VERSION ""

NS_ :

BS_:

BU_: AAF AAF_Tester ABS ACU ADRV AEMC AFLS AHLS APRK AVM BCM CAMERA CGW CLU CUBIS DATC DI_BOX Dummy ECS EMS EPB ESC EVP FATC FPCM FRONT_RADAR HUD IAP IBOX LCA LDWS_LKAS LPI LVR MDPS MTS ODS OPI PGS PSB REA SAS SCC SMK SNV SPAS TCU TMU TPMS _4WD

BS_:

BU_: XXX CAMERA FRONT_RADAR ADRV APRK

BS_:

BU_: IAP ODS _4WD BCM HUD DATC MDPS AAF_Tester AEMC SMK _4WD EPB CUBIS MTS TMU EVP CGW TPMS LPI DI_BOX SPAS EMS LCA TCU IBOX FATC AFLS FPCM SCC AHLS AVM ABS SNV OPI PGS SAS AAF Dummy LDWS_LKAS LVR ESC PSB CLU ECS ACU REA

BO_ 1318 HU_GW_E_00: 8 CLU
 SG_ C_ADrLURValueReq : 0|2@1+ (1.0,0.0) [0.0|3.0] ""  BCM
 SG_ C_TwUnRValueReq : 2|2@1+ (1.0,0.0) [0.0|3.0] ""  BCM
 SG_ C_AlarmRValueReq : 4|2@1+ (1.0,0.0) [0.0|3.0] ""  BCM
 SG_ C_IMSRValueReq : 6|2@1+ (1.0,0.0) [0.0|3.0] ""  BCM
 SG_ C_HLEscortRValueReq : 8|2@1+ (1.0,0.0) [0.0|3.0] ""  BCM
 SG_ C_WELRValueReq : 10|2@1+ (1.0,0.0) [0.0|3.0] ""  BCM
 SG_ C_TriTurnLRValueReq : 12|2@1+ (1.0,0.0) [0.0|3.0] ""  BCM
 SG_ C_SNVWarnRValueReq : 14|2@1+ (1.0,0.0) [0.0|3.0] ""  BCM
 SG_ C_LkasWarnRValueReq : 16|2@1+ (1.0,0.0) [0.0|3.0] ""  BCM

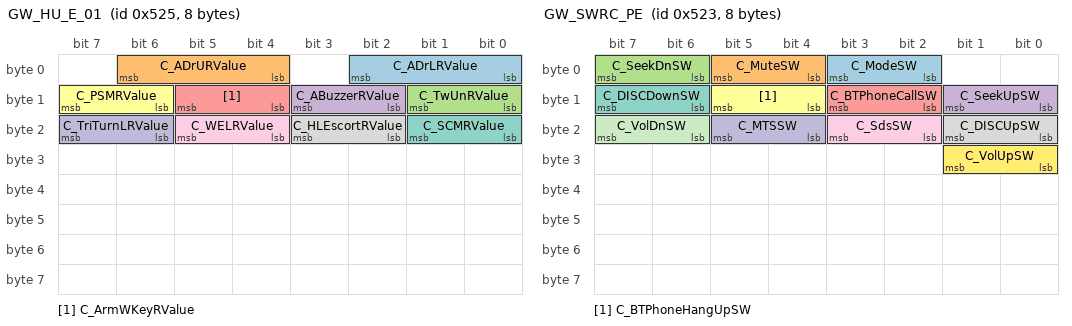
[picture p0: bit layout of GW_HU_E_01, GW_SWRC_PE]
BO_ 1317 GW_HU_E_01: 8 BCM
 SG_ C_ADrLRValue : 0|3@1+ (1.0,0.0) [0.0|7.0] ""  CLU
 SG_ C_ADrURValue : 4|3@1+ (1.0,0.0) [0.0|7.0] ""  CLU
 SG_ C_TwUnRValue : 8|2@1+ (1.0,0.0) [0.0|3.0] ""  CLU
 SG_ C_ABuzzerRValue : 10|2@1+ (1.0,0.0) [0.0|3.0] ""  CLU
 SG_ C_ArmWKeyRValue : 12|2@1+ (1.0,0.0) [0.0|3.0] ""  CLU
 SG_ C_PSMRValue : 14|2@1+ (1.0,0.0) [0.0|3.0] ""  CLU
 SG_ C_SCMRValue : 16|2@1+ (1.0,0.0) [0.0|3.0] ""  CLU
 SG_ C_HLEscortRValue : 18|2@1+ (1.0,0.0) [0.0|3.0] ""  CLU
 SG_ C_WELRValue : 20|2@1+ (1.0,0.0) [0.0|3.0] ""  CLU
 SG_ C_TriTurnLRValue : 22|2@1+ (1.0,0.0) [0.0|3.0] ""  CLU

BO_ 1316 GW_HU_E_00: 8 BCM
 SG_ C_ADrLUNValueConf : 0|2@1+ (1.0,0.0) [0.0|3.0] ""  CLU
 SG_ C_TwUnNValueConf : 2|2@1+ (1.0,0.0) [0.0|3.0] ""  CLU
 SG_ C_AlarmNValueConf : 4|2@1+ (1.0,0.0) [0.0|3.0] ""  CLU
 SG_ C_PSMNValueConf : 6|2@1+ (1.0,0.0) [0.0|3.0] ""  CLU
 SG_ C_SCMNValueConf : 8|2@1+ (1.0,0.0) [0.0|3.0] ""  CLU
 SG_ C_HLEscortNValueConf : 10|2@1+ (1.0,0.0) [0.0|3.0] ""  CLU
 SG_ C_WELNValueConf : 12|2@1+ (1.0,0.0) [0.0|3.0] ""  CLU
 SG_ C_TriTurnLNValueConf : 14|2@1+ (1.0,0.0) [0.0|3.0] ""  CLU

BO_ 1315 GW_SWRC_PE: 8 BCM
 SG_ C_ModeSW : 2|2@1+ (1.0,0.0) [0.0|3.0] ""  CLU
 SG_ C_MuteSW : 4|2@1+ (1.0,0.0) [0.0|3.0] ""  CLU
 SG_ C_SeekDnSW : 6|2@1+ (1.0,0.0) [0.0|3.0] ""  CLU
 SG_ C_SeekUpSW : 8|2@1+ (1.0,0.0) [0.0|3.0] ""  CLU
 SG_ C_BTPhoneCallSW : 10|2@1+ (1.0,0.0) [0.0|3.0] ""  CLU
 SG_ C_BTPhoneHangUpSW : 12|2@1+ (1.0,0.0) [0.0|3.0] ""  CLU
 SG_ C_DISCDownSW : 14|2@1+ (1.0,0.0) [0.0|3.0] ""  CLU
 SG_ C_DISCUpSW : 16|2@1+ (1.0,0.0) [0.0|3.0] ""  CLU
 SG_ C_SdsSW : 18|2@1+ (1.0,0.0) [0.0|3.0] ""  CLU
 SG_ C_MTSSW : 20|2@1+ (1.0,0.0) [0.0|3.0] ""  CLU
 SG_ C_VolDnSW : 22|2@1+ (1.0,0.0) [0.0|3.0] ""  CLU
 SG_ C_VolUpSW : 24|2@1+ (1.0,0.0) [0.0|3.0] ""  CLU

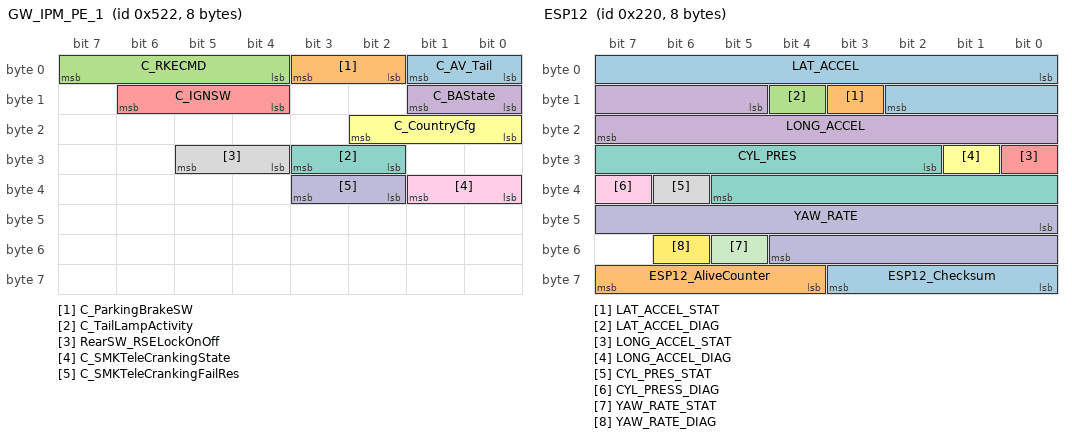
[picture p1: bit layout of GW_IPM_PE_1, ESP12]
BO_ 1314 GW_IPM_PE_1: 8 BCM
 SG_ C_AV_Tail : 0|2@1+ (1.0,0.0) [0.0|3.0] ""  CLU
 SG_ C_ParkingBrakeSW : 2|2@1+ (1.0,0.0) [0.0|3.0] ""  CLU
 SG_ C_RKECMD : 4|4@1+ (1.0,0.0) [0.0|15.0] ""  CLU
 SG_ C_BAState : 8|2@1+ (1.0,0.0) [0.0|3.0] ""  CLU
 SG_ C_IGNSW : 12|3@1+ (1.0,0.0) [0.0|7.0] ""  CLU
 SG_ C_CountryCfg : 16|3@1+ (1.0,0.0) [0.0|7.0] ""  CLU
 SG_ C_TailLampActivity : 26|2@1+ (1.0,0.0) [0.0|3.0] ""  CLU
 SG_ RearSW_RSELockOnOff : 28|2@1+ (1.0,0.0) [0.0|3.0] ""  CLU
 SG_ C_SMKTeleCrankingState : 32|2@1+ (1.0,0.0) [0.0|3.0] ""  CLU
 SG_ C_SMKTeleCrankingFailRes : 34|2@1+ (1.0,0.0) [0.0|3.0] ""  CLU

BO_ 1057 SCC12: 8 SCC
 SG_ CF_VSM_Prefill : 0|1@1+ (1,0) [0|1] "" ESC
 SG_ CF_VSM_DecCmdAct : 1|1@1+ (1,0) [0|1] "" ESC
 SG_ CF_VSM_HBACmd : 2|2@1+ (1,0) [0|3] "" ESC
 SG_ CF_VSM_Warn : 4|2@1+ (1,0) [0|3] "" CLU,ESC,IAP
 SG_ CF_VSM_Stat : 6|2@1+ (1,0) [0|3] "" CLU,ESC,PSB
 SG_ CF_VSM_BeltCmd : 8|3@1+ (1,0) [0|7] "" ESC,PSB
 SG_ ACCFailInfo : 11|2@1+ (1,0) [0|3] "" CLU,CUBIS,ESC,IBOX
 SG_ ACCMode : 13|2@1+ (1,0) [0|3] "" CLU,ESC,IBOX,TCU
 SG_ StopReq : 15|1@1+ (1,0) [0|1] "" EPB,ESC
 SG_ CR_VSM_DecCmd : 16|8@1+ (0.01,0) [0|2.55] "g" ESC
 SG_ TakeOverReq : 35|1@1+ (1,0) [0|1] "" CLU,ESC,TCU
 SG_ PreFill : 36|1@1+ (1,0) [0|1] "" ESC,TCU
 SG_ CF_VSM_ConfMode : 48|2@1+ (1,0) [0|3] "" CLU,ESC
 SG_ AEB_Failinfo : 50|2@1+ (1,0) [0|3] "" CLU,ESC
 SG_ AEB_Status : 52|2@1+ (1,0) [0|3] "" CLU,ESC
 SG_ AEB_CmdAct : 54|1@1+ (1,0) [0|1] "" ESC
 SG_ AEB_StopReq : 55|1@1+ (1,0) [0|1] "" CLU,ESC
 SG_ CR_VSM_Alive : 56|4@1+ (1,0) [0|15] "" ESC,PSB
 SG_ CR_VSM_ChkSum : 60|4@1+ (1,0) [0|15] "" ESC,PSB
 SG_ aReqValue : 37|11@1+ (0.01,-10.23) [-10.23|10.24] "m/s^2" Vector__XXX
 SG_ aReqRaw : 24|11@1+ (0.01,-10.23) [-10.23|10.24] "m/s^2" Vector__XXX

BO_ 1313 GW_DDM_PE: 8 BCM
 SG_ C_DRVDoorStatus : 0|2@1+ (1.0,0.0) [0.0|3.0] ""  CLU
 SG_ C_ASTDoorStatus : 2|2@1+ (1.0,0.0) [0.0|3.0] ""  CLU
 SG_ C_RLDoorStatus : 4|2@1+ (1.0,0.0) [0.0|3.0] ""  CLU
 SG_ C_RRDoorStatus : 6|2@1+ (1.0,0.0) [0.0|3.0] ""  CLU
 SG_ C_TrunkStatus : 8|2@1+ (1.0,0.0) [0.0|3.0] ""  CLU
 SG_ C_OSMirrorStatus : 10|2@1+ (1.0,0.0) [0.0|3.0] ""  CLU

BO_ 1056 SCC11: 8 SCC
 SG_ MainMode_ACC : 0|1@1+ (1,0) [0|1] "" CLU,EMS,ESC
 SG_ SCCInfoDisplay : 1|3@1+ (1,0) [0|7] "" CLU,ESC
 SG_ AliveCounterACC : 4|4@1+ (1,0) [0|15] "" CLU,EMS,ESC,TCU
 SG_ VSetDis : 8|8@1+ (1,0) [0|255] "km/h or MPH" CLU,ESC,TCU
 SG_ ObjValid : 16|1@1+ (1,0) [0|1] "" CLU,ESC,TCU
 SG_ DriverAlertDisplay : 17|2@1+ (1,0) [0|3] "" CLU,ESC
 SG_ TauGapSet : 19|3@1+ (1,0) [0|7] "" CLU,ESC,TCU
 SG_ Navi_SCC_Curve_Status : 56|2@1+ (1,0) [0|3] "" CLU
 SG_ Navi_SCC_Curve_Act : 58|2@1+ (1,0) [0|3] "" CLU
 SG_ Navi_SCC_Camera_Act : 60|2@1+ (1,0) [0|3] "" CLU
 SG_ Navi_SCC_Camera_Status : 62|2@1+ (1,0) [0|3] "" CLU
 SG_ ACC_ObjStatus : 22|2@1+ (1,0) [0|3] "" ABS,ESC
 SG_ ACC_ObjLatPos : 24|9@1+ (0.1,-20) [-20|31.1] "m" ABS,ESC
 SG_ ACC_ObjRelSpd : 44|12@1+ (0.1,-170) [-170|239.5] "m/s" ABS,ESC
 SG_ ACC_ObjDist : 33|11@1+ (0.1,0) [0|204.7] "m" ABS,ESC

BO_ 1312 CGW3: 8 BCM
 SG_ CR_Photosensor_LH : 0|8@1+ (78.125,0.0) [0.0|20000.0] ""  DATC,DATC
 SG_ CR_Photosensor_RH : 10|8@1+ (78.125,0.0) [0.0|20000.0] ""  DATC,DATC
 SG_ CF_Hoodsw_memory : 22|2@1+ (1.0,0.0) [0.0|3.0] ""  EMS,EMS
 SG_ C_MirOutTempSns : 24|8@1+ (0.5,-40.5) [-40.0|60.0] "deg"  AAF,CLU,DATC,EMS,SPAS,AAF,DATC,EMS,SPAS

BO_ 544 ESP12: 8 ESC
 SG_ LAT_ACCEL : 0|11@1+ (0.01,-10.23) [-10.23|10.24] "m/s^2"  _4WD,ECS,IBOX,LCA,LDWS_LKAS,MDPS,PSB,SCC,TCU
 SG_ LAT_ACCEL_STAT : 11|1@1+ (1.0,0.0) [0.0|1.0] ""  _4WD,IBOX,LDWS_LKAS,MDPS,PSB,SCC,TCU
 SG_ LAT_ACCEL_DIAG : 12|1@1+ (1.0,0.0) [0.0|1.0] ""  _4WD,IBOX,LDWS_LKAS,MDPS,PSB,SCC,TCU
 SG_ LONG_ACCEL : 13|11@1+ (0.01,-10.23) [-10.23|10.24] "m/s^2"  _4WD,ECS,EMS,EPB,IBOX,LCA,LDWS_LKAS,PSB,SCC,SPAS,TCU
 SG_ LONG_ACCEL_STAT : 24|1@1+ (1.0,0.0) [0.0|1.0] ""  _4WD,EMS,EPB,IBOX,LDWS_LKAS,PSB,SCC,SPAS,TCU
 SG_ LONG_ACCEL_DIAG : 25|1@1+ (1.0,0.0) [0.0|1.0] ""  _4WD,EMS,EPB,IBOX,LDWS_LKAS,PSB,SCC,SPAS,TCU
 SG_ CYL_PRES : 26|12@1+ (0.1,0.0) [0.0|409.5] "Bar"  _4WD,ECS,EMS,EPB,IBOX,LDWS_LKAS,PSB,SCC,TCU
 SG_ CYL_PRES_STAT : 38|1@1+ (1.0,0.0) [0.0|1.0] ""  _4WD,ECS,EMS,EPB,IBOX,LDWS_LKAS,PSB,SCC,TCU
 SG_ CYL_PRESS_DIAG : 39|1@1+ (1.0,0.0) [0.0|1.0] ""  _4WD,ECS,EMS,EPB,IBOX,PSB,SCC,TCU
 SG_ YAW_RATE : 40|13@1+ (0.01,-40.95) [-40.95|40.96] ""  _4WD,AFLS,IBOX,LCA,LDWS_LKAS,MDPS,PSB,SCC,SPAS,TCU
 SG_ YAW_RATE_STAT : 53|1@1+ (1.0,0.0) [0.0|1.0] ""  _4WD,AFLS,IBOX,LCA,LDWS_LKAS,MDPS,PSB,SCC,SPAS,TCU
 SG_ YAW_RATE_DIAG : 54|1@1+ (1.0,0.0) [0.0|1.0] ""  _4WD,AFLS,IBOX,LCA,LDWS_LKAS,MDPS,PSB,SCC,SPAS,TCU
 SG_ ESP12_Checksum : 56|4@1+ (1.0,0.0) [0.0|15.0] ""  _4WD,EMS,LPI,TCU,TMU
 SG_ ESP12_AliveCounter : 60|4@1+ (1.0,0.0) [0.0|15.0] ""  _4WD,EMS,LPI,TCU,TMU

BO_ 1307 CLU16: 8 CLU
 SG_ CF_Clu_TirePressUnitNValueSet : 0|3@1+ (1.0,0.0) [0.0|7.0] ""  TPMS
 SG_ CF_Clu_SlifNValueSet : 3|2@1+ (1.0,0.0) [0.0|3.0] ""  LDWS_LKAS
 SG_ CF_Clu_RearWiperNValueSet : 12|2@1+ (1.0,0.0) [0.0|3.0] ""  BCM

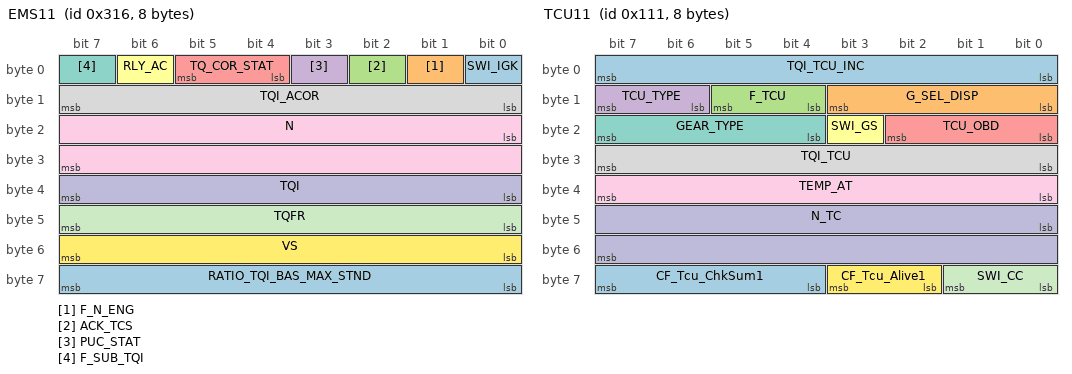
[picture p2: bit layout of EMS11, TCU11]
BO_ 790 EMS11: 8 EMS
 SG_ SWI_IGK : 0|1@1+ (1.0,0.0) [0.0|1.0] ""  _4WD,ABS,ACU,AHLS,CUBIS,DI_BOX,ECS,EPB,ESC,IBOX,LDWS_LKAS,MDPS,REA,SAS,SCC,TCU
 SG_ F_N_ENG : 1|1@1+ (1.0,0.0) [0.0|1.0] ""  _4WD,ACU,AFLS,CLU,CUBIS,DATC,ECS,EPB,ESC,IBOX,MDPS,SCC,TCU
 SG_ ACK_TCS : 2|1@1+ (1.0,0.0) [0.0|1.0] ""  ESC,IBOX
 SG_ PUC_STAT : 3|1@1+ (1.0,0.0) [0.0|1.0] ""  _4WD,CLU,DATC,IBOX,TCU
 SG_ TQ_COR_STAT : 4|2@1+ (1.0,0.0) [0.0|3.0] ""  _4WD,ESC,IBOX,TCU
 SG_ RLY_AC : 6|1@1+ (1.0,0.0) [0.0|1.0] ""  DATC,IBOX,TCU
 SG_ F_SUB_TQI : 7|1@1+ (1.0,0.0) [0.0|1.0] ""  _4WD,ECS,EPB,ESC,IBOX,TCU
 SG_ TQI_ACOR : 8|8@1+ (0.390625,0.0) [0.0|99.6094] "%"  _4WD,EPB,ESC,IBOX,TCU
 SG_ N : 16|16@1+ (0.25,0.0) [0.0|16383.75] "rpm"  _4WD,ACU,AFLS,CLU,CUBIS,DATC,ECS,EPB,ESC,FPCM,IBOX,MDPS,SCC,TCU
 SG_ TQI : 32|8@1+ (0.390625,0.0) [0.0|99.6094] "%"  _4WD,ECS,EPB,ESC,IBOX,TCU
 SG_ TQFR : 40|8@1+ (0.390625,0.0) [0.0|99.6094] "%"  _4WD,EPB,ESC,IBOX,TCU
 SG_ VS : 48|8@1+ (1.0,0.0) [0.0|254.0] "km/h"  _4WD,AAF,ACU,AHLS,BCM,CLU,DATC,ECS,EPB,IBOX,LCA,LDWS_LKAS,LVR,MDPS,ODS,SCC,SMK,SPAS,TCU,TPMS
 SG_ RATIO_TQI_BAS_MAX_STND : 56|8@1+ (0.0078,0.0) [0.0|2.0] ""  _4WD,IBOX,TCU

BO_ 1301 CLU14: 8 CLU
 SG_ CF_Clu_ADrUNValueSet : 0|3@1+ (1.0,0.0) [0.0|7.0] ""  BCM
 SG_ CF_Clu_ADrLNValueSet : 3|3@1+ (1.0,0.0) [0.0|7.0] ""  BCM
 SG_ CF_Clu_EscortHLNValueSet : 6|2@1+ (1.0,0.0) [0.0|3.0] ""  BCM
 SG_ CF_Clu_DoorLSNValueSet : 8|3@1+ (1.0,0.0) [0.0|7.0] ""  BCM
 SG_ CF_Clu_PSMNValueSet : 11|3@1+ (1.0,0.0) [0.0|7.0] ""  BCM
 SG_ CF_Clu_TTUnlockNValueSet : 14|2@1+ (1.0,0.0) [0.0|3.0] ""  BCM
 SG_ CF_Clu_PTGMNValueSet : 16|2@1+ (1.0,0.0) [0.0|3.0] ""  BCM
 SG_ CF_Clu_SCMNValueSet : 18|2@1+ (1.0,0.0) [0.0|3.0] ""  BCM
 SG_ CF_Clu_WlightNValueSet : 20|2@1+ (1.0,0.0) [0.0|3.0] ""  BCM
 SG_ CF_Clu_TempUnitNValueSet : 22|2@1+ (1.0,0.0) [0.0|3.0] ""  BCM,DATC
 SG_ CF_Clu_MoodLpNValueSet : 24|3@1+ (1.0,0.0) [0.0|7.0] ""  BCM
 SG_ CF_Clu_TrfChgSet : 27|2@1+ (1.0,0.0) [0.0|3.0] ""  AFLS
 SG_ CF_Clu_OTTurnNValueSet : 29|3@1+ (1.0,0.0) [0.0|7.0] ""  BCM
 SG_ CF_Clu_LcaNValueSet : 32|2@1+ (1.0,0.0) [0.0|3.0] ""  LCA
 SG_ CF_Clu_RctaNValueSet : 34|2@1+ (1.0,0.0) [0.0|3.0] ""  LCA
 SG_ CF_Clu_RcwNValueSet : 36|2@1+ (1.0,0.0) [0.0|3.0] ""  LCA
 SG_ CF_Clu_EscOffNValueSet : 38|3@1+ (1.0,0.0) [0.0|7.0] ""  ESC
 SG_ CF_Clu_SccNaviCrvNValueSet : 41|2@1+ (1.0,0.0) [0.0|3.0] ""  SCC
 SG_ CF_Clu_SccNaviCamNValueSet : 43|2@1+ (1.0,0.0) [0.0|3.0] ""  SCC
 SG_ CF_Clu_SccAebNValueSet : 45|2@1+ (1.0,0.0) [0.0|3.0] ""  SCC
 SG_ CF_Clu_LkasModeNValueSet : 47|2@1+ (1.0,0.0) [0.0|3.0] ""  LDWS_LKAS
 SG_ CF_Clu_FcwNValueSet : 51|2@1+ (1.0,0.0) [0.0|3.0] ""  LDWS_LKAS
 SG_ CF_Clu_PasSpkrLvNValueSet : 53|3@1+ (1.0,0.0) [0.0|7.0] ""  BCM
 SG_ CF_Clu_SccDrvModeNValueSet : 56|3@1+ (1.0,0.0) [0.0|7.0] ""  SCC
 SG_ CF_Clu_HAnBNValueSet : 59|2@1+ (1.0,0.0) [0.0|3.0] ""  BCM
 SG_ CF_Clu_HfreeTrunkTgNValueSet : 61|3@1+ (1.0,0.0) [0.0|7.0] ""  BCM

BO_ 275 TCU13: 8 TCU
 SG_ N_TGT_LUP : 0|8@1+ (10.0,500.0) [500.0|3040.0] "rpm"  EMS,IBOX
 SG_ SLOPE_TCU : 8|6@1+ (0.5,-16.0) [-16.0|15.5] "%"  CLU,CUBIS,EMS,IBOX
 SG_ CF_Tcu_InhCda : 14|1@1+ (1.0,0.0) [0.0|1.0] ""  EMS,IBOX
 SG_ CF_Tcu_IsgInhib : 15|1@1+ (1.0,0.0) [0.0|1.0] ""  EMS,IBOX
 SG_ CF_Tcu_BkeOnReq : 16|2@1+ (1.0,0.0) [0.0|3.0] ""  EMS,IBOX
 SG_ CF_Tcu_NCStat : 18|2@1+ (1.0,0.0) [0.0|3.0] ""  EMS,IBOX
 SG_ CF_Tcu_TarGr : 20|4@1+ (1.0,0.0) [0.0|15.0] ""  _4WD,CLU,DATC,EMS,EPB,ESC,IBOX,SCC
 SG_ CF_Tcu_ShfPatt : 24|4@1+ (1.0,0.0) [0.0|15.0] ""  CLU,CUBIS,EMS,IBOX
 SG_ CF_Tcu_InhVis : 28|1@1+ (1.0,0.0) [0.0|1.0] ""  EMS,IBOX
 SG_ CF_Tcu_PRelReq : 29|1@1+ (1.0,0.0) [0.0|1.0] ""  IBOX,LVR
 SG_ CF_Tcu_ITPhase : 30|1@1+ (1.0,0.0) [0.0|1.0] ""  EMS,IBOX
 SG_ CF_Tcu_ActEcoRdy : 31|1@1+ (1.0,0.0) [0.0|1.0] ""  EMS,IBOX
 SG_ CF_Tcu_TqGrdLim : 32|8@1+ (10.0,0.0) [0.0|2540.0] "Nm/s"  EMS,IBOX
 SG_ CR_Tcu_IsgTgtRPM : 40|8@1+ (20.0,0.0) [0.0|3500.0] "rpm"  EMS,IBOX
 SG_ CF_Tcu_SptRdy : 48|1@1+ (1.0,0.0) [0.0|1.0] ""  CLU,IBOX
 SG_ CF_Tcu_SbwPInfo : 56|1@1+ (1.0,0.0) [0.0|1.0] ""  EMS,IBOX
 SG_ CF_Tcu_Alive3 : 58|2@1+ (1.0,0.0) [0.0|3.0] ""  EMS,IBOX
 SG_ CF_Tcu_ChkSum3 : 60|4@1+ (1.0,0.0) [0.0|15.0] ""  EMS,IBOX

BO_ 274 TCU12: 8 TCU
 SG_ ETL_TCU : 0|8@1+ (2.0,0.0) [0.0|508.0] "Nm"  EMS,IBOX
 SG_ CUR_GR : 8|4@1+ (1.0,0.0) [0.0|15.0] ""  _4WD,EMS,ESC,IBOX,SCC,TPMS
 SG_ CF_Tcu_Alive : 12|2@1+ (1.0,0.0) [0.0|3.0] ""  EMS,ESC,IBOX,SCC
 SG_ CF_Tcu_ChkSum : 14|2@1+ (1.0,0.0) [0.0|3.0] ""  EMS,ESC,IBOX,SCC
 SG_ VS_TCU : 16|8@1+ (1.0,0.0) [0.0|254.0] "km/h"  BCM,CLU,DATC,EMS,IBOX,LCA,LVR,PGS,SMK,SNV
 SG_ FUEL_CUT_TCU : 28|1@1+ (1.0,0.0) [0.0|1.0] ""  EMS,IBOX
 SG_ INH_FUEL_CUT : 29|1@1+ (1.0,0.0) [0.0|1.0] ""  EMS,IBOX
 SG_ IDLE_UP_TCU : 30|1@1+ (1.0,0.0) [0.0|1.0] ""  EMS,IBOX
 SG_ N_INC_TCU : 31|1@1+ (1.0,0.0) [0.0|1.0] ""  EMS,IBOX
 SG_ SPK_RTD_TCU : 32|8@1+ (0.375,-23.625) [-15.0|15.0] ""  EMS,IBOX
 SG_ N_TC_RAW : 40|16@1+ (0.25,0.0) [0.0|16383.5] "rpm"  EMS,IBOX
 SG_ VS_TCU_DECIMAL : 56|8@1+ (0.0078125,0.0) [0.0|0.9921875] "km/h"  CLU,EMS,IBOX,LCA

BO_ 273 TCU11: 8 TCU
 SG_ TQI_TCU_INC : 0|8@1+ (0.390625,0.0) [0.0|99.609375] "%"  EMS,ESC,IBOX
 SG_ G_SEL_DISP : 8|4@1+ (1.0,0.0) [0.0|15.0] ""  _4WD,AFLS,AVM,BCM,CGW,CLU,CUBIS,ECS,EMS,EPB,ESC,IAP,IBOX,LCA,LDWS_LKAS,LVR,MDPS,PGS,SCC,SMK,SNV,SPAS,TPMS
 SG_ F_TCU : 12|2@1+ (1.0,0.0) [0.0|3.0] ""  EMS,ESC,IBOX
 SG_ TCU_TYPE : 14|2@1+ (1.0,0.0) [0.0|3.0] ""  _4WD,EMS,ESC,IBOX
 SG_ TCU_OBD : 16|3@1+ (1.0,0.0) [0.0|7.0] ""  EMS,ESC,IBOX
 SG_ SWI_GS : 19|1@1+ (1.0,0.0) [0.0|1.0] ""  _4WD,EMS,EPB,ESC,IBOX,SCC
 SG_ GEAR_TYPE : 20|4@1+ (1.0,0.0) [0.0|15.0] ""  _4WD,CLU,EMS,ESC,IBOX,SCC
 SG_ TQI_TCU : 24|8@1+ (0.390625,0.0) [0.0|99.609375] "%"  EMS,ESC,IBOX
 SG_ TEMP_AT : 32|8@1+ (1.0,-40.0) [-40.0|214.0] "deg"  AAF,CLU,CUBIS,EMS,ESC,IBOX
 SG_ N_TC : 40|16@1+ (0.25,0.0) [0.0|16383.5] "rpm"  _4WD,EMS,EPB,ESC,IBOX
 SG_ SWI_CC : 56|2@1+ (1.0,0.0) [0.0|3.0] ""  _4WD,CLU,EMS,ESC,IBOX
 SG_ CF_Tcu_Alive1 : 58|2@1+ (1.0,0.0) [0.0|3.0] ""  EMS,IBOX
 SG_ CF_Tcu_ChkSum1 : 60|4@1+ (1.0,0.0) [0.0|15.0] ""  EMS,IBOX

BO_ 16 ACU13: 8 ACU
 SG_ CF_Acu_CshAct : 0|1@1+ (1.0,0.0) [0.0|1.0] ""  CUBIS,IBOX,ODS

BO_ 1040 CGW_USM1: 8 BCM
 SG_ CF_Gway_ATTurnRValue : 0|2@1+ (1.0,0.0) [0.0|3.0] ""  CLU
 SG_ CF_Gway_PTGMRValue : 2|2@1+ (1.0,0.0) [0.0|3.0] ""  CLU
 SG_ CF_Gway_EscortHLRValue : 4|2@1+ (1.0,0.0) [0.0|3.0] ""  CLU
 SG_ CF_Gway_TTUnlockRValue : 6|2@1+ (1.0,0.0) [0.0|3.0] ""  CLU
 SG_ CF_Gway_ADrLRValue : 8|3@1+ (1.0,0.0) [0.0|7.0] ""  CLU
 SG_ CF_Gway_ADrURValue : 11|3@1+ (1.0,0.0) [0.0|7.0] ""  CLU
 SG_ CF_Gway_SCMRValue : 14|2@1+ (1.0,0.0) [0.0|3.0] ""  CLU
 SG_ CF_Gway_WlightRValue : 16|2@1+ (1.0,0.0) [0.0|3.0] ""  CLU
 SG_ CF_Gway_PSMRValue : 18|3@1+ (1.0,0.0) [0.0|7.0] ""  CLU
 SG_ CF_Gway_OTTurnRValue : 21|3@1+ (1.0,0.0) [0.0|7.0] ""  CLU
 SG_ CF_Gway_DrLockSoundRValue : 24|3@1+ (1.0,0.0) [0.0|7.0] ""  CLU
 SG_ CF_Gway_HAnBRValue : 27|3@1+ (1.0,0.0) [0.0|7.0] ""  CLU
 SG_ CF_Gway_MoodLpRValue : 30|2@1+ (1.0,0.0) [0.0|3.0] ""  CLU
 SG_ CF_Gway_HfreeTrunkRValue : 32|3@1+ (1.0,0.0) [0.0|7.0] ""  CLU
 SG_ CF_Gway_AutoLightRValue : 35|3@1+ (1.0,0.0) [0.0|7.0] ""  CLU
 SG_ CF_Gway_RearWiperRValue : 38|2@1+ (1.0,0.0) [0.0|3.0] ""  CLU
 SG_ CF_Gway_PasSpkrLvRValue : 40|3@1+ (1.0,0.0) [0.0|7.0] ""  CLU

BO_ 1292 CLU13: 8 CLU
 SG_ CF_Clu_LowfuelWarn : 0|2@1+ (1.0,0.0) [0.0|3.0] ""  BCM,FPCM,IBOX
 SG_ CF_Clu_RefDetMod : 2|1@1+ (1.0,0.0) [0.0|1.0] ""  IBOX
 SG_ CF_Clu_AvgFCU : 3|2@1+ (1.0,0.0) [0.0|3.0] ""  IBOX
 SG_ CF_Clu_AvsmCur : 5|1@1+ (1.0,0.0) [0.0|1.0] ""  ESC,SCC
 SG_ CF_Clu_AvgFCI : 6|10@1+ (0.1,0.0) [0.0|102.2] ""  IBOX
 SG_ CF_Clu_DrivingModeSwi : 16|2@1+ (1.0,0.0) [0.0|3.0] ""  DATC,ECS,EMS,ESC,IAP,MDPS,TCU
 SG_ CF_Clu_FuelDispLvl : 18|5@1+ (1.0,0.0) [0.0|31.0] ""  CGW,IBOX
 SG_ CF_Clu_FlexSteerSW : 23|1@1+ (1.0,0.0) [0.0|1.0] ""  MDPS
 SG_ CF_Clu_DTE : 24|10@1+ (1.0,0.0) [0.0|1023.0] ""  DATC
 SG_ CF_Clu_TripUnit : 34|2@1+ (1.0,0.0) [0.0|3.0] ""  DATC
 SG_ CF_Clu_SWL_Stat : 36|3@1+ (1.0,0.0) [0.0|7.0] ""  ACU,EMS
 SG_ CF_Clu_ActiveEcoSW : 39|1@1+ (1.0,0.0) [0.0|1.0] ""  DATC,EMS,TCU
 SG_ CF_Clu_EcoDriveInf : 40|3@1+ (1.0,0.0) [0.0|7.0] ""  CUBIS,EMS,IAP,IBOX
 SG_ CF_Clu_IsaMainSW : 43|1@1+ (1.0,0.0) [0.0|1.0] ""  EMS
 SG_ CF_Clu_LdwsLkasSW : 56|1@1+ (1.0,0.0) [0.0|1.0] ""  LDWS_LKAS
 SG_ CF_Clu_AltLStatus : 59|1@1+ (1.0,0.0) [0.0|1.0] ""  BCM,DATC,EMS
 SG_ CF_Clu_AliveCnt2 : 60|4@1+ (1.0,0.0) [0.0|15.0] ""  EMS,LDWS_LKAS

BO_ 1290 SCC13: 8 SCC
 SG_ SCCDrvModeRValue : 0|3@1+ (1,0) [0|7] "" CLU
 SG_ SCC_Equip : 3|1@1+ (1,0) [0|1] "" ESC
 SG_ AebDrvSetStatus : 4|3@1+ (1,0) [0|7] "" CLU,ESC
 SG_ Lead_Veh_Dep_Alert_USM : 13|2@0+ (1,0) [0|3] "" XXX

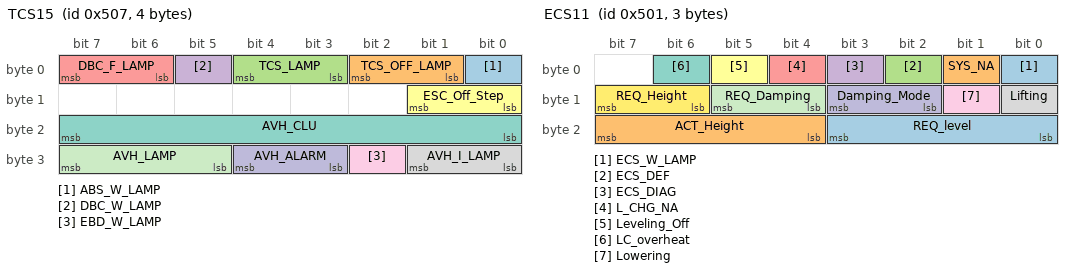
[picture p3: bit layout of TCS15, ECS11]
BO_ 1287 TCS15: 4 ESC
 SG_ ABS_W_LAMP : 0|1@1+ (1.0,0.0) [0.0|1.0] ""  _4WD,CLU,CUBIS,IBOX
 SG_ TCS_OFF_LAMP : 1|2@1+ (1.0,0.0) [0.0|1.0] ""  _4WD,ACU,CLU
 SG_ TCS_LAMP : 3|2@1+ (1.0,0.0) [0.0|3.0] ""  _4WD,ACU,CLU,CUBIS,IBOX,SCC
 SG_ DBC_W_LAMP : 5|1@1+ (1.0,0.0) [0.0|1.0] ""  _4WD,CLU
 SG_ DBC_F_LAMP : 6|2@1+ (1.0,0.0) [0.0|3.0] ""  _4WD,CLU
 SG_ ESC_Off_Step : 8|2@1+ (1.0,0.0) [0.0|3.0] ""  CLU
 SG_ AVH_CLU : 16|8@1+ (1.0,0.0) [0.0|255.0] ""  CLU,EPB
 SG_ AVH_I_LAMP : 24|2@1+ (1.0,0.0) [0.0|3.0] ""  EPB
 SG_ EBD_W_LAMP : 26|1@1+ (1.0,0.0) [0.0|1.0] ""  _4WD,CLU
 SG_ AVH_ALARM : 27|2@1+ (1.0,0.0) [0.0|3.0] ""  CLU
 SG_ AVH_LAMP : 29|3@1+ (1.0,0.0) [0.0|7.0] ""  CLU,EPB,SPAS

BO_ 1282 TCU14: 4 TCU
 SG_ CF_TCU_WarnMsg : 0|3@1+ (1.0,0.0) [0.0|7.0] ""  CLU
 SG_ CF_TCU_WarnImg : 3|1@1+ (1.0,0.0) [0.0|1.0] ""  CLU
 SG_ CF_TCU_WarnSnd : 4|1@1+ (1.0,0.0) [0.0|1.0] ""  CLU
 SG_ CF_Tcu_GSel_BlinkReq : 5|1@1+ (1.0,0.0) [0.0|1.0] ""  CLU,LVR
 SG_ CF_Tcu_StRelStat : 12|1@1+ (1.0,0.0) [0.0|1.0] ""  CLU,EMS,ESC
 SG_ CF_Tcu_DriWarn1 : 13|3@1+ (1.0,0.0) [0.0|7.0] ""  CLU,EMS,ESC
 SG_ CF_Tcu_DriWarn2 : 16|2@1+ (1.0,0.0) [0.0|3.0] ""  CLU,EMS,ESC

BO_ 1281 ECS11: 3 ECS
 SG_ ECS_W_LAMP : 0|1@1+ (1.0,0.0) [0.0|1.0] ""  CLU,CUBIS,IBOX
 SG_ SYS_NA : 1|1@1+ (1.0,0.0) [0.0|1.0] ""  CLU
 SG_ ECS_DEF : 2|1@1+ (1.0,0.0) [0.0|1.0] ""  CLU
 SG_ ECS_DIAG : 3|1@1+ (1.0,0.0) [0.0|1.0] ""  CLU
 SG_ L_CHG_NA : 4|1@1+ (1.0,0.0) [0.0|1.0] ""  CLU
 SG_ Leveling_Off : 5|1@1+ (1.0,0.0) [0.0|1.0] ""  CLU
 SG_ LC_overheat : 6|1@1+ (1.0,0.0) [0.0|1.0] ""  CLU
 SG_ Lifting : 8|1@1+ (1.0,0.0) [0.0|1.0] ""  CLU
 SG_ Lowering : 9|1@1+ (1.0,0.0) [0.0|1.0] ""  CLU
 SG_ Damping_Mode : 10|2@1+ (1.0,0.0) [0.0|3.0] ""  CLU
 SG_ REQ_Damping : 12|2@1+ (1.0,0.0) [0.0|3.0] ""  CLU
 SG_ REQ_Height : 14|2@1+ (1.0,0.0) [0.0|3.0] ""  CLU
 SG_ REQ_level : 16|4@1+ (1.0,0.0) [0.0|15.0] ""  CLU
 SG_ ACT_Height : 20|4@1+ (1.0,0.0) [0.0|15.0] ""  CLU

BO_ 1024 CLU_CFG11: 2 CLU
 SG_ Vehicle_Type : 0|16@1+ (1.0,0.0) [0.0|65536.0] ""  _4WD

BO_ 1280 ACU14: 1 ACU
 SG_ CF_SWL_Ind : 0|2@1+ (1.0,0.0) [0.0|3.0] ""  CLU
 SG_ CF_TTL_Ind : 2|2@1+ (1.0,0.0) [0.0|3.0] ""  CLU
 SG_ CF_SBR_Ind : 4|2@1+ (1.0,0.0) [0.0|3.0] ""  BCM,CLU

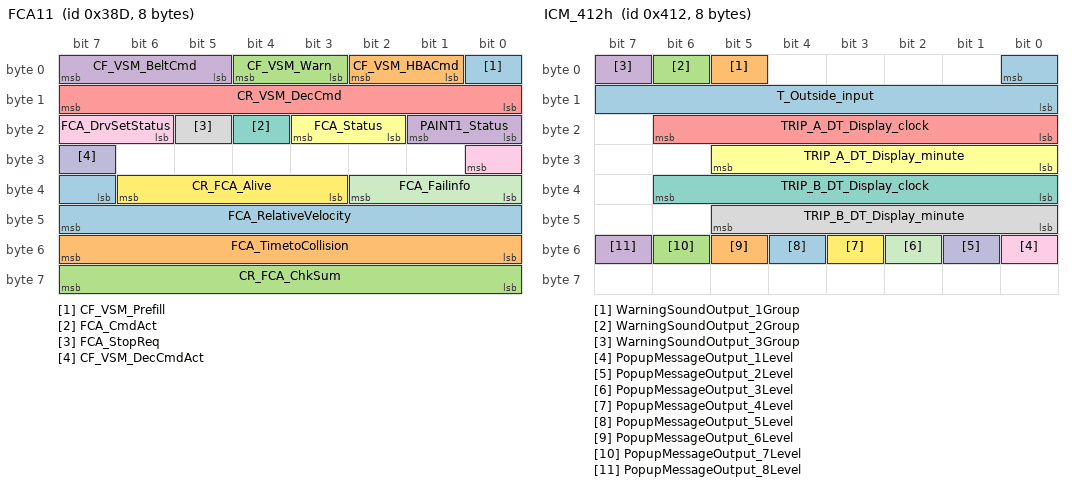
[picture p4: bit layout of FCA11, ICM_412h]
BO_ 909 FCA11: 8 FCA
 SG_ CF_VSM_Prefill : 0|1@1+ (1,0) [0|1] "" ESC
 SG_ CF_VSM_HBACmd : 1|2@1+ (1,0) [0|3] "" ESC
 SG_ CF_VSM_Warn : 3|2@1+ (1,0) [0|3] "" ACU,CLU,ESC
 SG_ CF_VSM_BeltCmd : 5|3@1+ (1,0) [0|7] "" ESC
 SG_ CR_VSM_DecCmd : 8|8@1+ (0.01,0) [0|2.55] "g" ESC
 SG_ FCA_Status : 18|2@1+ (1,0) [0|3] "" ACU,CLU,ESC
 SG_ FCA_CmdAct : 20|1@1+ (1,0) [0|1] "" ESC
 SG_ FCA_StopReq : 21|1@1+ (1,0) [0|1] "" CLU,ESC
 SG_ FCA_DrvSetStatus : 22|3@1+ (1,0) [0|7] "" CLU,ESC
 SG_ CF_VSM_DecCmdAct : 31|1@1+ (1,0) [0|1] "" ESC
 SG_ FCA_Failinfo : 32|3@1+ (1,0) [0|7] "" ACU,CLU,ESC
 SG_ CR_FCA_Alive : 35|4@1+ (1,0) [0|15] "" ESC
 SG_ FCA_RelativeVelocity : 39|9@1+ (0.1,-25.5) [-25.5|25.5] "m/s" iBAU
 SG_ FCA_TimetoCollision : 48|8@1+ (10,0) [0|2540] "ms" iBAU
 SG_ CR_FCA_ChkSum : 56|8@1+ (1,0) [0|255] "" ESC
 SG_ PAINT1_Status : 16|2@1+ (1,0) [0|1] "" XXX

BO_ 1156 HDA11_MFC: 8 XXX
 SG_ Counter : 5|4@0+ (1,0) [0|15] "" XXX
 SG_ NEW_SIGNAL_1 : 1|2@0+ (1,0) [0|255] "" XXX
 SG_ NEW_SIGNAL_2 : 7|2@0+ (1,0) [0|3] "" XXX
 SG_ NEW_SIGNAL_3 : 15|8@0+ (1,0) [0|255] "" XXX
 SG_ NEW_SIGNAL_4 : 16|2@1+ (1,0) [0|3] "" XXX
 SG_ NEW_SIGNAL_5 : 18|14@1+ (1,0) [0|63] "" XXX
 SG_ NEW_SIGNAL_6 : 33|2@0+ (1,0) [0|1] "" XXX
 SG_ NEW_SIGNAL_7 : 34|14@1+ (1,0) [0|16383] "" XXX
 SG_ NEW_SIGNAL_8 : 49|2@0+ (1,0) [0|1] "" XXX
 SG_ NEW_SIGNAL_9 : 50|14@1- (1,-4095) [0|16383] "" XXX

BO_ 1155 FCA12: 8 FCA
 SG_ FCA_USM : 0|3@1+ (1,0) [0|7] "" CGW,CLU,ESC
 SG_ FCA_DrvSetState : 3|3@1+ (1,0) [0|7] "" CGW

BO_ 1186 FRT_RADAR11: 2 FCA
 SG_ CF_FCA_Equip_Front_Radar : 0|3@1+ (1,0) [0|7] "" LDWS_LKAS,LDW_LKA,ESC

BO_ 905 SCC14: 8 SCC
 SG_ ComfortBandUpper : 0|6@1+ (0.02,0) [0|1.26] "m/s^2" ESC
 SG_ ComfortBandLower : 6|6@1+ (0.02,0) [0|1.26] "m/s^2" ESC
 SG_ JerkUpperLimit : 12|7@1+ (0.1,0) [0|12.7] "m/s^3" ESC
 SG_ JerkLowerLimit : 19|7@1+ (0.1,0) [0|12.7] "m/s^3" ESC
 SG_ ACCMode : 32|3@1+ (1,0) [0|7] "" CLU,HUD,LDWS_LKAS,ESC
 SG_ ObjDistStat : 42|2@1+ (1,0) [0|3] "" XXX
 SG_ ObjGap : 56|8@1+ (1,0) [0|255] "" CLU,HUD,ESC

BO_ 1157 LFAHDA_MFC: 4 XXX
 SG_ HDA_USM : 0|2@1+ (1,0) [0|3] "" XXX
 SG_ HDA_Active : 2|1@1+ (1,0) [0|1] "" XXX
 SG_ HDA_Icon_State : 3|2@1+ (1,0) [0|3] "" XXX
 SG_ HDA_Chime : 7|1@1+ (1,0) [0|1] "" XXX
 SG_ HDA_VSetReq : 8|8@1+ (1,0) [0|255] "km/h" XXX
 SG_ LFA_SysWarning : 16|3@1+ (1,0) [0|7] "" XXX
 SG_ NEW_SIGNAL_1 : 20|3@1+ (1,0) [0|7] "" XXX
 SG_ LFA_Icon_State : 24|2@1+ (1,0) [0|3] "" XXX
 SG_ LFA_USM : 27|2@1+ (1,0) [0|3] "" XXX
 SG_ HDA_SysWarning : 29|2@1+ (1,0) [0|3] "" XXX

BO_ 913 BCM_PO_11: 8 Vector__XXX
 SG_ BCM_Door_Dri_Status : 5|1@0+ (1,0) [0|1] "" PT_ESC_ABS
 SG_ BCM_Shift_R_MT_SW_Status : 39|2@0+ (1,0) [0|3] "" PT_ESC_ABS
 SG_ LFA_Pressed : 4|1@0+ (1,0) [0|1] "" XXX

BO_ 1426 LABEL11: 8 XXX
 SG_ CC_React : 34|1@1+ (1,0) [0|1] "" XXX

BO_ 910 WHL_SPD12_FS: 5 iBAU
 SG_ CRC : 0|8@1+ (1,0) [0|0] "" Vector__XXX
 SG_ WHL_SPD12_AliveCounter : 8|4@1+ (1,0) [0|15] "" Vector__XXX
 SG_ WHL_SPD_FL : 12|14@1+ (0.03125,0) [0|511.96875] "km/h" Vector__XXX
 SG_ WHL_SPD_FR : 26|14@1+ (0.03125,0) [0|511.96875] "km/h" Vector__XXX

BO_ 911 WHL_SPD13_FS: 5 iBAU
 SG_ CRC : 0|8@1+ (1,0) [0|0] "" Vector__XXX
 SG_ WHL_SPD13_AliveCounter : 8|4@1+ (1,0) [0|15] "" Vector__XXX
 SG_ WHL_SPD_RL : 12|14@1+ (0.03125,0) [0|511.96875] "km/h" Vector__XXX
 SG_ WHL_SPD_RR : 26|14@1+ (0.03125,0) [0|511.96875] "km/h" Vector__XXX

BO_ 865 ADAS_PRK_11: 8 ADAS_PRK
 SG_ CF_PCA_BrkReq : 24|1@1+ (1,0) [0|0] "" Vector__XXX
 SG_ CF_PCA_DclTrgtVal : 28|4@1+ (0.04,0) [0|0] "g" Vector__XXX
 SG_ PCA_ALIVE_CNT : 40|4@1+ (1,0) [0|0] "" Vector__XXX
 SG_ PCA_CHECK_SUM : 48|8@1+ (1,0) [0|0] "" Vector__XXX

BO_ 882 ELECT_GEAR: 8 XXX
 SG_ Elect_Gear_Shifter : 16|4@1+ (1,0) [0|7] ""  CLU

BO_ 881 E_EMS11: 8 XXX
 SG_ Brake_Pedal_Pos : 0|8@1+ (1,0) [0|127] "" XXX
 SG_ IG_Reactive_Stat : 8|3@1+ (1,0) [0|3] "" XXX
 SG_ Gear_Change : 12|1@0+ (1,0) [0|31] "" XXX
 SG_ Cruise_Limit_Status : 13|1@1+ (1,0) [0|1] "" XXX
 SG_ Cruise_Limit_Target : 23|8@1+ (1,0) [0|15] "" XXX
 SG_ Accel_Pedal_Pos : 31|8@1+ (1,0) [0|254] "" XXX
 SG_ CR_Vcu_AccPedDep_Pos : 56|8@1+ (1,0) [0|254] "" XXX

BO_ 1355 EV_PC6: 8 CGW
 SG_ CF_Vcu_SbwWarnMsg : 16|3@1+ (1,0) [0|7] "" Vector__XXX

BO_ 1430 EV_PC2: 8 CGW
 SG_ CR_Ldc_ActVol_LS_V : 32|8@1+ (0.1,0) [0|0] "V" Vector__XXX

BO_ 1535 EV_PC10: 8 CGW
 SG_ CF_Vcu_EpbRequest : 37|1@1+ (1,0) [0|0] "" Vector__XXX

BO_ 908 RSPA11: 8 RSPA
 SG_ CF_RSPA_State : 0|4@1+ (1,0) [0|15] "" XXX
 SG_ CF_RSPA_Act : 4|2@1+ (1,0) [0|3] "" XXX
 SG_ CF_RSPA_DecCmd : 6|2@1+ (1,0) [0|3] "" XXX
 SG_ CF_RSPA_Trgt_Spd : 8|10@1+ (0.01,0) [0|10.23] "km/h" XXX
 SG_ CF_RSPA_StopReq : 18|1@1+ (1,0) [0|2] "" XXX
 SG_ CR_RSPA_EPB_Req : 22|2@1+ (1,0) [0|3] "" XXX
 SG_ CF_RSPA_ACC_ACT : 50|1@1+ (1,0) [0|2] "" XXX
 SG_ CF_RSPA_AliveCounter : 52|4@1+ (1,0) [0|15] "" XXX
 SG_ CF_RSPA_CRC : 56|8@1+ (1,0) [0|255] "" XXX

BO_ 914 S_MDPS11: 8 XXX
 SG_ CF_Mdps_Stat : 0|4@1+ (1,0) [0|15] "" XXX
 SG_ CR_Mdps_DrvTq : 8|12@1+ (1,0) [0|15] "" XXX
 SG_ CR_Mdps_StrAng : 24|16@1- (1,0) [0|65535] "" XXX
 SG_ CF_Mdps_AliveCnt : 47|8@0+ (1,0) [0|255] "" XXX
 SG_ CF_Mdps_Chksum : 63|8@0+ (1,0) [0|255] "" XXX

BO_ 1191 MFC_4a7: 8 XXX
 SG_ PAINT1 : 0|1@0+ (1,0) [0|1] "" XXX

BO_ 1162 BCA11: 8 BCW
 SG_ CF_BCA_State : 16|3@1+ (1,0) [0|7] "" CLU,iBAU
 SG_ CF_BCA_Warning : 19|2@1+ (1,0) [0|3] "" CLU,iBAU
 SG_ AliveCounter : 21|4@1+ (1,0) [0|15] "" CLU,iBAU
 SG_ RCCA_Brake_Command : 29|1@1+ (1,0) [0|1] "" iBAU
 SG_ Check_Sum : 56|8@1+ (1,0) [0|16] "" iBAU

BO_ 1136 P_STS: 8 CGW
 SG_ HCU1_STS : 6|2@1+ (1,0) [0|3] "" BCW,EPB,FCA,MDPS,SCC,iBAU
 SG_ HCU5_STS : 8|2@1+ (1,0) [0|3] "" EPB,FCA,MDPS,iBAU
 SG_ Counter : 58|4@1+ (1,0) [0|15] "" MDPS
 SG_ Checksum : 62|2@1+ (1,0) [0|3] "" MDPS

BO_ 320 YRS12: 8 ACU
 SG_ CF_Yrs_LongAcStat : 16|4@1+ (1,0) [0|15] "" iBAU
 SG_ CF_IMU_ResetStat : 20|4@1+ (1,0) [0|15] "" iBAU
 SG_ YRS_Temp : 24|8@1+ (1,-68) [-68|187] "" iBAU
 SG_ YRS_TempStat : 32|4@1+ (1,0) [0|15] "" iBAU
 SG_ CF_Yrs_Type : 36|4@1+ (1,0) [0|15] "" iBAU
 SG_ CR_Yrs_MsgCnt2 : 48|4@1+ (1,0) [0|15] "" iBAU
 SG_ CR_Yrs_Crc2 : 56|8@1+ (1,0) [0|255] "" iBAU
 SG_ CR_Yrs_LongAc : 0|16@1+ (0.000127465,-4.17677312) [-4.17677312|4.17651819] "g" CGW,iBAU

BO_ 1173 YRS13: 8 ACU
 SG_ YRS_SeralNo : 16|48@1+ (1,0) [0|281474976710655] "" iBAU

BO_ 870 EMS_366: 8 EMS
 SG_ TQI_1 : 0|8@1+ (0.390625,0) [0|99.6094] "%" MDPS
 SG_ N : 8|16@1+ (0.25,0.0) [0.0|16383.75] "rpm" MDPS
 SG_ TQI_2 : 24|8@1+ (0.390625,0) [0|99.6094] "%" MDPS
 SG_ VS : 40|8@1+ (1,0) [0|255] "km/h" MDPS
 SG_ SWI_IGK : 48|1@0+ (1,0) [0|1] "" XXX

BO_ 854 M_356: 8 XXX
 SG_ PAINT1 : 32|1@0+ (1,0) [0|1] "" XXX
 SG_ PAINT2 : 34|2@0+ (1,0) [0|1] "" XXX
 SG_ PAINT3 : 36|2@0+ (1,0) [0|3] "" XXX
 SG_ PAINT4 : 38|1@0+ (1,0) [0|1] "" XXX

BO_ 1042 ICM_412h: 8 ICM
 SG_ T_Outside_input : 0|9@0+ (0.01,0) [0|5] "V" Vector__XXX
 SG_ WarningSoundOutput_1Group : 5|1@0+ (1,0) [0|1] "" Vector__XXX
 SG_ WarningSoundOutput_2Group : 6|1@0+ (1,0) [0|1] "" Vector__XXX
 SG_ WarningSoundOutput_3Group : 7|1@0+ (1,0) [0|1] "" Vector__XXX
 SG_ TRIP_A_DT_Display_clock : 22|7@0+ (1,0) [0|99] "clock" Vector__XXX
 SG_ TRIP_A_DT_Display_minute : 29|6@0+ (1,0) [0|59] "minute" Vector__XXX
 SG_ TRIP_B_DT_Display_clock : 38|7@0+ (1,0) [0|99] "clock" Vector__XXX
 SG_ TRIP_B_DT_Display_minute : 45|6@0+ (1,0) [0|59] "minute" Vector__XXX
 SG_ PopupMessageOutput_1Level : 48|1@0+ (1,0) [0|1] "" Vector__XXX
 SG_ PopupMessageOutput_2Level : 49|1@0+ (1,0) [0|1] "" Vector__XXX
 SG_ PopupMessageOutput_3Level : 50|1@0+ (1,0) [0|1] "" Vector__XXX
 SG_ PopupMessageOutput_4Level : 51|1@0+ (1,0) [0|1] "" Vector__XXX
 SG_ PopupMessageOutput_5Level : 52|1@0+ (1,0) [0|1] "" Vector__XXX
 SG_ PopupMessageOutput_6Level : 53|1@0+ (1,0) [0|1] "" Vector__XXX
 SG_ PopupMessageOutput_7Level : 54|1@0+ (1,0) [0|1] "" Vector__XXX
 SG_ PopupMessageOutput_8Level : 55|1@0+ (1,0) [0|1] "" Vector__XXX

BO_ 1348 Navi_HU: 8 XXX
 SG_ SpeedLim_Nav_Clu : 7|8@0+ (1,0) [0|255] "" XXX
 SG_ SpeedLim_Nav_General : 29|1@0+ (1,0) [0|1] "" XXX
 SG_ SpeedLim_Nav_Cam : 30|1@0+ (1,0) [0|1] "" XXX

BO_ 16 ACU13: 8 ACU
 SG_ CF_Acu_CshAct : 0|1@1+ (1.0,0.0) [0.0|1.0] ""  CUBIS,IBOX,ODS

BO_ 257 RADAR_POINTS_0x101: 64 RADAR
 SG_ MESSAGE_ID : 0|5@1+ (1,0) [0|31] "" XXX
 SG_ LAYOUT_ID : 5|2@1+ (1,0) [0|3] "" XXX
 SG_ POINT_1_DISTANCE : 7|14@1+ (0.015625,0) [0|255.984375] "" XXX
 SG_ POINT_1_SIGNAL_2 : 21|2@1+ (1,0) [0|3] "" XXX
 SG_ POINT_1_SIGNAL_3 : 23|8@1+ (0.001953125,-0.248046875) [-0.248046875|0.25] "" XXX
 SG_ POINT_1_REL_VELOCITY : 31|13@1+ (0.03125,-66) [-66|189.96875] "" XXX
 SG_ POINT_1_SIGNAL_5 : 44|2@1+ (1,0) [0|3] "" XXX
 SG_ POINT_1_SIGNAL_6 : 46|2@1+ (1,0) [0|3] "" XXX
 SG_ POINT_1_AZIMUTH : 48|12@1+ (0.001953125,-3.998046875) [-3.998046875|4.0] "" XXX
 SG_ POINT_1_SIGNAL_8 : 60|2@1+ (1,0) [0|3] "" XXX
 SG_ POINT_1_SIGNAL_9 : 62|1@1+ (1,0) [0|1] "" XXX
 SG_ POINT_1_SIGNAL_10 : 63|7@1+ (1,0) [0|127] "" XXX
 SG_ POINT_1_SIGNAL_11 : 70|1@1+ (1,0) [0|1] "" XXX
 SG_ POINT_1_SIGNAL_12 : 71|6@1+ (1,0) [0|63] "" XXX
 SG_ POINT_1_SIGNAL_13 : 77|2@1+ (1,0) [0|3] "" XXX
 SG_ POINT_1_SIGNAL_14 : 79|8@1+ (0.001953125,-0.248046875) [-0.248046875|0.25] "" XXX
 SG_ POINT_1_SIGNAL_15 : 87|1@1+ (1,0) [0|1] "" XXX
 SG_ POINT_1_SIGNAL_16 : 88|2@1+ (1,0) [0|3] "" XXX
 SG_ POINT_1_SIGNAL_17 : 90|3@1+ (1,0) [0|7] "" XXX
 SG_ POINT_1_SIGNAL_18 : 93|6@1+ (1,0) [0|63] "" XXX
 SG_ POINT_1_SIGNAL_19 : 99|8@1+ (1,0) [0|255] "" XXX
 SG_ POINT_1_SIGNAL_20 : 107|1@1+ (1,0) [0|1] "" XXX
 SG_ POINT_2_DISTANCE : 108|14@1+ (0.015625,0) [0|255.984375] "" XXX
 SG_ POINT_2_SIGNAL_2 : 122|2@1+ (1,0) [0|3] "" XXX
 SG_ POINT_2_SIGNAL_3 : 124|8@1+ (0.001953125,-0.248046875) [-0.248046875|0.25] "" XXX
 SG_ POINT_2_REL_VELOCITY : 132|13@1+ (0.03125,-66) [-66|189.96875] "" XXX
 SG_ POINT_2_SIGNAL_5 : 145|2@1+ (1,0) [0|3] "" XXX
 SG_ POINT_2_SIGNAL_6 : 147|2@1+ (1,0) [0|3] "" XXX
 SG_ POINT_2_AZIMUTH : 149|12@1+ (0.001953125,-3.998046875) [-3.998046875|4.0] "" XXX
 SG_ POINT_2_SIGNAL_8 : 161|2@1+ (1,0) [0|3] "" XXX
 SG_ POINT_2_SIGNAL_9 : 163|1@1+ (1,0) [0|1] "" XXX
 SG_ POINT_2_SIGNAL_10 : 164|7@1+ (1,0) [0|127] "" XXX
 SG_ POINT_2_SIGNAL_11 : 171|1@1+ (1,0) [0|1] "" XXX
 SG_ POINT_2_SIGNAL_12 : 172|6@1+ (1,0) [0|63] "" XXX
 SG_ POINT_2_SIGNAL_13 : 178|2@1+ (1,0) [0|3] "" XXX
 SG_ POINT_2_SIGNAL_14 : 180|8@1+ (0.001953125,-0.248046875) [-0.248046875|0.25] "" XXX
 SG_ POINT_2_SIGNAL_15 : 188|1@1+ (1,0) [0|1] "" XXX
 SG_ POINT_2_SIGNAL_16 : 189|2@1+ (1,0) [0|3] "" XXX
 SG_ POINT_2_SIGNAL_17 : 191|3@1+ (1,0) [0|7] "" XXX
 SG_ POINT_2_SIGNAL_18 : 194|6@1+ (1,0) [0|63] "" XXX
 SG_ POINT_2_SIGNAL_19 : 200|8@1+ (1,0) [0|255] "" XXX
 SG_ POINT_2_SIGNAL_20 : 208|1@1+ (1,0) [0|1] "" XXX
 SG_ POINT_3_DISTANCE : 209|14@1+ (0.015625,0) [0|255.984375] "" XXX
 SG_ POINT_3_SIGNAL_2 : 223|2@1+ (1,0) [0|3] "" XXX
 SG_ POINT_3_SIGNAL_3 : 225|8@1+ (0.001953125,-0.248046875) [-0.248046875|0.25] "" XXX
 SG_ POINT_3_REL_VELOCITY : 233|13@1+ (0.03125,-66) [-66|189.96875] "" XXX
 SG_ POINT_3_SIGNAL_5 : 246|2@1+ (1,0) [0|3] "" XXX
 SG_ POINT_3_SIGNAL_6 : 248|2@1+ (1,0) [0|3] "" XXX
 SG_ POINT_3_AZIMUTH : 250|12@1+ (0.001953125,-3.998046875) [-3.998046875|4.0] "" XXX
 SG_ POINT_3_SIGNAL_8 : 262|2@1+ (1,0) [0|3] "" XXX
 SG_ POINT_3_SIGNAL_9 : 264|1@1+ (1,0) [0|1] "" XXX
 SG_ POINT_3_SIGNAL_10 : 265|7@1+ (1,0) [0|127] "" XXX
 SG_ POINT_3_SIGNAL_11 : 272|1@1+ (1,0) [0|1] "" XXX
 SG_ POINT_3_SIGNAL_12 : 273|6@1+ (1,0) [0|63] "" XXX
 SG_ POINT_3_SIGNAL_13 : 279|2@1+ (1,0) [0|3] "" XXX
 SG_ POINT_3_SIGNAL_14 : 281|8@1+ (0.001953125,-0.248046875) [-0.248046875|0.25] "" XXX
 SG_ POINT_3_SIGNAL_15 : 289|1@1+ (1,0) [0|1] "" XXX
 SG_ POINT_3_SIGNAL_16 : 290|2@1+ (1,0) [0|3] "" XXX
 SG_ POINT_3_SIGNAL_17 : 292|3@1+ (1,0) [0|7] "" XXX
 SG_ POINT_3_SIGNAL_18 : 295|6@1+ (1,0) [0|63] "" XXX
 SG_ POINT_3_SIGNAL_19 : 301|8@1+ (1,0) [0|255] "" XXX
 SG_ POINT_3_SIGNAL_20 : 309|1@1+ (1,0) [0|1] "" XXX
 SG_ POINT_4_DISTANCE : 310|14@1+ (0.015625,0) [0|255.984375] "" XXX
 SG_ POINT_4_SIGNAL_2 : 324|2@1+ (1,0) [0|3] "" XXX
 SG_ POINT_4_SIGNAL_3 : 326|8@1+ (0.001953125,-0.248046875) [-0.248046875|0.25] "" XXX
 SG_ POINT_4_REL_VELOCITY : 334|13@1+ (0.03125,-66) [-66|189.96875] "" XXX
 SG_ POINT_4_SIGNAL_5 : 347|2@1+ (1,0) [0|3] "" XXX
 SG_ POINT_4_SIGNAL_6 : 349|2@1+ (1,0) [0|3] "" XXX
 SG_ POINT_4_AZIMUTH : 351|12@1+ (0.001953125,-3.998046875) [-3.998046875|4.0] "" XXX
 SG_ POINT_4_SIGNAL_8 : 363|2@1+ (1,0) [0|3] "" XXX
 SG_ POINT_4_SIGNAL_9 : 365|1@1+ (1,0) [0|1] "" XXX
 SG_ POINT_4_SIGNAL_10 : 366|7@1+ (1,0) [0|127] "" XXX
 SG_ POINT_4_SIGNAL_11 : 373|1@1+ (1,0) [0|1] "" XXX
 SG_ POINT_4_SIGNAL_12 : 374|6@1+ (1,0) [0|63] "" XXX
 SG_ POINT_4_SIGNAL_13 : 380|2@1+ (1,0) [0|3] "" XXX
 SG_ POINT_4_SIGNAL_14 : 382|8@1+ (0.001953125,-0.248046875) [-0.248046875|0.25] "" XXX
 SG_ POINT_4_SIGNAL_15 : 390|1@1+ (1,0) [0|1] "" XXX
 SG_ POINT_4_SIGNAL_16 : 391|2@1+ (1,0) [0|3] "" XXX
 SG_ POINT_4_SIGNAL_17 : 393|3@1+ (1,0) [0|7] "" XXX
 SG_ POINT_4_SIGNAL_18 : 396|6@1+ (1,0) [0|63] "" XXX
 SG_ POINT_4_SIGNAL_19 : 402|8@1+ (1,0) [0|255] "" XXX
 SG_ POINT_4_SIGNAL_20 : 410|1@1+ (1,0) [0|1] "" XXX
 SG_ POINT_5_DISTANCE : 411|14@1+ (0.015625,0) [0|255.984375] "" XXX
 SG_ POINT_5_SIGNAL_2 : 425|2@1+ (1,0) [0|3] "" XXX
 SG_ POINT_5_SIGNAL_3 : 427|8@1+ (0.001953125,-0.248046875) [-0.248046875|0.25] "" XXX
 SG_ POINT_5_REL_VELOCITY : 435|13@1+ (0.03125,-66) [-66|189.96875] "" XXX
 SG_ POINT_5_SIGNAL_5 : 448|2@1+ (1,0) [0|3] "" XXX
 SG_ POINT_5_SIGNAL_6 : 450|2@1+ (1,0) [0|3] "" XXX
 SG_ POINT_5_AZIMUTH : 452|12@1+ (0.001953125,-3.998046875) [-3.998046875|4.0] "" XXX
 SG_ POINT_5_SIGNAL_8 : 464|2@1+ (1,0) [0|3] "" XXX
 SG_ POINT_5_SIGNAL_9 : 466|1@1+ (1,0) [0|1] "" XXX
 SG_ POINT_5_SIGNAL_10 : 467|7@1+ (1,0) [0|127] "" XXX
 SG_ POINT_5_SIGNAL_11 : 474|1@1+ (1,0) [0|1] "" XXX
 SG_ POINT_5_SIGNAL_12 : 475|6@1+ (1,0) [0|63] "" XXX
 SG_ POINT_5_SIGNAL_13 : 481|2@1+ (1,0) [0|3] "" XXX
 SG_ POINT_5_SIGNAL_14 : 483|8@1+ (0.001953125,-0.248046875) [-0.248046875|0.25] "" XXX
 SG_ POINT_5_SIGNAL_15 : 491|1@1+ (1,0) [0|1] "" XXX
 SG_ POINT_5_SIGNAL_16 : 492|2@1+ (1,0) [0|3] "" XXX
 SG_ POINT_5_SIGNAL_17 : 494|3@1+ (1,0) [0|7] "" XXX
 SG_ POINT_5_SIGNAL_18 : 497|6@1+ (1,0) [0|63] "" XXX
 SG_ POINT_5_SIGNAL_19 : 503|8@1+ (1,0) [0|255] "" XXX
 SG_ POINT_5_SIGNAL_20 : 511|1@1+ (1,0) [0|1] "" XXX

BO_ 260 RADAR_POINTS_CHECKSUM_0x104: 3 RADAR
 SG_ CRC16 : 0|16@1+ (1,0) [0|65535] "" XXX

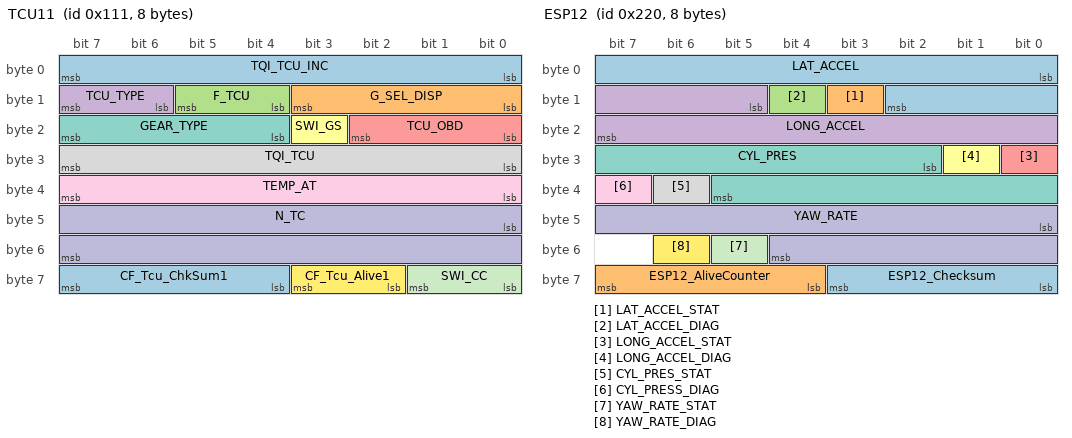
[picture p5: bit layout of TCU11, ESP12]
BO_ 273 TCU11: 8 TCU
 SG_ TQI_TCU_INC : 0|8@1+ (0.390625,0.0) [0.0|99.609375] "%"  EMS,ESC,IBOX
 SG_ G_SEL_DISP : 8|4@1+ (1.0,0.0) [0.0|15.0] ""  _4WD,AFLS,AVM,BCM,CGW,CLU,CUBIS,ECS,EMS,EPB,ESC,IAP,IBOX,LCA,LDWS_LKAS,LVR,MDPS,PGS,SCC,SMK,SNV,SPAS,TPMS
 SG_ F_TCU : 12|2@1+ (1.0,0.0) [0.0|3.0] ""  EMS,ESC,IBOX
 SG_ TCU_TYPE : 14|2@1+ (1.0,0.0) [0.0|3.0] ""  _4WD,EMS,ESC,IBOX
 SG_ TCU_OBD : 16|3@1+ (1.0,0.0) [0.0|7.0] ""  EMS,ESC,IBOX
 SG_ SWI_GS : 19|1@1+ (1.0,0.0) [0.0|1.0] ""  _4WD,EMS,EPB,ESC,IBOX,SCC
 SG_ GEAR_TYPE : 20|4@1+ (1.0,0.0) [0.0|15.0] ""  _4WD,CLU,EMS,ESC,IBOX,SCC
 SG_ TQI_TCU : 24|8@1+ (0.390625,0.0) [0.0|99.609375] "%"  EMS,ESC,IBOX
 SG_ TEMP_AT : 32|8@1+ (1.0,-40.0) [-40.0|214.0] "deg"  AAF,CLU,CUBIS,EMS,ESC,IBOX
 SG_ N_TC : 40|16@1+ (0.25,0.0) [0.0|16383.5] "rpm"  _4WD,EMS,EPB,ESC,IBOX
 SG_ SWI_CC : 56|2@1+ (1.0,0.0) [0.0|3.0] ""  _4WD,CLU,EMS,ESC,IBOX
 SG_ CF_Tcu_Alive1 : 58|2@1+ (1.0,0.0) [0.0|3.0] ""  EMS,IBOX
 SG_ CF_Tcu_ChkSum1 : 60|4@1+ (1.0,0.0) [0.0|15.0] ""  EMS,IBOX

BO_ 274 TCU12: 8 TCU
 SG_ ETL_TCU : 0|8@1+ (2.0,0.0) [0.0|508.0] "Nm"  EMS,IBOX
 SG_ CUR_GR : 8|4@1+ (1.0,0.0) [0.0|15.0] ""  _4WD,EMS,ESC,IBOX,SCC,TPMS
 SG_ CF_Tcu_Alive : 12|2@1+ (1.0,0.0) [0.0|3.0] ""  EMS,ESC,IBOX,SCC
 SG_ CF_Tcu_ChkSum : 14|2@1+ (1.0,0.0) [0.0|3.0] ""  EMS,ESC,IBOX,SCC
 SG_ VS_TCU : 16|8@1+ (1.0,0.0) [0.0|254.0] "km/h"  BCM,CLU,DATC,EMS,IBOX,LCA,LVR,PGS,SMK,SNV
 SG_ FUEL_CUT_TCU : 28|1@1+ (1.0,0.0) [0.0|1.0] ""  EMS,IBOX
 SG_ INH_FUEL_CUT : 29|1@1+ (1.0,0.0) [0.0|1.0] ""  EMS,IBOX
 SG_ IDLE_UP_TCU : 30|1@1+ (1.0,0.0) [0.0|1.0] ""  EMS,IBOX
 SG_ N_INC_TCU : 31|1@1+ (1.0,0.0) [0.0|1.0] ""  EMS,IBOX
 SG_ SPK_RTD_TCU : 32|8@1+ (0.375,-23.625) [-15.0|15.0] ""  EMS,IBOX
 SG_ N_TC_RAW : 40|16@1+ (0.25,0.0) [0.0|16383.5] "rpm"  EMS,IBOX
 SG_ VS_TCU_DECIMAL : 56|8@1+ (0.0078125,0.0) [0.0|0.9921875] "km/h"  CLU,EMS,IBOX,LCA

BO_ 275 TCU13: 8 TCU
 SG_ N_TGT_LUP : 0|8@1+ (10.0,500.0) [500.0|3040.0] "rpm"  EMS,IBOX
 SG_ SLOPE_TCU : 8|6@1+ (0.5,-16.0) [-16.0|15.5] "%"  CLU,CUBIS,EMS,IBOX
 SG_ CF_Tcu_InhCda : 14|1@1+ (1.0,0.0) [0.0|1.0] ""  EMS,IBOX
 SG_ CF_Tcu_IsgInhib : 15|1@1+ (1.0,0.0) [0.0|1.0] ""  EMS,IBOX
 SG_ CF_Tcu_BkeOnReq : 16|2@1+ (1.0,0.0) [0.0|3.0] ""  EMS,IBOX
 SG_ CF_Tcu_NCStat : 18|2@1+ (1.0,0.0) [0.0|3.0] ""  EMS,IBOX
 SG_ CF_Tcu_TarGr : 20|4@1+ (1.0,0.0) [0.0|15.0] ""  _4WD,CLU,DATC,EMS,EPB,ESC,IBOX,SCC
 SG_ CF_Tcu_ShfPatt : 24|4@1+ (1.0,0.0) [0.0|15.0] ""  CLU,CUBIS,EMS,IBOX
 SG_ CF_Tcu_InhVis : 28|1@1+ (1.0,0.0) [0.0|1.0] ""  EMS,IBOX
 SG_ CF_Tcu_PRelReq : 29|1@1+ (1.0,0.0) [0.0|1.0] ""  IBOX,LVR
 SG_ CF_Tcu_ITPhase : 30|1@1+ (1.0,0.0) [0.0|1.0] ""  EMS,IBOX
 SG_ CF_Tcu_ActEcoRdy : 31|1@1+ (1.0,0.0) [0.0|1.0] ""  EMS,IBOX
 SG_ CF_Tcu_TqGrdLim : 32|8@1+ (10.0,0.0) [0.0|2540.0] "Nm/s"  EMS,IBOX
 SG_ CR_Tcu_IsgTgtRPM : 40|8@1+ (20.0,0.0) [0.0|3500.0] "rpm"  EMS,IBOX
 SG_ CF_Tcu_SptRdy : 48|1@1+ (1.0,0.0) [0.0|1.0] ""  CLU,IBOX
 SG_ CF_Tcu_SbwPInfo : 56|1@1+ (1.0,0.0) [0.0|1.0] ""  EMS,IBOX
 SG_ CF_Tcu_Alive3 : 58|2@1+ (1.0,0.0) [0.0|3.0] ""  EMS,IBOX
 SG_ CF_Tcu_ChkSum3 : 60|4@1+ (1.0,0.0) [0.0|15.0] ""  EMS,IBOX

BO_ 320 YRS12: 8 ACU
 SG_ CF_Yrs_LongAcStat : 16|4@1+ (1,0) [0|15] "" iBAU
 SG_ CF_IMU_ResetStat : 20|4@1+ (1,0) [0|15] "" iBAU
 SG_ YRS_Temp : 24|8@1+ (1,-68) [-68|187] "" iBAU
 SG_ YRS_TempStat : 32|4@1+ (1,0) [0|15] "" iBAU
 SG_ CF_Yrs_Type : 36|4@1+ (1,0) [0|15] "" iBAU
 SG_ CR_Yrs_MsgCnt2 : 48|4@1+ (1,0) [0|15] "" iBAU
 SG_ CR_Yrs_Crc2 : 56|8@1+ (1,0) [0|255] "" iBAU
 SG_ CR_Yrs_LongAc : 0|16@1+ (0.000127465,-4.17677312) [-4.17677312|4.17651819] "g" CGW,iBAU

BO_ 516 RADAR_POINTS_CHECKSUM_0x204: 3 RADAR
 SG_ CRC16 : 0|16@1+ (1,0) [0|65535] "" XXX

BO_ 544 ESP12: 8 ESC
 SG_ LAT_ACCEL : 0|11@1+ (0.01,-10.23) [-10.23|10.24] "m/s^2"  _4WD,ECS,IBOX,LCA,LDWS_LKAS,MDPS,PSB,SCC,TCU
 SG_ LAT_ACCEL_STAT : 11|1@1+ (1.0,0.0) [0.0|1.0] ""  _4WD,IBOX,LDWS_LKAS,MDPS,PSB,SCC,TCU
 SG_ LAT_ACCEL_DIAG : 12|1@1+ (1.0,0.0) [0.0|1.0] ""  _4WD,IBOX,LDWS_LKAS,MDPS,PSB,SCC,TCU
 SG_ LONG_ACCEL : 13|11@1+ (0.01,-10.23) [-10.23|10.24] "m/s^2"  _4WD,ECS,EMS,EPB,IBOX,LCA,LDWS_LKAS,PSB,SCC,SPAS,TCU
 SG_ LONG_ACCEL_STAT : 24|1@1+ (1.0,0.0) [0.0|1.0] ""  _4WD,EMS,EPB,IBOX,LDWS_LKAS,PSB,SCC,SPAS,TCU
 SG_ LONG_ACCEL_DIAG : 25|1@1+ (1.0,0.0) [0.0|1.0] ""  _4WD,EMS,EPB,IBOX,LDWS_LKAS,PSB,SCC,SPAS,TCU
 SG_ CYL_PRES : 26|12@1+ (0.1,0.0) [0.0|409.5] "Bar"  _4WD,ECS,EMS,EPB,IBOX,LDWS_LKAS,PSB,SCC,TCU
 SG_ CYL_PRES_STAT : 38|1@1+ (1.0,0.0) [0.0|1.0] ""  _4WD,ECS,EMS,EPB,IBOX,LDWS_LKAS,PSB,SCC,TCU
 SG_ CYL_PRESS_DIAG : 39|1@1+ (1.0,0.0) [0.0|1.0] ""  _4WD,ECS,EMS,EPB,IBOX,PSB,SCC,TCU
 SG_ YAW_RATE : 40|13@1+ (0.01,-40.95) [-40.95|40.96] ""  _4WD,AFLS,IBOX,LCA,LDWS_LKAS,MDPS,PSB,SCC,SPAS,TCU
 SG_ YAW_RATE_STAT : 53|1@1+ (1.0,0.0) [0.0|1.0] ""  _4WD,AFLS,IBOX,LCA,LDWS_LKAS,MDPS,PSB,SCC,SPAS,TCU
 SG_ YAW_RATE_DIAG : 54|1@1+ (1.0,0.0) [0.0|1.0] ""  _4WD,AFLS,IBOX,LCA,LDWS_LKAS,MDPS,PSB,SCC,SPAS,TCU
 SG_ ESP12_Checksum : 56|4@1+ (1.0,0.0) [0.0|15.0] ""  _4WD,EMS,LPI,TCU,TMU
 SG_ ESP12_AliveCounter : 60|4@1+ (1.0,0.0) [0.0|15.0] ""  _4WD,EMS,LPI,TCU,TMU

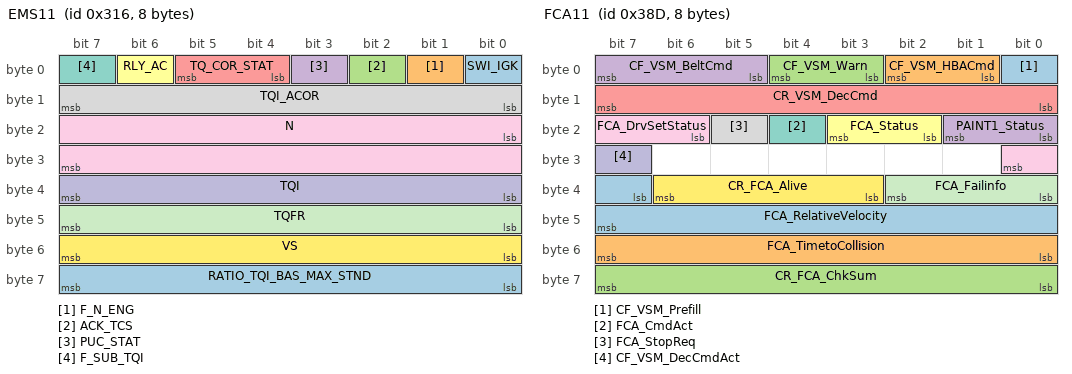
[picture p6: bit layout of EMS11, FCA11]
BO_ 790 EMS11: 8 EMS
 SG_ SWI_IGK : 0|1@1+ (1.0,0.0) [0.0|1.0] ""  _4WD,ABS,ACU,AHLS,CUBIS,DI_BOX,ECS,EPB,ESC,IBOX,LDWS_LKAS,MDPS,REA,SAS,SCC,TCU
 SG_ F_N_ENG : 1|1@1+ (1.0,0.0) [0.0|1.0] ""  _4WD,ACU,AFLS,CLU,CUBIS,DATC,ECS,EPB,ESC,IBOX,MDPS,SCC,TCU
 SG_ ACK_TCS : 2|1@1+ (1.0,0.0) [0.0|1.0] ""  ESC,IBOX
 SG_ PUC_STAT : 3|1@1+ (1.0,0.0) [0.0|1.0] ""  _4WD,CLU,DATC,IBOX,TCU
 SG_ TQ_COR_STAT : 4|2@1+ (1.0,0.0) [0.0|3.0] ""  _4WD,ESC,IBOX,TCU
 SG_ RLY_AC : 6|1@1+ (1.0,0.0) [0.0|1.0] ""  DATC,IBOX,TCU
 SG_ F_SUB_TQI : 7|1@1+ (1.0,0.0) [0.0|1.0] ""  _4WD,ECS,EPB,ESC,IBOX,TCU
 SG_ TQI_ACOR : 8|8@1+ (0.390625,0.0) [0.0|99.6094] "%"  _4WD,EPB,ESC,IBOX,TCU
 SG_ N : 16|16@1+ (0.25,0.0) [0.0|16383.75] "rpm"  _4WD,ACU,AFLS,CLU,CUBIS,DATC,ECS,EPB,ESC,FPCM,IBOX,MDPS,SCC,TCU
 SG_ TQI : 32|8@1+ (0.390625,0.0) [0.0|99.6094] "%"  _4WD,ECS,EPB,ESC,IBOX,TCU
 SG_ TQFR : 40|8@1+ (0.390625,0.0) [0.0|99.6094] "%"  _4WD,EPB,ESC,IBOX,TCU
 SG_ VS : 48|8@1+ (1.0,0.0) [0.0|254.0] "km/h"  _4WD,AAF,ACU,AHLS,BCM,CLU,DATC,ECS,EPB,IBOX,LCA,LDWS_LKAS,LVR,MDPS,ODS,SCC,SMK,SPAS,TCU,TPMS
 SG_ RATIO_TQI_BAS_MAX_STND : 56|8@1+ (0.0078,0.0) [0.0|2.0] ""  _4WD,IBOX,TCU

BO_ 854 M_356: 8 XXX
 SG_ PAINT1 : 32|1@0+ (1,0) [0|1] "" XXX
 SG_ PAINT2 : 34|2@0+ (1,0) [0|1] "" XXX
 SG_ PAINT3 : 36|2@0+ (1,0) [0|3] "" XXX
 SG_ PAINT4 : 38|1@0+ (1,0) [0|1] "" XXX

BO_ 865 ADAS_PRK_11: 8 ADAS_PRK
 SG_ CF_PCA_BrkReq : 24|1@1+ (1,0) [0|0] "" Vector__XXX
 SG_ CF_PCA_DclTrgtVal : 28|4@1+ (0.04,0) [0|0] "g" Vector__XXX
 SG_ PCA_ALIVE_CNT : 40|4@1+ (1,0) [0|0] "" Vector__XXX
 SG_ PCA_CHECK_SUM : 48|8@1+ (1,0) [0|0] "" Vector__XXX

BO_ 870 EMS_366: 8 EMS
 SG_ TQI_1 : 0|8@1+ (0.390625,0) [0|99.6094] "%" MDPS
 SG_ N : 8|16@1+ (0.25,0.0) [0.0|16383.75] "rpm" MDPS
 SG_ TQI_2 : 24|8@1+ (0.390625,0) [0|99.6094] "%" MDPS
 SG_ VS : 40|8@1+ (1,0) [0|255] "km/h" MDPS
 SG_ SWI_IGK : 48|1@0+ (1,0) [0|1] "" XXX

BO_ 881 E_EMS11: 8 XXX
 SG_ Brake_Pedal_Pos : 0|8@1+ (1,0) [0|127] "" XXX
 SG_ IG_Reactive_Stat : 8|3@1+ (1,0) [0|3] "" XXX
 SG_ Gear_Change : 12|1@0+ (1,0) [0|31] "" XXX
 SG_ Cruise_Limit_Status : 13|1@1+ (1,0) [0|1] "" XXX
 SG_ Cruise_Limit_Target : 23|8@1+ (1,0) [0|15] "" XXX
 SG_ Accel_Pedal_Pos : 31|8@1+ (1,0) [0|254] "" XXX
 SG_ CR_Vcu_AccPedDep_Pos : 56|8@1+ (1,0) [0|254] "" XXX

BO_ 882 ELECT_GEAR: 8 XXX
 SG_ Elect_Gear_Shifter : 16|4@1+ (1,0) [0|7] ""  CLU

BO_ 905 SCC14: 8 SCC
 SG_ ComfortBandUpper : 0|6@1+ (0.02,0) [0|1.26] "m/s^2" ESC
 SG_ ComfortBandLower : 6|6@1+ (0.02,0) [0|1.26] "m/s^2" ESC
 SG_ JerkUpperLimit : 12|7@1+ (0.1,0) [0|12.7] "m/s^3" ESC
 SG_ JerkLowerLimit : 19|7@1+ (0.1,0) [0|12.7] "m/s^3" ESC
 SG_ ACCMode : 32|3@1+ (1,0) [0|7] "" CLU,HUD,LDWS_LKAS,ESC
 SG_ ObjDistStat : 42|2@1+ (1,0) [0|3] "" XXX
 SG_ ObjGap : 56|8@1+ (1,0) [0|255] "" CLU,HUD,ESC

BO_ 908 RSPA11: 8 RSPA
 SG_ CF_RSPA_State : 0|4@1+ (1,0) [0|15] "" XXX
 SG_ CF_RSPA_Act : 4|2@1+ (1,0) [0|3] "" XXX
 SG_ CF_RSPA_DecCmd : 6|2@1+ (1,0) [0|3] "" XXX
 SG_ CF_RSPA_Trgt_Spd : 8|10@1+ (0.01,0) [0|10.23] "km/h" XXX
 SG_ CF_RSPA_StopReq : 18|1@1+ (1,0) [0|2] "" XXX
 SG_ CR_RSPA_EPB_Req : 22|2@1+ (1,0) [0|3] "" XXX
 SG_ CF_RSPA_ACC_ACT : 50|1@1+ (1,0) [0|2] "" XXX
 SG_ CF_RSPA_AliveCounter : 52|4@1+ (1,0) [0|15] "" XXX
 SG_ CF_RSPA_CRC : 56|8@1+ (1,0) [0|255] "" XXX

BO_ 909 FCA11: 8 FCA
 SG_ CF_VSM_Prefill : 0|1@1+ (1,0) [0|1] "" ESC
 SG_ CF_VSM_HBACmd : 1|2@1+ (1,0) [0|3] "" ESC
 SG_ CF_VSM_Warn : 3|2@1+ (1,0) [0|3] "" ACU,CLU,ESC
 SG_ CF_VSM_BeltCmd : 5|3@1+ (1,0) [0|7] "" ESC
 SG_ CR_VSM_DecCmd : 8|8@1+ (0.01,0) [0|2.55] "g" ESC
 SG_ FCA_Status : 18|2@1+ (1,0) [0|3] "" ACU,CLU,ESC
 SG_ FCA_CmdAct : 20|1@1+ (1,0) [0|1] "" ESC
 SG_ FCA_StopReq : 21|1@1+ (1,0) [0|1] "" CLU,ESC
 SG_ FCA_DrvSetStatus : 22|3@1+ (1,0) [0|7] "" CLU,ESC
 SG_ CF_VSM_DecCmdAct : 31|1@1+ (1,0) [0|1] "" ESC
 SG_ FCA_Failinfo : 32|3@1+ (1,0) [0|7] "" ACU,CLU,ESC
 SG_ CR_FCA_Alive : 35|4@1+ (1,0) [0|15] "" ESC
 SG_ FCA_RelativeVelocity : 39|9@1+ (0.1,-25.5) [-25.5|25.5] "m/s" iBAU
 SG_ FCA_TimetoCollision : 48|8@1+ (10,0) [0|2540] "ms" iBAU
 SG_ CR_FCA_ChkSum : 56|8@1+ (1,0) [0|255] "" ESC
 SG_ PAINT1_Status : 16|2@1+ (1,0) [0|1] "" XXX

BO_ 910 WHL_SPD12_FS: 5 iBAU
 SG_ CRC : 0|8@1+ (1,0) [0|0] "" Vector__XXX
 SG_ WHL_SPD12_AliveCounter : 8|4@1+ (1,0) [0|15] "" Vector__XXX
 SG_ WHL_SPD_FL : 12|14@1+ (0.03125,0) [0|511.96875] "km/h" Vector__XXX
 SG_ WHL_SPD_FR : 26|14@1+ (0.03125,0) [0|511.96875] "km/h" Vector__XXX

BO_ 911 WHL_SPD13_FS: 5 iBAU
 SG_ CRC : 0|8@1+ (1,0) [0|0] "" Vector__XXX
 SG_ WHL_SPD13_AliveCounter : 8|4@1+ (1,0) [0|15] "" Vector__XXX
 SG_ WHL_SPD_RL : 12|14@1+ (0.03125,0) [0|511.96875] "km/h" Vector__XXX
 SG_ WHL_SPD_RR : 26|14@1+ (0.03125,0) [0|511.96875] "km/h" Vector__XXX

BO_ 913 BCM_PO_11: 8 Vector__XXX
 SG_ BCM_Door_Dri_Status : 5|1@0+ (1,0) [0|1] "" PT_ESC_ABS
 SG_ BCM_Shift_R_MT_SW_Status : 39|2@0+ (1,0) [0|3] "" PT_ESC_ABS
 SG_ LFA_Pressed : 4|1@0+ (1,0) [0|1] "" XXX

BO_ 914 S_MDPS11: 8 XXX
 SG_ CF_Mdps_Stat : 0|4@1+ (1,0) [0|15] "" XXX
 SG_ CR_Mdps_DrvTq : 8|12@1+ (1,0) [0|15] "" XXX
 SG_ CR_Mdps_StrAng : 24|16@1- (1,0) [0|65535] "" XXX
 SG_ CF_Mdps_AliveCnt : 47|8@0+ (1,0) [0|255] "" XXX
 SG_ CF_Mdps_Chksum : 63|8@0+ (1,0) [0|255] "" XXX

BO_ 1024 CLU_CFG11: 2 CLU
 SG_ Vehicle_Type : 0|16@1+ (1.0,0.0) [0.0|65536.0] ""  _4WD

BO_ 1040 CGW_USM1: 8 BCM
 SG_ CF_Gway_ATTurnRValue : 0|2@1+ (1.0,0.0) [0.0|3.0] ""  CLU
 SG_ CF_Gway_PTGMRValue : 2|2@1+ (1.0,0.0) [0.0|3.0] ""  CLU
 SG_ CF_Gway_EscortHLRValue : 4|2@1+ (1.0,0.0) [0.0|3.0] ""  CLU
 SG_ CF_Gway_TTUnlockRValue : 6|2@1+ (1.0,0.0) [0.0|3.0] ""  CLU
 SG_ CF_Gway_ADrLRValue : 8|3@1+ (1.0,0.0) [0.0|7.0] ""  CLU
 SG_ CF_Gway_ADrURValue : 11|3@1+ (1.0,0.0) [0.0|7.0] ""  CLU
 SG_ CF_Gway_SCMRValue : 14|2@1+ (1.0,0.0) [0.0|3.0] ""  CLU
 SG_ CF_Gway_WlightRValue : 16|2@1+ (1.0,0.0) [0.0|3.0] ""  CLU
 SG_ CF_Gway_PSMRValue : 18|3@1+ (1.0,0.0) [0.0|7.0] ""  CLU
 SG_ CF_Gway_OTTurnRValue : 21|3@1+ (1.0,0.0) [0.0|7.0] ""  CLU
 SG_ CF_Gway_DrLockSoundRValue : 24|3@1+ (1.0,0.0) [0.0|7.0] ""  CLU
 SG_ CF_Gway_HAnBRValue : 27|3@1+ (1.0,0.0) [0.0|7.0] ""  CLU
 SG_ CF_Gway_MoodLpRValue : 30|2@1+ (1.0,0.0) [0.0|3.0] ""  CLU
 SG_ CF_Gway_HfreeTrunkRValue : 32|3@1+ (1.0,0.0) [0.0|7.0] ""  CLU
 SG_ CF_Gway_AutoLightRValue : 35|3@1+ (1.0,0.0) [0.0|7.0] ""  CLU
 SG_ CF_Gway_RearWiperRValue : 38|2@1+ (1.0,0.0) [0.0|3.0] ""  CLU
 SG_ CF_Gway_PasSpkrLvRValue : 40|3@1+ (1.0,0.0) [0.0|7.0] ""  CLU

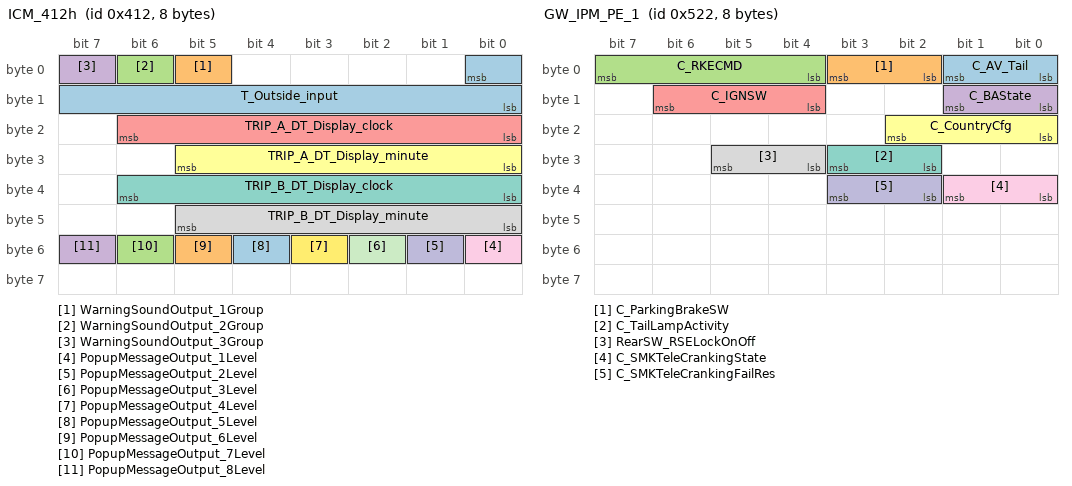
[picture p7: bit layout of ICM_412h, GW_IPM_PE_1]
BO_ 1042 ICM_412h: 8 ICM
 SG_ T_Outside_input : 0|9@0+ (0.01,0) [0|5] "V" Vector__XXX
 SG_ WarningSoundOutput_1Group : 5|1@0+ (1,0) [0|1] "" Vector__XXX
 SG_ WarningSoundOutput_2Group : 6|1@0+ (1,0) [0|1] "" Vector__XXX
 SG_ WarningSoundOutput_3Group : 7|1@0+ (1,0) [0|1] "" Vector__XXX
 SG_ TRIP_A_DT_Display_clock : 22|7@0+ (1,0) [0|99] "clock" Vector__XXX
 SG_ TRIP_A_DT_Display_minute : 29|6@0+ (1,0) [0|59] "minute" Vector__XXX
 SG_ TRIP_B_DT_Display_clock : 38|7@0+ (1,0) [0|99] "clock" Vector__XXX
 SG_ TRIP_B_DT_Display_minute : 45|6@0+ (1,0) [0|59] "minute" Vector__XXX
 SG_ PopupMessageOutput_1Level : 48|1@0+ (1,0) [0|1] "" Vector__XXX
 SG_ PopupMessageOutput_2Level : 49|1@0+ (1,0) [0|1] "" Vector__XXX
 SG_ PopupMessageOutput_3Level : 50|1@0+ (1,0) [0|1] "" Vector__XXX
 SG_ PopupMessageOutput_4Level : 51|1@0+ (1,0) [0|1] "" Vector__XXX
 SG_ PopupMessageOutput_5Level : 52|1@0+ (1,0) [0|1] "" Vector__XXX
 SG_ PopupMessageOutput_6Level : 53|1@0+ (1,0) [0|1] "" Vector__XXX
 SG_ PopupMessageOutput_7Level : 54|1@0+ (1,0) [0|1] "" Vector__XXX
 SG_ PopupMessageOutput_8Level : 55|1@0+ (1,0) [0|1] "" Vector__XXX

BO_ 1056 SCC11: 8 SCC
 SG_ MainMode_ACC : 0|1@1+ (1,0) [0|1] "" CLU,EMS,ESC
 SG_ SCCInfoDisplay : 1|3@1+ (1,0) [0|7] "" CLU,ESC
 SG_ AliveCounterACC : 4|4@1+ (1,0) [0|15] "" CLU,EMS,ESC,TCU
 SG_ VSetDis : 8|8@1+ (1,0) [0|255] "km/h or MPH" CLU,ESC,TCU
 SG_ ObjValid : 16|1@1+ (1,0) [0|1] "" CLU,ESC,TCU
 SG_ DriverAlertDisplay : 17|2@1+ (1,0) [0|3] "" CLU,ESC
 SG_ TauGapSet : 19|3@1+ (1,0) [0|7] "" CLU,ESC,TCU
 SG_ Navi_SCC_Curve_Status : 56|2@1+ (1,0) [0|3] "" CLU
 SG_ Navi_SCC_Curve_Act : 58|2@1+ (1,0) [0|3] "" CLU
 SG_ Navi_SCC_Camera_Act : 60|2@1+ (1,0) [0|3] "" CLU
 SG_ Navi_SCC_Camera_Status : 62|2@1+ (1,0) [0|3] "" CLU
 SG_ ACC_ObjStatus : 22|2@1+ (1,0) [0|3] "" ABS,ESC
 SG_ ACC_ObjLatPos : 24|9@1+ (0.1,-20) [-20|31.1] "m" ABS,ESC
 SG_ ACC_ObjRelSpd : 44|12@1+ (0.1,-170) [-170|239.5] "m/s" ABS,ESC
 SG_ ACC_ObjDist : 33|11@1+ (0.1,0) [0|204.7] "m" ABS,ESC

BO_ 1057 SCC12: 8 SCC
 SG_ CF_VSM_Prefill : 0|1@1+ (1,0) [0|1] "" ESC
 SG_ CF_VSM_DecCmdAct : 1|1@1+ (1,0) [0|1] "" ESC
 SG_ CF_VSM_HBACmd : 2|2@1+ (1,0) [0|3] "" ESC
 SG_ CF_VSM_Warn : 4|2@1+ (1,0) [0|3] "" CLU,ESC,IAP
 SG_ CF_VSM_Stat : 6|2@1+ (1,0) [0|3] "" CLU,ESC,PSB
 SG_ CF_VSM_BeltCmd : 8|3@1+ (1,0) [0|7] "" ESC,PSB
 SG_ ACCFailInfo : 11|2@1+ (1,0) [0|3] "" CLU,CUBIS,ESC,IBOX
 SG_ ACCMode : 13|2@1+ (1,0) [0|3] "" CLU,ESC,IBOX,TCU
 SG_ StopReq : 15|1@1+ (1,0) [0|1] "" EPB,ESC
 SG_ CR_VSM_DecCmd : 16|8@1+ (0.01,0) [0|2.55] "g" ESC
 SG_ TakeOverReq : 35|1@1+ (1,0) [0|1] "" CLU,ESC,TCU
 SG_ PreFill : 36|1@1+ (1,0) [0|1] "" ESC,TCU
 SG_ CF_VSM_ConfMode : 48|2@1+ (1,0) [0|3] "" CLU,ESC
 SG_ AEB_Failinfo : 50|2@1+ (1,0) [0|3] "" CLU,ESC
 SG_ AEB_Status : 52|2@1+ (1,0) [0|3] "" CLU,ESC
 SG_ AEB_CmdAct : 54|1@1+ (1,0) [0|1] "" ESC
 SG_ AEB_StopReq : 55|1@1+ (1,0) [0|1] "" CLU,ESC
 SG_ CR_VSM_Alive : 56|4@1+ (1,0) [0|15] "" ESC,PSB
 SG_ CR_VSM_ChkSum : 60|4@1+ (1,0) [0|15] "" ESC,PSB
 SG_ aReqValue : 37|11@1+ (0.01,-10.23) [-10.23|10.24] "m/s^2" Vector__XXX
 SG_ aReqRaw : 24|11@1+ (0.01,-10.23) [-10.23|10.24] "m/s^2" Vector__XXX

BO_ 1136 P_STS: 8 CGW
 SG_ HCU1_STS : 6|2@1+ (1,0) [0|3] "" BCW,EPB,FCA,MDPS,SCC,iBAU
 SG_ HCU5_STS : 8|2@1+ (1,0) [0|3] "" EPB,FCA,MDPS,iBAU
 SG_ Counter : 58|4@1+ (1,0) [0|15] "" MDPS
 SG_ Checksum : 62|2@1+ (1,0) [0|3] "" MDPS

BO_ 1155 FCA12: 8 FCA
 SG_ FCA_USM : 0|3@1+ (1,0) [0|7] "" CGW,CLU,ESC
 SG_ FCA_DrvSetState : 3|3@1+ (1,0) [0|7] "" CGW

BO_ 1156 HDA11_MFC: 8 XXX
 SG_ Counter : 5|4@0+ (1,0) [0|15] "" XXX
 SG_ NEW_SIGNAL_1 : 1|2@0+ (1,0) [0|255] "" XXX
 SG_ NEW_SIGNAL_2 : 7|2@0+ (1,0) [0|3] "" XXX
 SG_ NEW_SIGNAL_3 : 15|8@0+ (1,0) [0|255] "" XXX
 SG_ NEW_SIGNAL_4 : 16|2@1+ (1,0) [0|3] "" XXX
 SG_ NEW_SIGNAL_5 : 18|14@1+ (1,0) [0|63] "" XXX
 SG_ NEW_SIGNAL_6 : 33|2@0+ (1,0) [0|1] "" XXX
 SG_ NEW_SIGNAL_7 : 34|14@1+ (1,0) [0|16383] "" XXX
 SG_ NEW_SIGNAL_8 : 49|2@0+ (1,0) [0|1] "" XXX
 SG_ NEW_SIGNAL_9 : 50|14@1- (1,-4095) [0|16383] "" XXX

BO_ 1157 LFAHDA_MFC: 4 XXX
 SG_ HDA_USM : 0|2@1+ (1,0) [0|3] "" XXX
 SG_ HDA_Active : 2|1@1+ (1,0) [0|1] "" XXX
 SG_ HDA_Icon_State : 3|2@1+ (1,0) [0|3] "" XXX
 SG_ HDA_Chime : 7|1@1+ (1,0) [0|1] "" XXX
 SG_ HDA_VSetReq : 8|8@1+ (1,0) [0|255] "km/h" XXX
 SG_ LFA_SysWarning : 16|3@1+ (1,0) [0|7] "" XXX
 SG_ NEW_SIGNAL_1 : 20|3@1+ (1,0) [0|7] "" XXX
 SG_ LFA_Icon_State : 24|2@1+ (1,0) [0|3] "" XXX
 SG_ LFA_USM : 27|2@1+ (1,0) [0|3] "" XXX
 SG_ HDA_SysWarning : 29|2@1+ (1,0) [0|3] "" XXX

BO_ 1162 BCA11: 8 BCW
 SG_ CF_BCA_State : 16|3@1+ (1,0) [0|7] "" CLU,iBAU
 SG_ CF_BCA_Warning : 19|2@1+ (1,0) [0|3] "" CLU,iBAU
 SG_ AliveCounter : 21|4@1+ (1,0) [0|15] "" CLU,iBAU
 SG_ RCCA_Brake_Command : 29|1@1+ (1,0) [0|1] "" iBAU
 SG_ Check_Sum : 56|8@1+ (1,0) [0|16] "" iBAU

BO_ 1173 YRS13: 8 ACU
 SG_ YRS_SeralNo : 16|48@1+ (1,0) [0|281474976710655] "" iBAU

BO_ 1186 FRT_RADAR11: 2 FCA
 SG_ CF_FCA_Equip_Front_Radar : 0|3@1+ (1,0) [0|7] "" LDWS_LKAS,LDW_LKA,ESC

BO_ 1191 MFC_4a7: 8 XXX
 SG_ PAINT1 : 0|1@0+ (1,0) [0|1] "" XXX

BO_ 1280 RADAR_TRACK_500: 8 RADAR
 SG_ UNKNOWN_1 : 7|8@0- (1,0) [-128|127] "" XXX
 SG_ AZIMUTH : 12|10@0- (0.2,0) [-102.4|102.2] "" XXX
 SG_ STATE : 15|3@0+ (1,0) [0|7] "" XXX
 SG_ LONG_DIST : 18|11@0+ (0.1,0) [0|204.7] "" XXX
 SG_ REL_ACCEL : 33|10@0- (0.02,0) [-10.24|10.22] "" XXX
 SG_ ZEROS : 37|4@0+ (1,0) [0|255] "" XXX
 SG_ COUNTER : 38|1@0+ (1,0) [0|1] "" XXX
 SG_ STATE_3 : 39|1@0+ (1,0) [0|1] "" XXX
 SG_ REL_SPEED : 53|14@0- (0.01,0) [-81.92|81.92] "" XXX
 SG_ STATE_2 : 55|2@0+ (1,0) [0|3] "" XXX

BO_ 1281 RADAR_TRACK_501: 8 RADAR
 SG_ UNKNOWN_1 : 7|8@0- (1,0) [-128|127] "" XXX
 SG_ AZIMUTH : 12|10@0- (0.2,0) [-102.4|102.2] "" XXX
 SG_ STATE : 15|3@0+ (1,0) [0|7] "" XXX
 SG_ LONG_DIST : 18|11@0+ (0.1,0) [0|204.7] "" XXX
 SG_ REL_ACCEL : 33|10@0- (0.02,0) [-10.24|10.22] "" XXX
 SG_ ZEROS : 37|4@0+ (1,0) [0|255] "" XXX
 SG_ COUNTER : 38|1@0+ (1,0) [0|1] "" XXX
 SG_ STATE_3 : 39|1@0+ (1,0) [0|1] "" XXX
 SG_ REL_SPEED : 53|14@0- (0.01,0) [-81.92|81.92] "" XXX
 SG_ STATE_2 : 55|2@0+ (1,0) [0|3] "" XXX

BO_ 1282 RADAR_TRACK_502: 8 RADAR
 SG_ UNKNOWN_1 : 7|8@0- (1,0) [-128|127] "" XXX
 SG_ AZIMUTH : 12|10@0- (0.2,0) [-102.4|102.2] "" XXX
 SG_ STATE : 15|3@0+ (1,0) [0|7] "" XXX
 SG_ LONG_DIST : 18|11@0+ (0.1,0) [0|204.7] "" XXX
 SG_ REL_ACCEL : 33|10@0- (0.02,0) [-10.24|10.22] "" XXX
 SG_ ZEROS : 37|4@0+ (1,0) [0|255] "" XXX
 SG_ COUNTER : 38|1@0+ (1,0) [0|1] "" XXX
 SG_ STATE_3 : 39|1@0+ (1,0) [0|1] "" XXX
 SG_ REL_SPEED : 53|14@0- (0.01,0) [-81.92|81.92] "" XXX
 SG_ STATE_2 : 55|2@0+ (1,0) [0|3] "" XXX

BO_ 1283 RADAR_TRACK_503: 8 RADAR
 SG_ UNKNOWN_1 : 7|8@0- (1,0) [-128|127] "" XXX
 SG_ AZIMUTH : 12|10@0- (0.2,0) [-102.4|102.2] "" XXX
 SG_ STATE : 15|3@0+ (1,0) [0|7] "" XXX
 SG_ LONG_DIST : 18|11@0+ (0.1,0) [0|204.7] "" XXX
 SG_ REL_ACCEL : 33|10@0- (0.02,0) [-10.24|10.22] "" XXX
 SG_ ZEROS : 37|4@0+ (1,0) [0|255] "" XXX
 SG_ COUNTER : 38|1@0+ (1,0) [0|1] "" XXX
 SG_ STATE_3 : 39|1@0+ (1,0) [0|1] "" XXX
 SG_ REL_SPEED : 53|14@0- (0.01,0) [-81.92|81.92] "" XXX
 SG_ STATE_2 : 55|2@0+ (1,0) [0|3] "" XXX

BO_ 1284 RADAR_TRACK_504: 8 RADAR
 SG_ UNKNOWN_1 : 7|8@0- (1,0) [-128|127] "" XXX
 SG_ AZIMUTH : 12|10@0- (0.2,0) [-102.4|102.2] "" XXX
 SG_ STATE : 15|3@0+ (1,0) [0|7] "" XXX
 SG_ LONG_DIST : 18|11@0+ (0.1,0) [0|204.7] "" XXX
 SG_ REL_ACCEL : 33|10@0- (0.02,0) [-10.24|10.22] "" XXX
 SG_ ZEROS : 37|4@0+ (1,0) [0|255] "" XXX
 SG_ COUNTER : 38|1@0+ (1,0) [0|1] "" XXX
 SG_ STATE_3 : 39|1@0+ (1,0) [0|1] "" XXX
 SG_ REL_SPEED : 53|14@0- (0.01,0) [-81.92|81.92] "" XXX
 SG_ STATE_2 : 55|2@0+ (1,0) [0|3] "" XXX

BO_ 1285 RADAR_TRACK_505: 8 RADAR
 SG_ UNKNOWN_1 : 7|8@0- (1,0) [-128|127] "" XXX
 SG_ AZIMUTH : 12|10@0- (0.2,0) [-102.4|102.2] "" XXX
 SG_ STATE : 15|3@0+ (1,0) [0|7] "" XXX
 SG_ LONG_DIST : 18|11@0+ (0.1,0) [0|204.7] "" XXX
 SG_ REL_ACCEL : 33|10@0- (0.02,0) [-10.24|10.22] "" XXX
 SG_ ZEROS : 37|4@0+ (1,0) [0|255] "" XXX
 SG_ COUNTER : 38|1@0+ (1,0) [0|1] "" XXX
 SG_ STATE_3 : 39|1@0+ (1,0) [0|1] "" XXX
 SG_ REL_SPEED : 53|14@0- (0.01,0) [-81.92|81.92] "" XXX
 SG_ STATE_2 : 55|2@0+ (1,0) [0|3] "" XXX

BO_ 1286 RADAR_TRACK_506: 8 RADAR
 SG_ UNKNOWN_1 : 7|8@0- (1,0) [-128|127] "" XXX
 SG_ AZIMUTH : 12|10@0- (0.2,0) [-102.4|102.2] "" XXX
 SG_ STATE : 15|3@0+ (1,0) [0|7] "" XXX
 SG_ LONG_DIST : 18|11@0+ (0.1,0) [0|204.7] "" XXX
 SG_ REL_ACCEL : 33|10@0- (0.02,0) [-10.24|10.22] "" XXX
 SG_ ZEROS : 37|4@0+ (1,0) [0|255] "" XXX
 SG_ COUNTER : 38|1@0+ (1,0) [0|1] "" XXX
 SG_ STATE_3 : 39|1@0+ (1,0) [0|1] "" XXX
 SG_ REL_SPEED : 53|14@0- (0.01,0) [-81.92|81.92] "" XXX
 SG_ STATE_2 : 55|2@0+ (1,0) [0|3] "" XXX

BO_ 1287 RADAR_TRACK_507: 8 RADAR
 SG_ UNKNOWN_1 : 7|8@0- (1,0) [-128|127] "" XXX
 SG_ AZIMUTH : 12|10@0- (0.2,0) [-102.4|102.2] "" XXX
 SG_ STATE : 15|3@0+ (1,0) [0|7] "" XXX
 SG_ LONG_DIST : 18|11@0+ (0.1,0) [0|204.7] "" XXX
 SG_ REL_ACCEL : 33|10@0- (0.02,0) [-10.24|10.22] "" XXX
 SG_ ZEROS : 37|4@0+ (1,0) [0|255] "" XXX
 SG_ COUNTER : 38|1@0+ (1,0) [0|1] "" XXX
 SG_ STATE_3 : 39|1@0+ (1,0) [0|1] "" XXX
 SG_ REL_SPEED : 53|14@0- (0.01,0) [-81.92|81.92] "" XXX
 SG_ STATE_2 : 55|2@0+ (1,0) [0|3] "" XXX

BO_ 1288 RADAR_TRACK_508: 8 RADAR
 SG_ UNKNOWN_1 : 7|8@0- (1,0) [-128|127] "" XXX
 SG_ AZIMUTH : 12|10@0- (0.2,0) [-102.4|102.2] "" XXX
 SG_ STATE : 15|3@0+ (1,0) [0|7] "" XXX
 SG_ LONG_DIST : 18|11@0+ (0.1,0) [0|204.7] "" XXX
 SG_ REL_ACCEL : 33|10@0- (0.02,0) [-10.24|10.22] "" XXX
 SG_ ZEROS : 37|4@0+ (1,0) [0|255] "" XXX
 SG_ COUNTER : 38|1@0+ (1,0) [0|1] "" XXX
 SG_ STATE_3 : 39|1@0+ (1,0) [0|1] "" XXX
 SG_ REL_SPEED : 53|14@0- (0.01,0) [-81.92|81.92] "" XXX
 SG_ STATE_2 : 55|2@0+ (1,0) [0|3] "" XXX

BO_ 1289 RADAR_TRACK_509: 8 RADAR
 SG_ UNKNOWN_1 : 7|8@0- (1,0) [-128|127] "" XXX
 SG_ AZIMUTH : 12|10@0- (0.2,0) [-102.4|102.2] "" XXX
 SG_ STATE : 15|3@0+ (1,0) [0|7] "" XXX
 SG_ LONG_DIST : 18|11@0+ (0.1,0) [0|204.7] "" XXX
 SG_ REL_ACCEL : 33|10@0- (0.02,0) [-10.24|10.22] "" XXX
 SG_ ZEROS : 37|4@0+ (1,0) [0|255] "" XXX
 SG_ COUNTER : 38|1@0+ (1,0) [0|1] "" XXX
 SG_ STATE_3 : 39|1@0+ (1,0) [0|1] "" XXX
 SG_ REL_SPEED : 53|14@0- (0.01,0) [-81.92|81.92] "" XXX
 SG_ STATE_2 : 55|2@0+ (1,0) [0|3] "" XXX

BO_ 1290 RADAR_TRACK_50a: 8 RADAR
 SG_ UNKNOWN_1 : 7|8@0- (1,0) [-128|127] "" XXX
 SG_ AZIMUTH : 12|10@0- (0.2,0) [-102.4|102.2] "" XXX
 SG_ STATE : 15|3@0+ (1,0) [0|7] "" XXX
 SG_ LONG_DIST : 18|11@0+ (0.1,0) [0|204.7] "" XXX
 SG_ REL_ACCEL : 33|10@0- (0.02,0) [-10.24|10.22] "" XXX
 SG_ ZEROS : 37|4@0+ (1,0) [0|255] "" XXX
 SG_ COUNTER : 38|1@0+ (1,0) [0|1] "" XXX
 SG_ STATE_3 : 39|1@0+ (1,0) [0|1] "" XXX
 SG_ REL_SPEED : 53|14@0- (0.01,0) [-81.92|81.92] "" XXX
 SG_ STATE_2 : 55|2@0+ (1,0) [0|3] "" XXX

BO_ 1291 RADAR_TRACK_50b: 8 RADAR
 SG_ UNKNOWN_1 : 7|8@0- (1,0) [-128|127] "" XXX
 SG_ AZIMUTH : 12|10@0- (0.2,0) [-102.4|102.2] "" XXX
 SG_ STATE : 15|3@0+ (1,0) [0|7] "" XXX
 SG_ LONG_DIST : 18|11@0+ (0.1,0) [0|204.7] "" XXX
 SG_ REL_ACCEL : 33|10@0- (0.02,0) [-10.24|10.22] "" XXX
 SG_ ZEROS : 37|4@0+ (1,0) [0|255] "" XXX
 SG_ COUNTER : 38|1@0+ (1,0) [0|1] "" XXX
 SG_ STATE_3 : 39|1@0+ (1,0) [0|1] "" XXX
 SG_ REL_SPEED : 53|14@0- (0.01,0) [-81.92|81.92] "" XXX
 SG_ STATE_2 : 55|2@0+ (1,0) [0|3] "" XXX

BO_ 1292 RADAR_TRACK_50c: 8 RADAR
 SG_ UNKNOWN_1 : 7|8@0- (1,0) [-128|127] "" XXX
 SG_ AZIMUTH : 12|10@0- (0.2,0) [-102.4|102.2] "" XXX
 SG_ STATE : 15|3@0+ (1,0) [0|7] "" XXX
 SG_ LONG_DIST : 18|11@0+ (0.1,0) [0|204.7] "" XXX
 SG_ REL_ACCEL : 33|10@0- (0.02,0) [-10.24|10.22] "" XXX
 SG_ ZEROS : 37|4@0+ (1,0) [0|255] "" XXX
 SG_ COUNTER : 38|1@0+ (1,0) [0|1] "" XXX
 SG_ STATE_3 : 39|1@0+ (1,0) [0|1] "" XXX
 SG_ REL_SPEED : 53|14@0- (0.01,0) [-81.92|81.92] "" XXX
 SG_ STATE_2 : 55|2@0+ (1,0) [0|3] "" XXX

BO_ 1293 RADAR_TRACK_50d: 8 RADAR
 SG_ UNKNOWN_1 : 7|8@0- (1,0) [-128|127] "" XXX
 SG_ AZIMUTH : 12|10@0- (0.2,0) [-102.4|102.2] "" XXX
 SG_ STATE : 15|3@0+ (1,0) [0|7] "" XXX
 SG_ LONG_DIST : 18|11@0+ (0.1,0) [0|204.7] "" XXX
 SG_ REL_ACCEL : 33|10@0- (0.02,0) [-10.24|10.22] "" XXX
 SG_ ZEROS : 37|4@0+ (1,0) [0|255] "" XXX
 SG_ COUNTER : 38|1@0+ (1,0) [0|1] "" XXX
 SG_ STATE_3 : 39|1@0+ (1,0) [0|1] "" XXX
 SG_ REL_SPEED : 53|14@0- (0.01,0) [-81.92|81.92] "" XXX
 SG_ STATE_2 : 55|2@0+ (1,0) [0|3] "" XXX

BO_ 1294 RADAR_TRACK_50e: 8 RADAR
 SG_ UNKNOWN_1 : 7|8@0- (1,0) [-128|127] "" XXX
 SG_ AZIMUTH : 12|10@0- (0.2,0) [-102.4|102.2] "" XXX
 SG_ STATE : 15|3@0+ (1,0) [0|7] "" XXX
 SG_ LONG_DIST : 18|11@0+ (0.1,0) [0|204.7] "" XXX
 SG_ REL_ACCEL : 33|10@0- (0.02,0) [-10.24|10.22] "" XXX
 SG_ ZEROS : 37|4@0+ (1,0) [0|255] "" XXX
 SG_ COUNTER : 38|1@0+ (1,0) [0|1] "" XXX
 SG_ STATE_3 : 39|1@0+ (1,0) [0|1] "" XXX
 SG_ REL_SPEED : 53|14@0- (0.01,0) [-81.92|81.92] "" XXX
 SG_ STATE_2 : 55|2@0+ (1,0) [0|3] "" XXX

BO_ 1295 RADAR_TRACK_50f: 8 RADAR
 SG_ UNKNOWN_1 : 7|8@0- (1,0) [-128|127] "" XXX
 SG_ AZIMUTH : 12|10@0- (0.2,0) [-102.4|102.2] "" XXX
 SG_ STATE : 15|3@0+ (1,0) [0|7] "" XXX
 SG_ LONG_DIST : 18|11@0+ (0.1,0) [0|204.7] "" XXX
 SG_ REL_ACCEL : 33|10@0- (0.02,0) [-10.24|10.22] "" XXX
 SG_ ZEROS : 37|4@0+ (1,0) [0|255] "" XXX
 SG_ COUNTER : 38|1@0+ (1,0) [0|1] "" XXX
 SG_ STATE_3 : 39|1@0+ (1,0) [0|1] "" XXX
 SG_ REL_SPEED : 53|14@0- (0.01,0) [-81.92|81.92] "" XXX
 SG_ STATE_2 : 55|2@0+ (1,0) [0|3] "" XXX

BO_ 1296 RADAR_TRACK_510: 8 RADAR
 SG_ UNKNOWN_1 : 7|8@0- (1,0) [-128|127] "" XXX
 SG_ AZIMUTH : 12|10@0- (0.2,0) [-102.4|102.2] "" XXX
 SG_ STATE : 15|3@0+ (1,0) [0|7] "" XXX
 SG_ LONG_DIST : 18|11@0+ (0.1,0) [0|204.7] "" XXX
 SG_ REL_ACCEL : 33|10@0- (0.02,0) [-10.24|10.22] "" XXX
 SG_ ZEROS : 37|4@0+ (1,0) [0|255] "" XXX
 SG_ COUNTER : 38|1@0+ (1,0) [0|1] "" XXX
 SG_ STATE_3 : 39|1@0+ (1,0) [0|1] "" XXX
 SG_ REL_SPEED : 53|14@0- (0.01,0) [-81.92|81.92] "" XXX
 SG_ STATE_2 : 55|2@0+ (1,0) [0|3] "" XXX

BO_ 1297 RADAR_TRACK_511: 8 RADAR
 SG_ UNKNOWN_1 : 7|8@0- (1,0) [-128|127] "" XXX
 SG_ AZIMUTH : 12|10@0- (0.2,0) [-102.4|102.2] "" XXX
 SG_ STATE : 15|3@0+ (1,0) [0|7] "" XXX
 SG_ LONG_DIST : 18|11@0+ (0.1,0) [0|204.7] "" XXX
 SG_ REL_ACCEL : 33|10@0- (0.02,0) [-10.24|10.22] "" XXX
 SG_ ZEROS : 37|4@0+ (1,0) [0|255] "" XXX
 SG_ COUNTER : 38|1@0+ (1,0) [0|1] "" XXX
 SG_ STATE_3 : 39|1@0+ (1,0) [0|1] "" XXX
 SG_ REL_SPEED : 53|14@0- (0.01,0) [-81.92|81.92] "" XXX
 SG_ STATE_2 : 55|2@0+ (1,0) [0|3] "" XXX

BO_ 1298 RADAR_TRACK_512: 8 RADAR
 SG_ UNKNOWN_1 : 7|8@0- (1,0) [-128|127] "" XXX
 SG_ AZIMUTH : 12|10@0- (0.2,0) [-102.4|102.2] "" XXX
 SG_ STATE : 15|3@0+ (1,0) [0|7] "" XXX
 SG_ LONG_DIST : 18|11@0+ (0.1,0) [0|204.7] "" XXX
 SG_ REL_ACCEL : 33|10@0- (0.02,0) [-10.24|10.22] "" XXX
 SG_ ZEROS : 37|4@0+ (1,0) [0|255] "" XXX
 SG_ COUNTER : 38|1@0+ (1,0) [0|1] "" XXX
 SG_ STATE_3 : 39|1@0+ (1,0) [0|1] "" XXX
 SG_ REL_SPEED : 53|14@0- (0.01,0) [-81.92|81.92] "" XXX
 SG_ STATE_2 : 55|2@0+ (1,0) [0|3] "" XXX

BO_ 1299 RADAR_TRACK_513: 8 RADAR
 SG_ UNKNOWN_1 : 7|8@0- (1,0) [-128|127] "" XXX
 SG_ AZIMUTH : 12|10@0- (0.2,0) [-102.4|102.2] "" XXX
 SG_ STATE : 15|3@0+ (1,0) [0|7] "" XXX
 SG_ LONG_DIST : 18|11@0+ (0.1,0) [0|204.7] "" XXX
 SG_ REL_ACCEL : 33|10@0- (0.02,0) [-10.24|10.22] "" XXX
 SG_ ZEROS : 37|4@0+ (1,0) [0|255] "" XXX
 SG_ COUNTER : 38|1@0+ (1,0) [0|1] "" XXX
 SG_ STATE_3 : 39|1@0+ (1,0) [0|1] "" XXX
 SG_ REL_SPEED : 53|14@0- (0.01,0) [-81.92|81.92] "" XXX
 SG_ STATE_2 : 55|2@0+ (1,0) [0|3] "" XXX

BO_ 1300 RADAR_TRACK_514: 8 RADAR
 SG_ UNKNOWN_1 : 7|8@0- (1,0) [-128|127] "" XXX
 SG_ AZIMUTH : 12|10@0- (0.2,0) [-102.4|102.2] "" XXX
 SG_ STATE : 15|3@0+ (1,0) [0|7] "" XXX
 SG_ LONG_DIST : 18|11@0+ (0.1,0) [0|204.7] "" XXX
 SG_ REL_ACCEL : 33|10@0- (0.02,0) [-10.24|10.22] "" XXX
 SG_ ZEROS : 37|4@0+ (1,0) [0|255] "" XXX
 SG_ COUNTER : 38|1@0+ (1,0) [0|1] "" XXX
 SG_ STATE_3 : 39|1@0+ (1,0) [0|1] "" XXX
 SG_ REL_SPEED : 53|14@0- (0.01,0) [-81.92|81.92] "" XXX
 SG_ STATE_2 : 55|2@0+ (1,0) [0|3] "" XXX

BO_ 1301 RADAR_TRACK_515: 8 RADAR
 SG_ UNKNOWN_1 : 7|8@0- (1,0) [-128|127] "" XXX
 SG_ AZIMUTH : 12|10@0- (0.2,0) [-102.4|102.2] "" XXX
 SG_ STATE : 15|3@0+ (1,0) [0|7] "" XXX
 SG_ LONG_DIST : 18|11@0+ (0.1,0) [0|204.7] "" XXX
 SG_ REL_ACCEL : 33|10@0- (0.02,0) [-10.24|10.22] "" XXX
 SG_ ZEROS : 37|4@0+ (1,0) [0|255] "" XXX
 SG_ COUNTER : 38|1@0+ (1,0) [0|1] "" XXX
 SG_ STATE_3 : 39|1@0+ (1,0) [0|1] "" XXX
 SG_ REL_SPEED : 53|14@0- (0.01,0) [-81.92|81.92] "" XXX
 SG_ STATE_2 : 55|2@0+ (1,0) [0|3] "" XXX

BO_ 1302 RADAR_TRACK_516: 8 RADAR
 SG_ UNKNOWN_1 : 7|8@0- (1,0) [-128|127] "" XXX
 SG_ AZIMUTH : 12|10@0- (0.2,0) [-102.4|102.2] "" XXX
 SG_ STATE : 15|3@0+ (1,0) [0|7] "" XXX
 SG_ LONG_DIST : 18|11@0+ (0.1,0) [0|204.7] "" XXX
 SG_ REL_ACCEL : 33|10@0- (0.02,0) [-10.24|10.22] "" XXX
 SG_ ZEROS : 37|4@0+ (1,0) [0|255] "" XXX
 SG_ COUNTER : 38|1@0+ (1,0) [0|1] "" XXX
 SG_ STATE_3 : 39|1@0+ (1,0) [0|1] "" XXX
 SG_ REL_SPEED : 53|14@0- (0.01,0) [-81.92|81.92] "" XXX
 SG_ STATE_2 : 55|2@0+ (1,0) [0|3] "" XXX

BO_ 1303 RADAR_TRACK_517: 8 RADAR
 SG_ UNKNOWN_1 : 7|8@0- (1,0) [-128|127] "" XXX
 SG_ AZIMUTH : 12|10@0- (0.2,0) [-102.4|102.2] "" XXX
 SG_ STATE : 15|3@0+ (1,0) [0|7] "" XXX
 SG_ LONG_DIST : 18|11@0+ (0.1,0) [0|204.7] "" XXX
 SG_ REL_ACCEL : 33|10@0- (0.02,0) [-10.24|10.22] "" XXX
 SG_ ZEROS : 37|4@0+ (1,0) [0|255] "" XXX
 SG_ COUNTER : 38|1@0+ (1,0) [0|1] "" XXX
 SG_ STATE_3 : 39|1@0+ (1,0) [0|1] "" XXX
 SG_ REL_SPEED : 53|14@0- (0.01,0) [-81.92|81.92] "" XXX
 SG_ STATE_2 : 55|2@0+ (1,0) [0|3] "" XXX

BO_ 1304 RADAR_TRACK_518: 8 RADAR
 SG_ UNKNOWN_1 : 7|8@0- (1,0) [-128|127] "" XXX
 SG_ AZIMUTH : 12|10@0- (0.2,0) [-102.4|102.2] "" XXX
 SG_ STATE : 15|3@0+ (1,0) [0|7] "" XXX
 SG_ LONG_DIST : 18|11@0+ (0.1,0) [0|204.7] "" XXX
 SG_ REL_ACCEL : 33|10@0- (0.02,0) [-10.24|10.22] "" XXX
 SG_ ZEROS : 37|4@0+ (1,0) [0|255] "" XXX
 SG_ COUNTER : 38|1@0+ (1,0) [0|1] "" XXX
 SG_ STATE_3 : 39|1@0+ (1,0) [0|1] "" XXX
 SG_ REL_SPEED : 53|14@0- (0.01,0) [-81.92|81.92] "" XXX
 SG_ STATE_2 : 55|2@0+ (1,0) [0|3] "" XXX

BO_ 1305 RADAR_TRACK_519: 8 RADAR
 SG_ UNKNOWN_1 : 7|8@0- (1,0) [-128|127] "" XXX
 SG_ AZIMUTH : 12|10@0- (0.2,0) [-102.4|102.2] "" XXX
 SG_ STATE : 15|3@0+ (1,0) [0|7] "" XXX
 SG_ LONG_DIST : 18|11@0+ (0.1,0) [0|204.7] "" XXX
 SG_ REL_ACCEL : 33|10@0- (0.02,0) [-10.24|10.22] "" XXX
 SG_ ZEROS : 37|4@0+ (1,0) [0|255] "" XXX
 SG_ COUNTER : 38|1@0+ (1,0) [0|1] "" XXX
 SG_ STATE_3 : 39|1@0+ (1,0) [0|1] "" XXX
 SG_ REL_SPEED : 53|14@0- (0.01,0) [-81.92|81.92] "" XXX
 SG_ STATE_2 : 55|2@0+ (1,0) [0|3] "" XXX

BO_ 1306 RADAR_TRACK_51a: 8 RADAR
 SG_ UNKNOWN_1 : 7|8@0- (1,0) [-128|127] "" XXX
 SG_ AZIMUTH : 12|10@0- (0.2,0) [-102.4|102.2] "" XXX
 SG_ STATE : 15|3@0+ (1,0) [0|7] "" XXX
 SG_ LONG_DIST : 18|11@0+ (0.1,0) [0|204.7] "" XXX
 SG_ REL_ACCEL : 33|10@0- (0.02,0) [-10.24|10.22] "" XXX
 SG_ ZEROS : 37|4@0+ (1,0) [0|255] "" XXX
 SG_ COUNTER : 38|1@0+ (1,0) [0|1] "" XXX
 SG_ STATE_3 : 39|1@0+ (1,0) [0|1] "" XXX
 SG_ REL_SPEED : 53|14@0- (0.01,0) [-81.92|81.92] "" XXX
 SG_ STATE_2 : 55|2@0+ (1,0) [0|3] "" XXX

BO_ 1307 RADAR_TRACK_51b: 8 RADAR
 SG_ UNKNOWN_1 : 7|8@0- (1,0) [-128|127] "" XXX
 SG_ AZIMUTH : 12|10@0- (0.2,0) [-102.4|102.2] "" XXX
 SG_ STATE : 15|3@0+ (1,0) [0|7] "" XXX
 SG_ LONG_DIST : 18|11@0+ (0.1,0) [0|204.7] "" XXX
 SG_ REL_ACCEL : 33|10@0- (0.02,0) [-10.24|10.22] "" XXX
 SG_ ZEROS : 37|4@0+ (1,0) [0|255] "" XXX
 SG_ COUNTER : 38|1@0+ (1,0) [0|1] "" XXX
 SG_ STATE_3 : 39|1@0+ (1,0) [0|1] "" XXX
 SG_ REL_SPEED : 53|14@0- (0.01,0) [-81.92|81.92] "" XXX
 SG_ STATE_2 : 55|2@0+ (1,0) [0|3] "" XXX

BO_ 1308 RADAR_TRACK_51c: 8 RADAR
 SG_ UNKNOWN_1 : 7|8@0- (1,0) [-128|127] "" XXX
 SG_ AZIMUTH : 12|10@0- (0.2,0) [-102.4|102.2] "" XXX
 SG_ STATE : 15|3@0+ (1,0) [0|7] "" XXX
 SG_ LONG_DIST : 18|11@0+ (0.1,0) [0|204.7] "" XXX
 SG_ REL_ACCEL : 33|10@0- (0.02,0) [-10.24|10.22] "" XXX
 SG_ ZEROS : 37|4@0+ (1,0) [0|255] "" XXX
 SG_ COUNTER : 38|1@0+ (1,0) [0|1] "" XXX
 SG_ STATE_3 : 39|1@0+ (1,0) [0|1] "" XXX
 SG_ REL_SPEED : 53|14@0- (0.01,0) [-81.92|81.92] "" XXX
 SG_ STATE_2 : 55|2@0+ (1,0) [0|3] "" XXX

BO_ 1309 RADAR_TRACK_51d: 8 RADAR
 SG_ UNKNOWN_1 : 7|8@0- (1,0) [-128|127] "" XXX
 SG_ AZIMUTH : 12|10@0- (0.2,0) [-102.4|102.2] "" XXX
 SG_ STATE : 15|3@0+ (1,0) [0|7] "" XXX
 SG_ LONG_DIST : 18|11@0+ (0.1,0) [0|204.7] "" XXX
 SG_ REL_ACCEL : 33|10@0- (0.02,0) [-10.24|10.22] "" XXX
 SG_ ZEROS : 37|4@0+ (1,0) [0|255] "" XXX
 SG_ COUNTER : 38|1@0+ (1,0) [0|1] "" XXX
 SG_ STATE_3 : 39|1@0+ (1,0) [0|1] "" XXX
 SG_ REL_SPEED : 53|14@0- (0.01,0) [-81.92|81.92] "" XXX
 SG_ STATE_2 : 55|2@0+ (1,0) [0|3] "" XXX

BO_ 1310 RADAR_TRACK_51e: 8 RADAR
 SG_ UNKNOWN_1 : 7|8@0- (1,0) [-128|127] "" XXX
 SG_ AZIMUTH : 12|10@0- (0.2,0) [-102.4|102.2] "" XXX
 SG_ STATE : 15|3@0+ (1,0) [0|7] "" XXX
 SG_ LONG_DIST : 18|11@0+ (0.1,0) [0|204.7] "" XXX
 SG_ REL_ACCEL : 33|10@0- (0.02,0) [-10.24|10.22] "" XXX
 SG_ ZEROS : 37|4@0+ (1,0) [0|255] "" XXX
 SG_ COUNTER : 38|1@0+ (1,0) [0|1] "" XXX
 SG_ STATE_3 : 39|1@0+ (1,0) [0|1] "" XXX
 SG_ REL_SPEED : 53|14@0- (0.01,0) [-81.92|81.92] "" XXX
 SG_ STATE_2 : 55|2@0+ (1,0) [0|3] "" XXX

BO_ 1311 RADAR_TRACK_51f: 8 RADAR
 SG_ UNKNOWN_1 : 7|8@0- (1,0) [-128|127] "" XXX
 SG_ AZIMUTH : 12|10@0- (0.2,0) [-102.4|102.2] "" XXX
 SG_ STATE : 15|3@0+ (1,0) [0|7] "" XXX
 SG_ LONG_DIST : 18|11@0+ (0.1,0) [0|204.7] "" XXX
 SG_ REL_ACCEL : 33|10@0- (0.02,0) [-10.24|10.22] "" XXX
 SG_ ZEROS : 37|4@0+ (1,0) [0|255] "" XXX
 SG_ COUNTER : 38|1@0+ (1,0) [0|1] "" XXX
 SG_ STATE_3 : 39|1@0+ (1,0) [0|1] "" XXX
 SG_ REL_SPEED : 53|14@0- (0.01,0) [-81.92|81.92] "" XXX
 SG_ STATE_2 : 55|2@0+ (1,0) [0|3] "" XXX

BO_ 1312 CGW3: 8 BCM
 SG_ CR_Photosensor_LH : 0|8@1+ (78.125,0.0) [0.0|20000.0] ""  DATC,DATC
 SG_ CR_Photosensor_RH : 10|8@1+ (78.125,0.0) [0.0|20000.0] ""  DATC,DATC
 SG_ CF_Hoodsw_memory : 22|2@1+ (1.0,0.0) [0.0|3.0] ""  EMS,EMS
 SG_ C_MirOutTempSns : 24|8@1+ (0.5,-40.5) [-40.0|60.0] "deg"  AAF,CLU,DATC,EMS,SPAS,AAF,DATC,EMS,SPAS

BO_ 1313 GW_DDM_PE: 8 BCM
 SG_ C_DRVDoorStatus : 0|2@1+ (1.0,0.0) [0.0|3.0] ""  CLU
 SG_ C_ASTDoorStatus : 2|2@1+ (1.0,0.0) [0.0|3.0] ""  CLU
 SG_ C_RLDoorStatus : 4|2@1+ (1.0,0.0) [0.0|3.0] ""  CLU
 SG_ C_RRDoorStatus : 6|2@1+ (1.0,0.0) [0.0|3.0] ""  CLU
 SG_ C_TrunkStatus : 8|2@1+ (1.0,0.0) [0.0|3.0] ""  CLU
 SG_ C_OSMirrorStatus : 10|2@1+ (1.0,0.0) [0.0|3.0] ""  CLU

BO_ 1314 GW_IPM_PE_1: 8 BCM
 SG_ C_AV_Tail : 0|2@1+ (1.0,0.0) [0.0|3.0] ""  CLU
 SG_ C_ParkingBrakeSW : 2|2@1+ (1.0,0.0) [0.0|3.0] ""  CLU
 SG_ C_RKECMD : 4|4@1+ (1.0,0.0) [0.0|15.0] ""  CLU
 SG_ C_BAState : 8|2@1+ (1.0,0.0) [0.0|3.0] ""  CLU
 SG_ C_IGNSW : 12|3@1+ (1.0,0.0) [0.0|7.0] ""  CLU
 SG_ C_CountryCfg : 16|3@1+ (1.0,0.0) [0.0|7.0] ""  CLU
 SG_ C_TailLampActivity : 26|2@1+ (1.0,0.0) [0.0|3.0] ""  CLU
 SG_ RearSW_RSELockOnOff : 28|2@1+ (1.0,0.0) [0.0|3.0] ""  CLU
 SG_ C_SMKTeleCrankingState : 32|2@1+ (1.0,0.0) [0.0|3.0] ""  CLU
 SG_ C_SMKTeleCrankingFailRes : 34|2@1+ (1.0,0.0) [0.0|3.0] ""  CLU

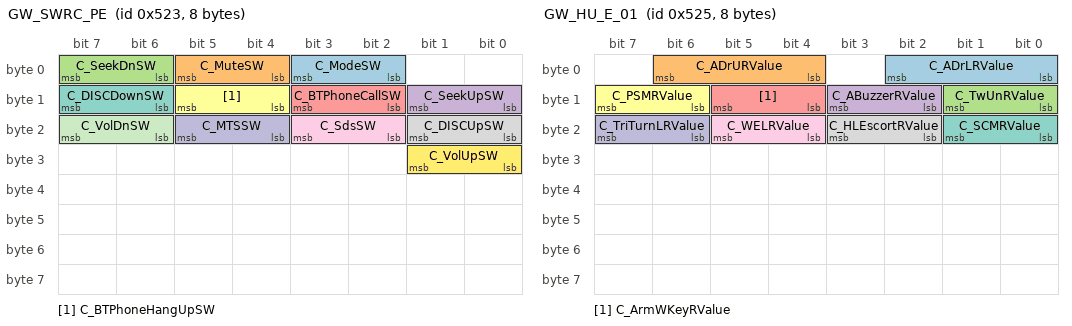
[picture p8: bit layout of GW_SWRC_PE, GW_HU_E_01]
BO_ 1315 GW_SWRC_PE: 8 BCM
 SG_ C_ModeSW : 2|2@1+ (1.0,0.0) [0.0|3.0] ""  CLU
 SG_ C_MuteSW : 4|2@1+ (1.0,0.0) [0.0|3.0] ""  CLU
 SG_ C_SeekDnSW : 6|2@1+ (1.0,0.0) [0.0|3.0] ""  CLU
 SG_ C_SeekUpSW : 8|2@1+ (1.0,0.0) [0.0|3.0] ""  CLU
 SG_ C_BTPhoneCallSW : 10|2@1+ (1.0,0.0) [0.0|3.0] ""  CLU
 SG_ C_BTPhoneHangUpSW : 12|2@1+ (1.0,0.0) [0.0|3.0] ""  CLU
 SG_ C_DISCDownSW : 14|2@1+ (1.0,0.0) [0.0|3.0] ""  CLU
 SG_ C_DISCUpSW : 16|2@1+ (1.0,0.0) [0.0|3.0] ""  CLU
 SG_ C_SdsSW : 18|2@1+ (1.0,0.0) [0.0|3.0] ""  CLU
 SG_ C_MTSSW : 20|2@1+ (1.0,0.0) [0.0|3.0] ""  CLU
 SG_ C_VolDnSW : 22|2@1+ (1.0,0.0) [0.0|3.0] ""  CLU
 SG_ C_VolUpSW : 24|2@1+ (1.0,0.0) [0.0|3.0] ""  CLU

BO_ 1316 GW_HU_E_00: 8 BCM
 SG_ C_ADrLUNValueConf : 0|2@1+ (1.0,0.0) [0.0|3.0] ""  CLU
 SG_ C_TwUnNValueConf : 2|2@1+ (1.0,0.0) [0.0|3.0] ""  CLU
 SG_ C_AlarmNValueConf : 4|2@1+ (1.0,0.0) [0.0|3.0] ""  CLU
 SG_ C_PSMNValueConf : 6|2@1+ (1.0,0.0) [0.0|3.0] ""  CLU
 SG_ C_SCMNValueConf : 8|2@1+ (1.0,0.0) [0.0|3.0] ""  CLU
 SG_ C_HLEscortNValueConf : 10|2@1+ (1.0,0.0) [0.0|3.0] ""  CLU
 SG_ C_WELNValueConf : 12|2@1+ (1.0,0.0) [0.0|3.0] ""  CLU
 SG_ C_TriTurnLNValueConf : 14|2@1+ (1.0,0.0) [0.0|3.0] ""  CLU

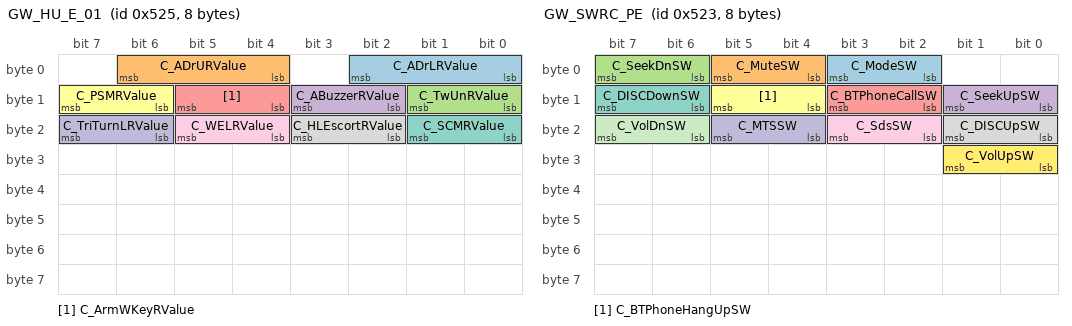
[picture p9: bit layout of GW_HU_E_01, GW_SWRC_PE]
BO_ 1317 GW_HU_E_01: 8 BCM
 SG_ C_ADrLRValue : 0|3@1+ (1.0,0.0) [0.0|7.0] ""  CLU
 SG_ C_ADrURValue : 4|3@1+ (1.0,0.0) [0.0|7.0] ""  CLU
 SG_ C_TwUnRValue : 8|2@1+ (1.0,0.0) [0.0|3.0] ""  CLU
 SG_ C_ABuzzerRValue : 10|2@1+ (1.0,0.0) [0.0|3.0] ""  CLU
 SG_ C_ArmWKeyRValue : 12|2@1+ (1.0,0.0) [0.0|3.0] ""  CLU
 SG_ C_PSMRValue : 14|2@1+ (1.0,0.0) [0.0|3.0] ""  CLU
 SG_ C_SCMRValue : 16|2@1+ (1.0,0.0) [0.0|3.0] ""  CLU
 SG_ C_HLEscortRValue : 18|2@1+ (1.0,0.0) [0.0|3.0] ""  CLU
 SG_ C_WELRValue : 20|2@1+ (1.0,0.0) [0.0|3.0] ""  CLU
 SG_ C_TriTurnLRValue : 22|2@1+ (1.0,0.0) [0.0|3.0] ""  CLU

BO_ 1318 HU_GW_E_00: 8 CLU
 SG_ C_ADrLURValueReq : 0|2@1+ (1.0,0.0) [0.0|3.0] ""  BCM
 SG_ C_TwUnRValueReq : 2|2@1+ (1.0,0.0) [0.0|3.0] ""  BCM
 SG_ C_AlarmRValueReq : 4|2@1+ (1.0,0.0) [0.0|3.0] ""  BCM
 SG_ C_IMSRValueReq : 6|2@1+ (1.0,0.0) [0.0|3.0] ""  BCM
 SG_ C_HLEscortRValueReq : 8|2@1+ (1.0,0.0) [0.0|3.0] ""  BCM
 SG_ C_WELRValueReq : 10|2@1+ (1.0,0.0) [0.0|3.0] ""  BCM
 SG_ C_TriTurnLRValueReq : 12|2@1+ (1.0,0.0) [0.0|3.0] ""  BCM
 SG_ C_SNVWarnRValueReq : 14|2@1+ (1.0,0.0) [0.0|3.0] ""  BCM
 SG_ C_LkasWarnRValueReq : 16|2@1+ (1.0,0.0) [0.0|3.0] ""  BCM

BO_ 1348 Navi_HU: 8 XXX
 SG_ SpeedLim_Nav_Clu : 7|8@0+ (1,0) [0|255] "" XXX
 SG_ SpeedLim_Nav_General : 29|1@0+ (1,0) [0|1] "" XXX
 SG_ SpeedLim_Nav_Cam : 30|1@0+ (1,0) [0|1] "" XXX

BO_ 1355 EV_PC6: 8 CGW
 SG_ CF_Vcu_SbwWarnMsg : 16|3@1+ (1,0) [0|7] "" Vector__XXX

BO_ 1426 LABEL11: 8 XXX
 SG_ CC_React : 34|1@1+ (1,0) [0|1] "" XXX

BO_ 1430 EV_PC2: 8 CGW
 SG_ CR_Ldc_ActVol_LS_V : 32|8@1+ (0.1,0) [0|0] "V" Vector__XXX

BO_ 1535 EV_PC10: 8 CGW
 SG_ CF_Vcu_EpbRequest : 37|1@1+ (1,0) [0|0] "" Vector__XXX

VAL_ 1056 SCCInfoDisplay 0 "No Message" 2 "Cruise Control" 3 "Lost Lead" 4 "Standstill";
VAL_ 1057 ACCMode 0 "off" 1 "enabled" 2 "driver_override" 3 "off_maybe_fault";
VAL_ 1157 HDA_Icon_State 0 "no_hda" 1 "white_hda" 2 "green_hda";
VAL_ 1157 HDA_SysWarning 0 "no_message" 1 "driving_convenience_systems_cancelled" 2 "highway_drive_assist_system_cancelled";
VAL_ 1157 LFA_Icon_State 0 "no_wheel" 1 "white_wheel" 2 "green_wheel" 3 "green_wheel_blink";
VAL_ 1157 LFA_SysWarning 0 "no_message" 1 "switching_to_hda" 2 "switching_to_scc" 3 "lfa_error" 4 "check_hda" 5 "keep_hands_on_wheel_orange" 6 "keep_hands_on_wheel_red";
VAL_ 274 CUR_GR 1 "D" 2 "D" 3 "D" 4 "D" 5 "D" 6 "D" 7 "D" 8 "D" 14 "R" 0 "P";
VAL_ 882 Elect_Gear_Shifter 5 "D" 8 "S" 6 "N" 7 "R" 4 "S" 0 "P";
VAL_ 905 ACCMode 0 "off" 1 "enabled" 2 "driver_override" 3 "off_maybe_fault" 4 "cancelled";
VAL_ 905 ObjDistStat 0 "no_object" 1 "receding" 2 "approaching";
VAL_ 909 CF_VSM_Warn 2 "FCW" 3 "AEB";

BS_:

BU_: XXX CAMERA FRONT_RADAR ADRV APRK

BS_:

BU_: IAP ODS _4WD BCM HUD DATC MDPS AAF_Tester AEMC SMK _4WD EPB CUBIS MTS TMU EVP CGW TPMS LPI DI_BOX SPAS EMS LCA TCU IBOX FATC AFLS FPCM SCC AHLS AVM ABS SNV OPI PGS SAS AAF Dummy LDWS_LKAS LVR ESC PSB CLU ECS ACU REA

BO_ 1318 HU_GW_E_00: 8 CLU
 SG_ C_ADrLURValueReq : 0|2@1+ (1.0,0.0) [0.0|3.0] ""  BCM
 SG_ C_TwUnRValueReq : 2|2@1+ (1.0,0.0) [0.0|3.0] ""  BCM
 SG_ C_AlarmRValueReq : 4|2@1+ (1.0,0.0) [0.0|3.0] ""  BCM
 SG_ C_IMSRValueReq : 6|2@1+ (1.0,0.0) [0.0|3.0] ""  BCM
 SG_ C_HLEscortRValueReq : 8|2@1+ (1.0,0.0) [0.0|3.0] ""  BCM
 SG_ C_WELRValueReq : 10|2@1+ (1.0,0.0) [0.0|3.0] ""  BCM
 SG_ C_TriTurnLRValueReq : 12|2@1+ (1.0,0.0) [0.0|3.0] ""  BCM
 SG_ C_SNVWarnRValueReq : 14|2@1+ (1.0,0.0) [0.0|3.0] ""  BCM
 SG_ C_LkasWarnRValueReq : 16|2@1+ (1.0,0.0) [0.0|3.0] ""  BCM

BO_ 1317 GW_HU_E_01: 8 BCM
 SG_ C_ADrLRValue : 0|3@1+ (1.0,0.0) [0.0|7.0] ""  CLU
 SG_ C_ADrURValue : 4|3@1+ (1.0,0.0) [0.0|7.0] ""  CLU
 SG_ C_TwUnRValue : 8|2@1+ (1.0,0.0) [0.0|3.0] ""  CLU
 SG_ C_ABuzzerRValue : 10|2@1+ (1.0,0.0) [0.0|3.0] ""  CLU
 SG_ C_ArmWKeyRValue : 12|2@1+ (1.0,0.0) [0.0|3.0] ""  CLU
 SG_ C_PSMRValue : 14|2@1+ (1.0,0.0) [0.0|3.0] ""  CLU
 SG_ C_SCMRValue : 16|2@1+ (1.0,0.0) [0.0|3.0] ""  CLU
 SG_ C_HLEscortRValue : 18|2@1+ (1.0,0.0) [0.0|3.0] ""  CLU
 SG_ C_WELRValue : 20|2@1+ (1.0,0.0) [0.0|3.0] ""  CLU
 SG_ C_TriTurnLRValue : 22|2@1+ (1.0,0.0) [0.0|3.0] ""  CLU

BO_ 1316 GW_HU_E_00: 8 BCM
 SG_ C_ADrLUNValueConf : 0|2@1+ (1.0,0.0) [0.0|3.0] ""  CLU
 SG_ C_TwUnNValueConf : 2|2@1+ (1.0,0.0) [0.0|3.0] ""  CLU
 SG_ C_AlarmNValueConf : 4|2@1+ (1.0,0.0) [0.0|3.0] ""  CLU
 SG_ C_PSMNValueConf : 6|2@1+ (1.0,0.0) [0.0|3.0] ""  CLU
 SG_ C_SCMNValueConf : 8|2@1+ (1.0,0.0) [0.0|3.0] ""  CLU
 SG_ C_HLEscortNValueConf : 10|2@1+ (1.0,0.0) [0.0|3.0] ""  CLU
 SG_ C_WELNValueConf : 12|2@1+ (1.0,0.0) [0.0|3.0] ""  CLU
 SG_ C_TriTurnLNValueConf : 14|2@1+ (1.0,0.0) [0.0|3.0] ""  CLU

BO_ 1315 GW_SWRC_PE: 8 BCM
 SG_ C_ModeSW : 2|2@1+ (1.0,0.0) [0.0|3.0] ""  CLU
 SG_ C_MuteSW : 4|2@1+ (1.0,0.0) [0.0|3.0] ""  CLU
 SG_ C_SeekDnSW : 6|2@1+ (1.0,0.0) [0.0|3.0] ""  CLU
 SG_ C_SeekUpSW : 8|2@1+ (1.0,0.0) [0.0|3.0] ""  CLU
 SG_ C_BTPhoneCallSW : 10|2@1+ (1.0,0.0) [0.0|3.0] ""  CLU
 SG_ C_BTPhoneHangUpSW : 12|2@1+ (1.0,0.0) [0.0|3.0] ""  CLU
 SG_ C_DISCDownSW : 14|2@1+ (1.0,0.0) [0.0|3.0] ""  CLU
 SG_ C_DISCUpSW : 16|2@1+ (1.0,0.0) [0.0|3.0] ""  CLU
 SG_ C_SdsSW : 18|2@1+ (1.0,0.0) [0.0|3.0] ""  CLU
 SG_ C_MTSSW : 20|2@1+ (1.0,0.0) [0.0|3.0] ""  CLU
 SG_ C_VolDnSW : 22|2@1+ (1.0,0.0) [0.0|3.0] ""  CLU
 SG_ C_VolUpSW : 24|2@1+ (1.0,0.0) [0.0|3.0] ""  CLU

BO_ 1314 GW_IPM_PE_1: 8 BCM
 SG_ C_AV_Tail : 0|2@1+ (1.0,0.0) [0.0|3.0] ""  CLU
 SG_ C_ParkingBrakeSW : 2|2@1+ (1.0,0.0) [0.0|3.0] ""  CLU
 SG_ C_RKECMD : 4|4@1+ (1.0,0.0) [0.0|15.0] ""  CLU
 SG_ C_BAState : 8|2@1+ (1.0,0.0) [0.0|3.0] ""  CLU
 SG_ C_IGNSW : 12|3@1+ (1.0,0.0) [0.0|7.0] ""  CLU
 SG_ C_CountryCfg : 16|3@1+ (1.0,0.0) [0.0|7.0] ""  CLU
 SG_ C_TailLampActivity : 26|2@1+ (1.0,0.0) [0.0|3.0] ""  CLU
 SG_ RearSW_RSELockOnOff : 28|2@1+ (1.0,0.0) [0.0|3.0] ""  CLU
 SG_ C_SMKTeleCrankingState : 32|2@1+ (1.0,0.0) [0.0|3.0] ""  CLU
 SG_ C_SMKTeleCrankingFailRes : 34|2@1+ (1.0,0.0) [0.0|3.0] ""  CLU

BO_ 1057 SCC12: 8 SCC
 SG_ CF_VSM_Prefill : 0|1@1+ (1,0) [0|1] "" ESC
 SG_ CF_VSM_DecCmdAct : 1|1@1+ (1,0) [0|1] "" ESC
 SG_ CF_VSM_HBACmd : 2|2@1+ (1,0) [0|3] "" ESC
 SG_ CF_VSM_Warn : 4|2@1+ (1,0) [0|3] "" CLU,ESC,IAP
 SG_ CF_VSM_Stat : 6|2@1+ (1,0) [0|3] "" CLU,ESC,PSB
 SG_ CF_VSM_BeltCmd : 8|3@1+ (1,0) [0|7] "" ESC,PSB
 SG_ ACCFailInfo : 11|2@1+ (1,0) [0|3] "" CLU,CUBIS,ESC,IBOX
 SG_ ACCMode : 13|2@1+ (1,0) [0|3] "" CLU,ESC,IBOX,TCU
 SG_ StopReq : 15|1@1+ (1,0) [0|1] "" EPB,ESC
 SG_ CR_VSM_DecCmd : 16|8@1+ (0.01,0) [0|2.55] "g" ESC
 SG_ TakeOverReq : 35|1@1+ (1,0) [0|1] "" CLU,ESC,TCU
 SG_ PreFill : 36|1@1+ (1,0) [0|1] "" ESC,TCU
 SG_ CF_VSM_ConfMode : 48|2@1+ (1,0) [0|3] "" CLU,ESC
 SG_ AEB_Failinfo : 50|2@1+ (1,0) [0|3] "" CLU,ESC
 SG_ AEB_Status : 52|2@1+ (1,0) [0|3] "" CLU,ESC
 SG_ AEB_CmdAct : 54|1@1+ (1,0) [0|1] "" ESC
 SG_ AEB_StopReq : 55|1@1+ (1,0) [0|1] "" CLU,ESC
 SG_ CR_VSM_Alive : 56|4@1+ (1,0) [0|15] "" ESC,PSB
 SG_ CR_VSM_ChkSum : 60|4@1+ (1,0) [0|15] "" ESC,PSB
 SG_ aReqValue : 37|11@1+ (0.01,-10.23) [-10.23|10.24] "m/s^2" Vector__XXX
 SG_ aReqRaw : 24|11@1+ (0.01,-10.23) [-10.23|10.24] "m/s^2" Vector__XXX

BO_ 1313 GW_DDM_PE: 8 BCM
 SG_ C_DRVDoorStatus : 0|2@1+ (1.0,0.0) [0.0|3.0] ""  CLU
 SG_ C_ASTDoorStatus : 2|2@1+ (1.0,0.0) [0.0|3.0] ""  CLU
 SG_ C_RLDoorStatus : 4|2@1+ (1.0,0.0) [0.0|3.0] ""  CLU
 SG_ C_RRDoorStatus : 6|2@1+ (1.0,0.0) [0.0|3.0] ""  CLU
 SG_ C_TrunkStatus : 8|2@1+ (1.0,0.0) [0.0|3.0] ""  CLU
 SG_ C_OSMirrorStatus : 10|2@1+ (1.0,0.0) [0.0|3.0] ""  CLU

BO_ 1056 SCC11: 8 SCC
 SG_ MainMode_ACC : 0|1@1+ (1,0) [0|1] "" CLU,EMS,ESC
 SG_ SCCInfoDisplay : 1|3@1+ (1,0) [0|7] "" CLU,ESC
 SG_ AliveCounterACC : 4|4@1+ (1,0) [0|15] "" CLU,EMS,ESC,TCU
 SG_ VSetDis : 8|8@1+ (1,0) [0|255] "km/h or MPH" CLU,ESC,TCU
 SG_ ObjValid : 16|1@1+ (1,0) [0|1] "" CLU,ESC,TCU
 SG_ DriverAlertDisplay : 17|2@1+ (1,0) [0|3] "" CLU,ESC
 SG_ TauGapSet : 19|3@1+ (1,0) [0|7] "" CLU,ESC,TCU
 SG_ Navi_SCC_Curve_Status : 56|2@1+ (1,0) [0|3] "" CLU
 SG_ Navi_SCC_Curve_Act : 58|2@1+ (1,0) [0|3] "" CLU
 SG_ Navi_SCC_Camera_Act : 60|2@1+ (1,0) [0|3] "" CLU
 SG_ Navi_SCC_Camera_Status : 62|2@1+ (1,0) [0|3] "" CLU
 SG_ ACC_ObjStatus : 22|2@1+ (1,0) [0|3] "" ABS,ESC
 SG_ ACC_ObjLatPos : 24|9@1+ (0.1,-20) [-20|31.1] "m" ABS,ESC
 SG_ ACC_ObjRelSpd : 44|12@1+ (0.1,-170) [-170|239.5] "m/s" ABS,ESC
 SG_ ACC_ObjDist : 33|11@1+ (0.1,0) [0|204.7] "m" ABS,ESC

BO_ 1312 CGW3: 8 BCM
 SG_ CR_Photosensor_LH : 0|8@1+ (78.125,0.0) [0.0|20000.0] ""  DATC,DATC
 SG_ CR_Photosensor_RH : 10|8@1+ (78.125,0.0) [0.0|20000.0] ""  DATC,DATC
 SG_ CF_Hoodsw_memory : 22|2@1+ (1.0,0.0) [0.0|3.0] ""  EMS,EMS
 SG_ C_MirOutTempSns : 24|8@1+ (0.5,-40.5) [-40.0|60.0] "deg"  AAF,CLU,DATC,EMS,SPAS,AAF,DATC,EMS,SPAS

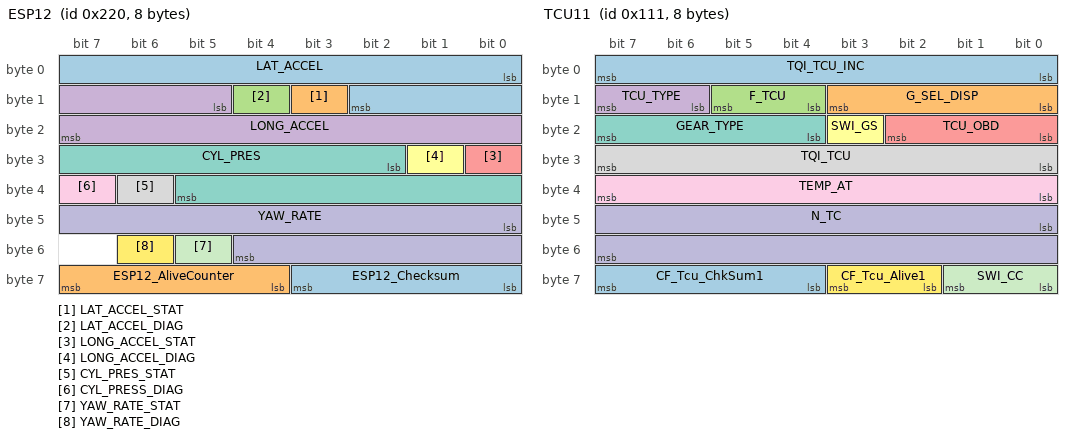
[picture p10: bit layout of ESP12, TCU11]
BO_ 544 ESP12: 8 ESC
 SG_ LAT_ACCEL : 0|11@1+ (0.01,-10.23) [-10.23|10.24] "m/s^2"  _4WD,ECS,IBOX,LCA,LDWS_LKAS,MDPS,PSB,SCC,TCU
 SG_ LAT_ACCEL_STAT : 11|1@1+ (1.0,0.0) [0.0|1.0] ""  _4WD,IBOX,LDWS_LKAS,MDPS,PSB,SCC,TCU
 SG_ LAT_ACCEL_DIAG : 12|1@1+ (1.0,0.0) [0.0|1.0] ""  _4WD,IBOX,LDWS_LKAS,MDPS,PSB,SCC,TCU
 SG_ LONG_ACCEL : 13|11@1+ (0.01,-10.23) [-10.23|10.24] "m/s^2"  _4WD,ECS,EMS,EPB,IBOX,LCA,LDWS_LKAS,PSB,SCC,SPAS,TCU
 SG_ LONG_ACCEL_STAT : 24|1@1+ (1.0,0.0) [0.0|1.0] ""  _4WD,EMS,EPB,IBOX,LDWS_LKAS,PSB,SCC,SPAS,TCU
 SG_ LONG_ACCEL_DIAG : 25|1@1+ (1.0,0.0) [0.0|1.0] ""  _4WD,EMS,EPB,IBOX,LDWS_LKAS,PSB,SCC,SPAS,TCU
 SG_ CYL_PRES : 26|12@1+ (0.1,0.0) [0.0|409.5] "Bar"  _4WD,ECS,EMS,EPB,IBOX,LDWS_LKAS,PSB,SCC,TCU
 SG_ CYL_PRES_STAT : 38|1@1+ (1.0,0.0) [0.0|1.0] ""  _4WD,ECS,EMS,EPB,IBOX,LDWS_LKAS,PSB,SCC,TCU
 SG_ CYL_PRESS_DIAG : 39|1@1+ (1.0,0.0) [0.0|1.0] ""  _4WD,ECS,EMS,EPB,IBOX,PSB,SCC,TCU
 SG_ YAW_RATE : 40|13@1+ (0.01,-40.95) [-40.95|40.96] ""  _4WD,AFLS,IBOX,LCA,LDWS_LKAS,MDPS,PSB,SCC,SPAS,TCU
 SG_ YAW_RATE_STAT : 53|1@1+ (1.0,0.0) [0.0|1.0] ""  _4WD,AFLS,IBOX,LCA,LDWS_LKAS,MDPS,PSB,SCC,SPAS,TCU
 SG_ YAW_RATE_DIAG : 54|1@1+ (1.0,0.0) [0.0|1.0] ""  _4WD,AFLS,IBOX,LCA,LDWS_LKAS,MDPS,PSB,SCC,SPAS,TCU
 SG_ ESP12_Checksum : 56|4@1+ (1.0,0.0) [0.0|15.0] ""  _4WD,EMS,LPI,TCU,TMU
 SG_ ESP12_AliveCounter : 60|4@1+ (1.0,0.0) [0.0|15.0] ""  _4WD,EMS,LPI,TCU,TMU

BO_ 1307 CLU16: 8 CLU
 SG_ CF_Clu_TirePressUnitNValueSet : 0|3@1+ (1.0,0.0) [0.0|7.0] ""  TPMS
 SG_ CF_Clu_SlifNValueSet : 3|2@1+ (1.0,0.0) [0.0|3.0] ""  LDWS_LKAS
 SG_ CF_Clu_RearWiperNValueSet : 12|2@1+ (1.0,0.0) [0.0|3.0] ""  BCM

BO_ 790 EMS11: 8 EMS
 SG_ SWI_IGK : 0|1@1+ (1.0,0.0) [0.0|1.0] ""  _4WD,ABS,ACU,AHLS,CUBIS,DI_BOX,ECS,EPB,ESC,IBOX,LDWS_LKAS,MDPS,REA,SAS,SCC,TCU
 SG_ F_N_ENG : 1|1@1+ (1.0,0.0) [0.0|1.0] ""  _4WD,ACU,AFLS,CLU,CUBIS,DATC,ECS,EPB,ESC,IBOX,MDPS,SCC,TCU
 SG_ ACK_TCS : 2|1@1+ (1.0,0.0) [0.0|1.0] ""  ESC,IBOX
 SG_ PUC_STAT : 3|1@1+ (1.0,0.0) [0.0|1.0] ""  _4WD,CLU,DATC,IBOX,TCU
 SG_ TQ_COR_STAT : 4|2@1+ (1.0,0.0) [0.0|3.0] ""  _4WD,ESC,IBOX,TCU
 SG_ RLY_AC : 6|1@1+ (1.0,0.0) [0.0|1.0] ""  DATC,IBOX,TCU
 SG_ F_SUB_TQI : 7|1@1+ (1.0,0.0) [0.0|1.0] ""  _4WD,ECS,EPB,ESC,IBOX,TCU
 SG_ TQI_ACOR : 8|8@1+ (0.390625,0.0) [0.0|99.6094] "%"  _4WD,EPB,ESC,IBOX,TCU
 SG_ N : 16|16@1+ (0.25,0.0) [0.0|16383.75] "rpm"  _4WD,ACU,AFLS,CLU,CUBIS,DATC,ECS,EPB,ESC,FPCM,IBOX,MDPS,SCC,TCU
 SG_ TQI : 32|8@1+ (0.390625,0.0) [0.0|99.6094] "%"  _4WD,ECS,EPB,ESC,IBOX,TCU
 SG_ TQFR : 40|8@1+ (0.390625,0.0) [0.0|99.6094] "%"  _4WD,EPB,ESC,IBOX,TCU
 SG_ VS : 48|8@1+ (1.0,0.0) [0.0|254.0] "km/h"  _4WD,AAF,ACU,AHLS,BCM,CLU,DATC,ECS,EPB,IBOX,LCA,LDWS_LKAS,LVR,MDPS,ODS,SCC,SMK,SPAS,TCU,TPMS
 SG_ RATIO_TQI_BAS_MAX_STND : 56|8@1+ (0.0078,0.0) [0.0|2.0] ""  _4WD,IBOX,TCU

BO_ 1301 CLU14: 8 CLU
 SG_ CF_Clu_ADrUNValueSet : 0|3@1+ (1.0,0.0) [0.0|7.0] ""  BCM
 SG_ CF_Clu_ADrLNValueSet : 3|3@1+ (1.0,0.0) [0.0|7.0] ""  BCM
 SG_ CF_Clu_EscortHLNValueSet : 6|2@1+ (1.0,0.0) [0.0|3.0] ""  BCM
 SG_ CF_Clu_DoorLSNValueSet : 8|3@1+ (1.0,0.0) [0.0|7.0] ""  BCM
 SG_ CF_Clu_PSMNValueSet : 11|3@1+ (1.0,0.0) [0.0|7.0] ""  BCM
 SG_ CF_Clu_TTUnlockNValueSet : 14|2@1+ (1.0,0.0) [0.0|3.0] ""  BCM
 SG_ CF_Clu_PTGMNValueSet : 16|2@1+ (1.0,0.0) [0.0|3.0] ""  BCM
 SG_ CF_Clu_SCMNValueSet : 18|2@1+ (1.0,0.0) [0.0|3.0] ""  BCM
 SG_ CF_Clu_WlightNValueSet : 20|2@1+ (1.0,0.0) [0.0|3.0] ""  BCM
 SG_ CF_Clu_TempUnitNValueSet : 22|2@1+ (1.0,0.0) [0.0|3.0] ""  BCM,DATC
 SG_ CF_Clu_MoodLpNValueSet : 24|3@1+ (1.0,0.0) [0.0|7.0] ""  BCM
 SG_ CF_Clu_TrfChgSet : 27|2@1+ (1.0,0.0) [0.0|3.0] ""  AFLS
 SG_ CF_Clu_OTTurnNValueSet : 29|3@1+ (1.0,0.0) [0.0|7.0] ""  BCM
 SG_ CF_Clu_LcaNValueSet : 32|2@1+ (1.0,0.0) [0.0|3.0] ""  LCA
 SG_ CF_Clu_RctaNValueSet : 34|2@1+ (1.0,0.0) [0.0|3.0] ""  LCA
 SG_ CF_Clu_RcwNValueSet : 36|2@1+ (1.0,0.0) [0.0|3.0] ""  LCA
 SG_ CF_Clu_EscOffNValueSet : 38|3@1+ (1.0,0.0) [0.0|7.0] ""  ESC
 SG_ CF_Clu_SccNaviCrvNValueSet : 41|2@1+ (1.0,0.0) [0.0|3.0] ""  SCC
 SG_ CF_Clu_SccNaviCamNValueSet : 43|2@1+ (1.0,0.0) [0.0|3.0] ""  SCC
 SG_ CF_Clu_SccAebNValueSet : 45|2@1+ (1.0,0.0) [0.0|3.0] ""  SCC
 SG_ CF_Clu_LkasModeNValueSet : 47|2@1+ (1.0,0.0) [0.0|3.0] ""  LDWS_LKAS
 SG_ CF_Clu_FcwNValueSet : 51|2@1+ (1.0,0.0) [0.0|3.0] ""  LDWS_LKAS
 SG_ CF_Clu_PasSpkrLvNValueSet : 53|3@1+ (1.0,0.0) [0.0|7.0] ""  BCM
 SG_ CF_Clu_SccDrvModeNValueSet : 56|3@1+ (1.0,0.0) [0.0|7.0] ""  SCC
 SG_ CF_Clu_HAnBNValueSet : 59|2@1+ (1.0,0.0) [0.0|3.0] ""  BCM
 SG_ CF_Clu_HfreeTrunkTgNValueSet : 61|3@1+ (1.0,0.0) [0.0|7.0] ""  BCM

BO_ 275 TCU13: 8 TCU
 SG_ N_TGT_LUP : 0|8@1+ (10.0,500.0) [500.0|3040.0] "rpm"  EMS,IBOX
 SG_ SLOPE_TCU : 8|6@1+ (0.5,-16.0) [-16.0|15.5] "%"  CLU,CUBIS,EMS,IBOX
 SG_ CF_Tcu_InhCda : 14|1@1+ (1.0,0.0) [0.0|1.0] ""  EMS,IBOX
 SG_ CF_Tcu_IsgInhib : 15|1@1+ (1.0,0.0) [0.0|1.0] ""  EMS,IBOX
 SG_ CF_Tcu_BkeOnReq : 16|2@1+ (1.0,0.0) [0.0|3.0] ""  EMS,IBOX
 SG_ CF_Tcu_NCStat : 18|2@1+ (1.0,0.0) [0.0|3.0] ""  EMS,IBOX
 SG_ CF_Tcu_TarGr : 20|4@1+ (1.0,0.0) [0.0|15.0] ""  _4WD,CLU,DATC,EMS,EPB,ESC,IBOX,SCC
 SG_ CF_Tcu_ShfPatt : 24|4@1+ (1.0,0.0) [0.0|15.0] ""  CLU,CUBIS,EMS,IBOX
 SG_ CF_Tcu_InhVis : 28|1@1+ (1.0,0.0) [0.0|1.0] ""  EMS,IBOX
 SG_ CF_Tcu_PRelReq : 29|1@1+ (1.0,0.0) [0.0|1.0] ""  IBOX,LVR
 SG_ CF_Tcu_ITPhase : 30|1@1+ (1.0,0.0) [0.0|1.0] ""  EMS,IBOX
 SG_ CF_Tcu_ActEcoRdy : 31|1@1+ (1.0,0.0) [0.0|1.0] ""  EMS,IBOX
 SG_ CF_Tcu_TqGrdLim : 32|8@1+ (10.0,0.0) [0.0|2540.0] "Nm/s"  EMS,IBOX
 SG_ CR_Tcu_IsgTgtRPM : 40|8@1+ (20.0,0.0) [0.0|3500.0] "rpm"  EMS,IBOX
 SG_ CF_Tcu_SptRdy : 48|1@1+ (1.0,0.0) [0.0|1.0] ""  CLU,IBOX
 SG_ CF_Tcu_SbwPInfo : 56|1@1+ (1.0,0.0) [0.0|1.0] ""  EMS,IBOX
 SG_ CF_Tcu_Alive3 : 58|2@1+ (1.0,0.0) [0.0|3.0] ""  EMS,IBOX
 SG_ CF_Tcu_ChkSum3 : 60|4@1+ (1.0,0.0) [0.0|15.0] ""  EMS,IBOX

BO_ 274 TCU12: 8 TCU
 SG_ ETL_TCU : 0|8@1+ (2.0,0.0) [0.0|508.0] "Nm"  EMS,IBOX
 SG_ CUR_GR : 8|4@1+ (1.0,0.0) [0.0|15.0] ""  _4WD,EMS,ESC,IBOX,SCC,TPMS
 SG_ CF_Tcu_Alive : 12|2@1+ (1.0,0.0) [0.0|3.0] ""  EMS,ESC,IBOX,SCC
 SG_ CF_Tcu_ChkSum : 14|2@1+ (1.0,0.0) [0.0|3.0] ""  EMS,ESC,IBOX,SCC
 SG_ VS_TCU : 16|8@1+ (1.0,0.0) [0.0|254.0] "km/h"  BCM,CLU,DATC,EMS,IBOX,LCA,LVR,PGS,SMK,SNV
 SG_ FUEL_CUT_TCU : 28|1@1+ (1.0,0.0) [0.0|1.0] ""  EMS,IBOX
 SG_ INH_FUEL_CUT : 29|1@1+ (1.0,0.0) [0.0|1.0] ""  EMS,IBOX
 SG_ IDLE_UP_TCU : 30|1@1+ (1.0,0.0) [0.0|1.0] ""  EMS,IBOX
 SG_ N_INC_TCU : 31|1@1+ (1.0,0.0) [0.0|1.0] ""  EMS,IBOX
 SG_ SPK_RTD_TCU : 32|8@1+ (0.375,-23.625) [-15.0|15.0] ""  EMS,IBOX
 SG_ N_TC_RAW : 40|16@1+ (0.25,0.0) [0.0|16383.5] "rpm"  EMS,IBOX
 SG_ VS_TCU_DECIMAL : 56|8@1+ (0.0078125,0.0) [0.0|0.9921875] "km/h"  CLU,EMS,IBOX,LCA

BO_ 273 TCU11: 8 TCU
 SG_ TQI_TCU_INC : 0|8@1+ (0.390625,0.0) [0.0|99.609375] "%"  EMS,ESC,IBOX
 SG_ G_SEL_DISP : 8|4@1+ (1.0,0.0) [0.0|15.0] ""  _4WD,AFLS,AVM,BCM,CGW,CLU,CUBIS,ECS,EMS,EPB,ESC,IAP,IBOX,LCA,LDWS_LKAS,LVR,MDPS,PGS,SCC,SMK,SNV,SPAS,TPMS
 SG_ F_TCU : 12|2@1+ (1.0,0.0) [0.0|3.0] ""  EMS,ESC,IBOX
 SG_ TCU_TYPE : 14|2@1+ (1.0,0.0) [0.0|3.0] ""  _4WD,EMS,ESC,IBOX
 SG_ TCU_OBD : 16|3@1+ (1.0,0.0) [0.0|7.0] ""  EMS,ESC,IBOX
 SG_ SWI_GS : 19|1@1+ (1.0,0.0) [0.0|1.0] ""  _4WD,EMS,EPB,ESC,IBOX,SCC
 SG_ GEAR_TYPE : 20|4@1+ (1.0,0.0) [0.0|15.0] ""  _4WD,CLU,EMS,ESC,IBOX,SCC
 SG_ TQI_TCU : 24|8@1+ (0.390625,0.0) [0.0|99.609375] "%"  EMS,ESC,IBOX
 SG_ TEMP_AT : 32|8@1+ (1.0,-40.0) [-40.0|214.0] "deg"  AAF,CLU,CUBIS,EMS,ESC,IBOX
 SG_ N_TC : 40|16@1+ (0.25,0.0) [0.0|16383.5] "rpm"  _4WD,EMS,EPB,ESC,IBOX
 SG_ SWI_CC : 56|2@1+ (1.0,0.0) [0.0|3.0] ""  _4WD,CLU,EMS,ESC,IBOX
 SG_ CF_Tcu_Alive1 : 58|2@1+ (1.0,0.0) [0.0|3.0] ""  EMS,IBOX
 SG_ CF_Tcu_ChkSum1 : 60|4@1+ (1.0,0.0) [0.0|15.0] ""  EMS,IBOX

BO_ 16 ACU13: 8 ACU
 SG_ CF_Acu_CshAct : 0|1@1+ (1.0,0.0) [0.0|1.0] ""  CUBIS,IBOX,ODS

BO_ 1040 CGW_USM1: 8 BCM
 SG_ CF_Gway_ATTurnRValue : 0|2@1+ (1.0,0.0) [0.0|3.0] ""  CLU
 SG_ CF_Gway_PTGMRValue : 2|2@1+ (1.0,0.0) [0.0|3.0] ""  CLU
 SG_ CF_Gway_EscortHLRValue : 4|2@1+ (1.0,0.0) [0.0|3.0] ""  CLU
 SG_ CF_Gway_TTUnlockRValue : 6|2@1+ (1.0,0.0) [0.0|3.0] ""  CLU
 SG_ CF_Gway_ADrLRValue : 8|3@1+ (1.0,0.0) [0.0|7.0] ""  CLU
 SG_ CF_Gway_ADrURValue : 11|3@1+ (1.0,0.0) [0.0|7.0] ""  CLU
 SG_ CF_Gway_SCMRValue : 14|2@1+ (1.0,0.0) [0.0|3.0] ""  CLU
 SG_ CF_Gway_WlightRValue : 16|2@1+ (1.0,0.0) [0.0|3.0] ""  CLU
 SG_ CF_Gway_PSMRValue : 18|3@1+ (1.0,0.0) [0.0|7.0] ""  CLU
 SG_ CF_Gway_OTTurnRValue : 21|3@1+ (1.0,0.0) [0.0|7.0] ""  CLU
 SG_ CF_Gway_DrLockSoundRValue : 24|3@1+ (1.0,0.0) [0.0|7.0] ""  CLU
 SG_ CF_Gway_HAnBRValue : 27|3@1+ (1.0,0.0) [0.0|7.0] ""  CLU
 SG_ CF_Gway_MoodLpRValue : 30|2@1+ (1.0,0.0) [0.0|3.0] ""  CLU
 SG_ CF_Gway_HfreeTrunkRValue : 32|3@1+ (1.0,0.0) [0.0|7.0] ""  CLU
 SG_ CF_Gway_AutoLightRValue : 35|3@1+ (1.0,0.0) [0.0|7.0] ""  CLU
 SG_ CF_Gway_RearWiperRValue : 38|2@1+ (1.0,0.0) [0.0|3.0] ""  CLU
 SG_ CF_Gway_PasSpkrLvRValue : 40|3@1+ (1.0,0.0) [0.0|7.0] ""  CLU

BO_ 1292 CLU13: 8 CLU
 SG_ CF_Clu_LowfuelWarn : 0|2@1+ (1.0,0.0) [0.0|3.0] ""  BCM,FPCM,IBOX
 SG_ CF_Clu_RefDetMod : 2|1@1+ (1.0,0.0) [0.0|1.0] ""  IBOX
 SG_ CF_Clu_AvgFCU : 3|2@1+ (1.0,0.0) [0.0|3.0] ""  IBOX
 SG_ CF_Clu_AvsmCur : 5|1@1+ (1.0,0.0) [0.0|1.0] ""  ESC,SCC
 SG_ CF_Clu_AvgFCI : 6|10@1+ (0.1,0.0) [0.0|102.2] ""  IBOX
 SG_ CF_Clu_DrivingModeSwi : 16|2@1+ (1.0,0.0) [0.0|3.0] ""  DATC,ECS,EMS,ESC,IAP,MDPS,TCU
 SG_ CF_Clu_FuelDispLvl : 18|5@1+ (1.0,0.0) [0.0|31.0] ""  CGW,IBOX
 SG_ CF_Clu_FlexSteerSW : 23|1@1+ (1.0,0.0) [0.0|1.0] ""  MDPS
 SG_ CF_Clu_DTE : 24|10@1+ (1.0,0.0) [0.0|1023.0] ""  DATC
 SG_ CF_Clu_TripUnit : 34|2@1+ (1.0,0.0) [0.0|3.0] ""  DATC
 SG_ CF_Clu_SWL_Stat : 36|3@1+ (1.0,0.0) [0.0|7.0] ""  ACU,EMS
 SG_ CF_Clu_ActiveEcoSW : 39|1@1+ (1.0,0.0) [0.0|1.0] ""  DATC,EMS,TCU
 SG_ CF_Clu_EcoDriveInf : 40|3@1+ (1.0,0.0) [0.0|7.0] ""  CUBIS,EMS,IAP,IBOX
 SG_ CF_Clu_IsaMainSW : 43|1@1+ (1.0,0.0) [0.0|1.0] ""  EMS
 SG_ CF_Clu_LdwsLkasSW : 56|1@1+ (1.0,0.0) [0.0|1.0] ""  LDWS_LKAS
 SG_ CF_Clu_AltLStatus : 59|1@1+ (1.0,0.0) [0.0|1.0] ""  BCM,DATC,EMS
 SG_ CF_Clu_AliveCnt2 : 60|4@1+ (1.0,0.0) [0.0|15.0] ""  EMS,LDWS_LKAS

BO_ 1290 SCC13: 8 SCC
 SG_ SCCDrvModeRValue : 0|3@1+ (1,0) [0|7] "" CLU
 SG_ SCC_Equip : 3|1@1+ (1,0) [0|1] "" ESC
 SG_ AebDrvSetStatus : 4|3@1+ (1,0) [0|7] "" CLU,ESC
 SG_ Lead_Veh_Dep_Alert_USM : 13|2@0+ (1,0) [0|3] "" XXX

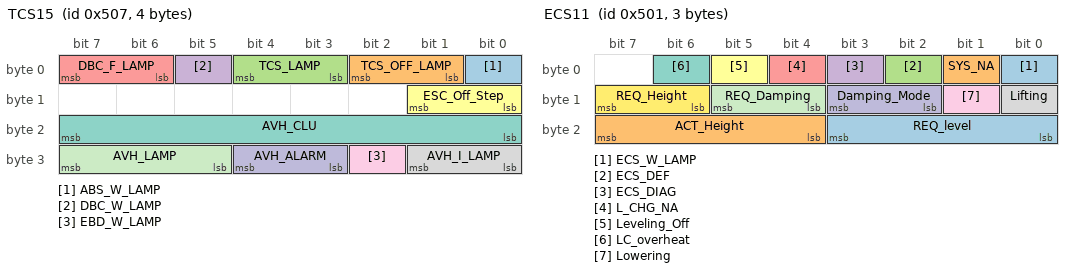
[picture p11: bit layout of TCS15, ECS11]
BO_ 1287 TCS15: 4 ESC
 SG_ ABS_W_LAMP : 0|1@1+ (1.0,0.0) [0.0|1.0] ""  _4WD,CLU,CUBIS,IBOX
 SG_ TCS_OFF_LAMP : 1|2@1+ (1.0,0.0) [0.0|1.0] ""  _4WD,ACU,CLU
 SG_ TCS_LAMP : 3|2@1+ (1.0,0.0) [0.0|3.0] ""  _4WD,ACU,CLU,CUBIS,IBOX,SCC
 SG_ DBC_W_LAMP : 5|1@1+ (1.0,0.0) [0.0|1.0] ""  _4WD,CLU
 SG_ DBC_F_LAMP : 6|2@1+ (1.0,0.0) [0.0|3.0] ""  _4WD,CLU
 SG_ ESC_Off_Step : 8|2@1+ (1.0,0.0) [0.0|3.0] ""  CLU
 SG_ AVH_CLU : 16|8@1+ (1.0,0.0) [0.0|255.0] ""  CLU,EPB
 SG_ AVH_I_LAMP : 24|2@1+ (1.0,0.0) [0.0|3.0] ""  EPB
 SG_ EBD_W_LAMP : 26|1@1+ (1.0,0.0) [0.0|1.0] ""  _4WD,CLU
 SG_ AVH_ALARM : 27|2@1+ (1.0,0.0) [0.0|3.0] ""  CLU
 SG_ AVH_LAMP : 29|3@1+ (1.0,0.0) [0.0|7.0] ""  CLU,EPB,SPAS

BO_ 1282 TCU14: 4 TCU
 SG_ CF_TCU_WarnMsg : 0|3@1+ (1.0,0.0) [0.0|7.0] ""  CLU
 SG_ CF_TCU_WarnImg : 3|1@1+ (1.0,0.0) [0.0|1.0] ""  CLU
 SG_ CF_TCU_WarnSnd : 4|1@1+ (1.0,0.0) [0.0|1.0] ""  CLU
 SG_ CF_Tcu_GSel_BlinkReq : 5|1@1+ (1.0,0.0) [0.0|1.0] ""  CLU,LVR
 SG_ CF_Tcu_StRelStat : 12|1@1+ (1.0,0.0) [0.0|1.0] ""  CLU,EMS,ESC
 SG_ CF_Tcu_DriWarn1 : 13|3@1+ (1.0,0.0) [0.0|7.0] ""  CLU,EMS,ESC
 SG_ CF_Tcu_DriWarn2 : 16|2@1+ (1.0,0.0) [0.0|3.0] ""  CLU,EMS,ESC

BO_ 1281 ECS11: 3 ECS
 SG_ ECS_W_LAMP : 0|1@1+ (1.0,0.0) [0.0|1.0] ""  CLU,CUBIS,IBOX
 SG_ SYS_NA : 1|1@1+ (1.0,0.0) [0.0|1.0] ""  CLU
 SG_ ECS_DEF : 2|1@1+ (1.0,0.0) [0.0|1.0] ""  CLU
 SG_ ECS_DIAG : 3|1@1+ (1.0,0.0) [0.0|1.0] ""  CLU
 SG_ L_CHG_NA : 4|1@1+ (1.0,0.0) [0.0|1.0] ""  CLU
 SG_ Leveling_Off : 5|1@1+ (1.0,0.0) [0.0|1.0] ""  CLU
 SG_ LC_overheat : 6|1@1+ (1.0,0.0) [0.0|1.0] ""  CLU
 SG_ Lifting : 8|1@1+ (1.0,0.0) [0.0|1.0] ""  CLU
 SG_ Lowering : 9|1@1+ (1.0,0.0) [0.0|1.0] ""  CLU
 SG_ Damping_Mode : 10|2@1+ (1.0,0.0) [0.0|3.0] ""  CLU
 SG_ REQ_Damping : 12|2@1+ (1.0,0.0) [0.0|3.0] ""  CLU
 SG_ REQ_Height : 14|2@1+ (1.0,0.0) [0.0|3.0] ""  CLU
 SG_ REQ_level : 16|4@1+ (1.0,0.0) [0.0|15.0] ""  CLU
 SG_ ACT_Height : 20|4@1+ (1.0,0.0) [0.0|15.0] ""  CLU

BO_ 1024 CLU_CFG11: 2 CLU
 SG_ Vehicle_Type : 0|16@1+ (1.0,0.0) [0.0|65536.0] ""  _4WD

BO_ 1280 ACU14: 1 ACU
 SG_ CF_SWL_Ind : 0|2@1+ (1.0,0.0) [0.0|3.0] ""  CLU
 SG_ CF_TTL_Ind : 2|2@1+ (1.0,0.0) [0.0|3.0] ""  CLU
 SG_ CF_SBR_Ind : 4|2@1+ (1.0,0.0) [0.0|3.0] ""  BCM,CLU

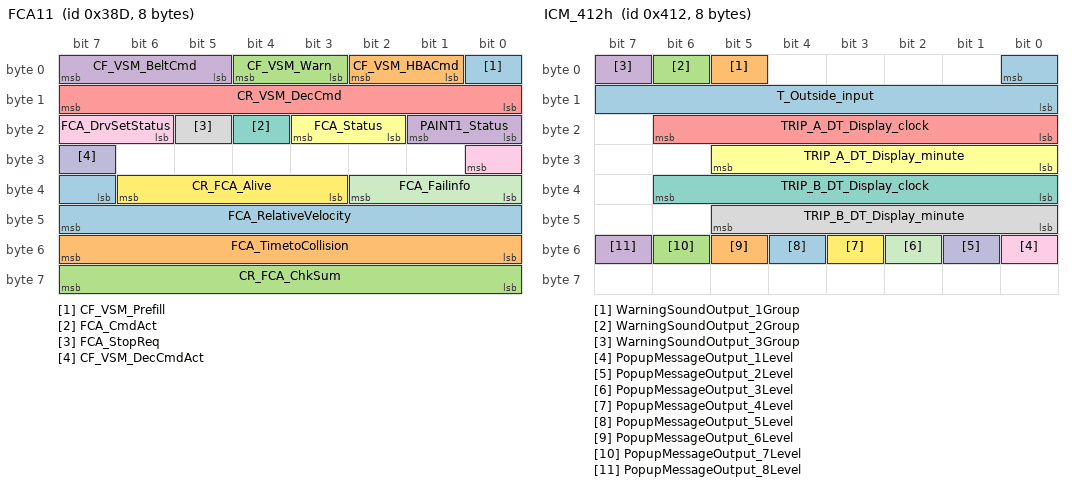
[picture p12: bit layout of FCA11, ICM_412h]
BO_ 909 FCA11: 8 FCA
 SG_ CF_VSM_Prefill : 0|1@1+ (1,0) [0|1] "" ESC
 SG_ CF_VSM_HBACmd : 1|2@1+ (1,0) [0|3] "" ESC
 SG_ CF_VSM_Warn : 3|2@1+ (1,0) [0|3] "" ACU,CLU,ESC
 SG_ CF_VSM_BeltCmd : 5|3@1+ (1,0) [0|7] "" ESC
 SG_ CR_VSM_DecCmd : 8|8@1+ (0.01,0) [0|2.55] "g" ESC
 SG_ FCA_Status : 18|2@1+ (1,0) [0|3] "" ACU,CLU,ESC
 SG_ FCA_CmdAct : 20|1@1+ (1,0) [0|1] "" ESC
 SG_ FCA_StopReq : 21|1@1+ (1,0) [0|1] "" CLU,ESC
 SG_ FCA_DrvSetStatus : 22|3@1+ (1,0) [0|7] "" CLU,ESC
 SG_ CF_VSM_DecCmdAct : 31|1@1+ (1,0) [0|1] "" ESC
 SG_ FCA_Failinfo : 32|3@1+ (1,0) [0|7] "" ACU,CLU,ESC
 SG_ CR_FCA_Alive : 35|4@1+ (1,0) [0|15] "" ESC
 SG_ FCA_RelativeVelocity : 39|9@1+ (0.1,-25.5) [-25.5|25.5] "m/s" iBAU
 SG_ FCA_TimetoCollision : 48|8@1+ (10,0) [0|2540] "ms" iBAU
 SG_ CR_FCA_ChkSum : 56|8@1+ (1,0) [0|255] "" ESC
 SG_ PAINT1_Status : 16|2@1+ (1,0) [0|1] "" XXX

BO_ 1156 HDA11_MFC: 8 XXX
 SG_ Counter : 5|4@0+ (1,0) [0|15] "" XXX
 SG_ NEW_SIGNAL_1 : 1|2@0+ (1,0) [0|255] "" XXX
 SG_ NEW_SIGNAL_2 : 7|2@0+ (1,0) [0|3] "" XXX
 SG_ NEW_SIGNAL_3 : 15|8@0+ (1,0) [0|255] "" XXX
 SG_ NEW_SIGNAL_4 : 16|2@1+ (1,0) [0|3] "" XXX
 SG_ NEW_SIGNAL_5 : 18|14@1+ (1,0) [0|63] "" XXX
 SG_ NEW_SIGNAL_6 : 33|2@0+ (1,0) [0|1] "" XXX
 SG_ NEW_SIGNAL_7 : 34|14@1+ (1,0) [0|16383] "" XXX
 SG_ NEW_SIGNAL_8 : 49|2@0+ (1,0) [0|1] "" XXX
 SG_ NEW_SIGNAL_9 : 50|14@1- (1,-4095) [0|16383] "" XXX

BO_ 1155 FCA12: 8 FCA
 SG_ FCA_USM : 0|3@1+ (1,0) [0|7] "" CGW,CLU,ESC
 SG_ FCA_DrvSetState : 3|3@1+ (1,0) [0|7] "" CGW

BO_ 1186 FRT_RADAR11: 2 FCA
 SG_ CF_FCA_Equip_Front_Radar : 0|3@1+ (1,0) [0|7] "" LDWS_LKAS,LDW_LKA,ESC

BO_ 905 SCC14: 8 SCC
 SG_ ComfortBandUpper : 0|6@1+ (0.02,0) [0|1.26] "m/s^2" ESC
 SG_ ComfortBandLower : 6|6@1+ (0.02,0) [0|1.26] "m/s^2" ESC
 SG_ JerkUpperLimit : 12|7@1+ (0.1,0) [0|12.7] "m/s^3" ESC
 SG_ JerkLowerLimit : 19|7@1+ (0.1,0) [0|12.7] "m/s^3" ESC
 SG_ ACCMode : 32|3@1+ (1,0) [0|7] "" CLU,HUD,LDWS_LKAS,ESC
 SG_ ObjDistStat : 42|2@1+ (1,0) [0|3] "" XXX
 SG_ ObjGap : 56|8@1+ (1,0) [0|255] "" CLU,HUD,ESC

BO_ 1157 LFAHDA_MFC: 4 XXX
 SG_ HDA_USM : 0|2@1+ (1,0) [0|3] "" XXX
 SG_ HDA_Active : 2|1@1+ (1,0) [0|1] "" XXX
 SG_ HDA_Icon_State : 3|2@1+ (1,0) [0|3] "" XXX
 SG_ HDA_Chime : 7|1@1+ (1,0) [0|1] "" XXX
 SG_ HDA_VSetReq : 8|8@1+ (1,0) [0|255] "km/h" XXX
 SG_ LFA_SysWarning : 16|3@1+ (1,0) [0|7] "" XXX
 SG_ NEW_SIGNAL_1 : 20|3@1+ (1,0) [0|7] "" XXX
 SG_ LFA_Icon_State : 24|2@1+ (1,0) [0|3] "" XXX
 SG_ LFA_USM : 27|2@1+ (1,0) [0|3] "" XXX
 SG_ HDA_SysWarning : 29|2@1+ (1,0) [0|3] "" XXX

BO_ 913 BCM_PO_11: 8 Vector__XXX
 SG_ BCM_Door_Dri_Status : 5|1@0+ (1,0) [0|1] "" PT_ESC_ABS
 SG_ BCM_Shift_R_MT_SW_Status : 39|2@0+ (1,0) [0|3] "" PT_ESC_ABS
 SG_ LFA_Pressed : 4|1@0+ (1,0) [0|1] "" XXX

BO_ 1426 LABEL11: 8 XXX
 SG_ CC_React : 34|1@1+ (1,0) [0|1] "" XXX

BO_ 910 WHL_SPD12_FS: 5 iBAU
 SG_ CRC : 0|8@1+ (1,0) [0|0] "" Vector__XXX
 SG_ WHL_SPD12_AliveCounter : 8|4@1+ (1,0) [0|15] "" Vector__XXX
 SG_ WHL_SPD_FL : 12|14@1+ (0.03125,0) [0|511.96875] "km/h" Vector__XXX
 SG_ WHL_SPD_FR : 26|14@1+ (0.03125,0) [0|511.96875] "km/h" Vector__XXX

BO_ 911 WHL_SPD13_FS: 5 iBAU
 SG_ CRC : 0|8@1+ (1,0) [0|0] "" Vector__XXX
 SG_ WHL_SPD13_AliveCounter : 8|4@1+ (1,0) [0|15] "" Vector__XXX
 SG_ WHL_SPD_RL : 12|14@1+ (0.03125,0) [0|511.96875] "km/h" Vector__XXX
 SG_ WHL_SPD_RR : 26|14@1+ (0.03125,0) [0|511.96875] "km/h" Vector__XXX

BO_ 865 ADAS_PRK_11: 8 ADAS_PRK
 SG_ CF_PCA_BrkReq : 24|1@1+ (1,0) [0|0] "" Vector__XXX
 SG_ CF_PCA_DclTrgtVal : 28|4@1+ (0.04,0) [0|0] "g" Vector__XXX
 SG_ PCA_ALIVE_CNT : 40|4@1+ (1,0) [0|0] "" Vector__XXX
 SG_ PCA_CHECK_SUM : 48|8@1+ (1,0) [0|0] "" Vector__XXX

BO_ 882 ELECT_GEAR: 8 XXX
 SG_ Elect_Gear_Shifter : 16|4@1+ (1,0) [0|7] ""  CLU

BO_ 881 E_EMS11: 8 XXX
 SG_ Brake_Pedal_Pos : 0|8@1+ (1,0) [0|127] "" XXX
 SG_ IG_Reactive_Stat : 8|3@1+ (1,0) [0|3] "" XXX
 SG_ Gear_Change : 12|1@0+ (1,0) [0|31] "" XXX
 SG_ Cruise_Limit_Status : 13|1@1+ (1,0) [0|1] "" XXX
 SG_ Cruise_Limit_Target : 23|8@1+ (1,0) [0|15] "" XXX
 SG_ Accel_Pedal_Pos : 31|8@1+ (1,0) [0|254] "" XXX
 SG_ CR_Vcu_AccPedDep_Pos : 56|8@1+ (1,0) [0|254] "" XXX

BO_ 1355 EV_PC6: 8 CGW
 SG_ CF_Vcu_SbwWarnMsg : 16|3@1+ (1,0) [0|7] "" Vector__XXX

BO_ 1430 EV_PC2: 8 CGW
 SG_ CR_Ldc_ActVol_LS_V : 32|8@1+ (0.1,0) [0|0] "V" Vector__XXX

BO_ 1535 EV_PC10: 8 CGW
 SG_ CF_Vcu_EpbRequest : 37|1@1+ (1,0) [0|0] "" Vector__XXX

BO_ 908 RSPA11: 8 RSPA
 SG_ CF_RSPA_State : 0|4@1+ (1,0) [0|15] "" XXX
 SG_ CF_RSPA_Act : 4|2@1+ (1,0) [0|3] "" XXX
 SG_ CF_RSPA_DecCmd : 6|2@1+ (1,0) [0|3] "" XXX
 SG_ CF_RSPA_Trgt_Spd : 8|10@1+ (0.01,0) [0|10.23] "km/h" XXX
 SG_ CF_RSPA_StopReq : 18|1@1+ (1,0) [0|2] "" XXX
 SG_ CR_RSPA_EPB_Req : 22|2@1+ (1,0) [0|3] "" XXX
 SG_ CF_RSPA_ACC_ACT : 50|1@1+ (1,0) [0|2] "" XXX
 SG_ CF_RSPA_AliveCounter : 52|4@1+ (1,0) [0|15] "" XXX
 SG_ CF_RSPA_CRC : 56|8@1+ (1,0) [0|255] "" XXX

BO_ 914 S_MDPS11: 8 XXX
 SG_ CF_Mdps_Stat : 0|4@1+ (1,0) [0|15] "" XXX
 SG_ CR_Mdps_DrvTq : 8|12@1+ (1,0) [0|15] "" XXX
 SG_ CR_Mdps_StrAng : 24|16@1- (1,0) [0|65535] "" XXX
 SG_ CF_Mdps_AliveCnt : 47|8@0+ (1,0) [0|255] "" XXX
 SG_ CF_Mdps_Chksum : 63|8@0+ (1,0) [0|255] "" XXX

BO_ 1191 MFC_4a7: 8 XXX
 SG_ PAINT1 : 0|1@0+ (1,0) [0|1] "" XXX

BO_ 1162 BCA11: 8 BCW
 SG_ CF_BCA_State : 16|3@1+ (1,0) [0|7] "" CLU,iBAU
 SG_ CF_BCA_Warning : 19|2@1+ (1,0) [0|3] "" CLU,iBAU
 SG_ AliveCounter : 21|4@1+ (1,0) [0|15] "" CLU,iBAU
 SG_ RCCA_Brake_Command : 29|1@1+ (1,0) [0|1] "" iBAU
 SG_ Check_Sum : 56|8@1+ (1,0) [0|16] "" iBAU

BO_ 1136 P_STS: 8 CGW
 SG_ HCU1_STS : 6|2@1+ (1,0) [0|3] "" BCW,EPB,FCA,MDPS,SCC,iBAU
 SG_ HCU5_STS : 8|2@1+ (1,0) [0|3] "" EPB,FCA,MDPS,iBAU
 SG_ Counter : 58|4@1+ (1,0) [0|15] "" MDPS
 SG_ Checksum : 62|2@1+ (1,0) [0|3] "" MDPS

BO_ 320 YRS12: 8 ACU
 SG_ CF_Yrs_LongAcStat : 16|4@1+ (1,0) [0|15] "" iBAU
 SG_ CF_IMU_ResetStat : 20|4@1+ (1,0) [0|15] "" iBAU
 SG_ YRS_Temp : 24|8@1+ (1,-68) [-68|187] "" iBAU
 SG_ YRS_TempStat : 32|4@1+ (1,0) [0|15] "" iBAU
 SG_ CF_Yrs_Type : 36|4@1+ (1,0) [0|15] "" iBAU
 SG_ CR_Yrs_MsgCnt2 : 48|4@1+ (1,0) [0|15] "" iBAU
 SG_ CR_Yrs_Crc2 : 56|8@1+ (1,0) [0|255] "" iBAU
 SG_ CR_Yrs_LongAc : 0|16@1+ (0.000127465,-4.17677312) [-4.17677312|4.17651819] "g" CGW,iBAU

BO_ 1173 YRS13: 8 ACU
 SG_ YRS_SeralNo : 16|48@1+ (1,0) [0|281474976710655] "" iBAU

BO_ 870 EMS_366: 8 EMS
 SG_ TQI_1 : 0|8@1+ (0.390625,0) [0|99.6094] "%" MDPS
 SG_ N : 8|16@1+ (0.25,0.0) [0.0|16383.75] "rpm" MDPS
 SG_ TQI_2 : 24|8@1+ (0.390625,0) [0|99.6094] "%" MDPS
 SG_ VS : 40|8@1+ (1,0) [0|255] "km/h" MDPS
 SG_ SWI_IGK : 48|1@0+ (1,0) [0|1] "" XXX

BO_ 854 M_356: 8 XXX
 SG_ PAINT1 : 32|1@0+ (1,0) [0|1] "" XXX
 SG_ PAINT2 : 34|2@0+ (1,0) [0|1] "" XXX
 SG_ PAINT3 : 36|2@0+ (1,0) [0|3] "" XXX
 SG_ PAINT4 : 38|1@0+ (1,0) [0|1] "" XXX

BO_ 1042 ICM_412h: 8 ICM
 SG_ T_Outside_input : 0|9@0+ (0.01,0) [0|5] "V" Vector__XXX
 SG_ WarningSoundOutput_1Group : 5|1@0+ (1,0) [0|1] "" Vector__XXX
 SG_ WarningSoundOutput_2Group : 6|1@0+ (1,0) [0|1] "" Vector__XXX
 SG_ WarningSoundOutput_3Group : 7|1@0+ (1,0) [0|1] "" Vector__XXX
 SG_ TRIP_A_DT_Display_clock : 22|7@0+ (1,0) [0|99] "clock" Vector__XXX
 SG_ TRIP_A_DT_Display_minute : 29|6@0+ (1,0) [0|59] "minute" Vector__XXX
 SG_ TRIP_B_DT_Display_clock : 38|7@0+ (1,0) [0|99] "clock" Vector__XXX
 SG_ TRIP_B_DT_Display_minute : 45|6@0+ (1,0) [0|59] "minute" Vector__XXX
 SG_ PopupMessageOutput_1Level : 48|1@0+ (1,0) [0|1] "" Vector__XXX
 SG_ PopupMessageOutput_2Level : 49|1@0+ (1,0) [0|1] "" Vector__XXX
 SG_ PopupMessageOutput_3Level : 50|1@0+ (1,0) [0|1] "" Vector__XXX
 SG_ PopupMessageOutput_4Level : 51|1@0+ (1,0) [0|1] "" Vector__XXX
 SG_ PopupMessageOutput_5Level : 52|1@0+ (1,0) [0|1] "" Vector__XXX
 SG_ PopupMessageOutput_6Level : 53|1@0+ (1,0) [0|1] "" Vector__XXX
 SG_ PopupMessageOutput_7Level : 54|1@0+ (1,0) [0|1] "" Vector__XXX
 SG_ PopupMessageOutput_8Level : 55|1@0+ (1,0) [0|1] "" Vector__XXX

BO_ 1348 Navi_HU: 8 XXX
 SG_ SpeedLim_Nav_Clu : 7|8@0+ (1,0) [0|255] "" XXX
 SG_ SpeedLim_Nav_General : 29|1@0+ (1,0) [0|1] "" XXX
 SG_ SpeedLim_Nav_Cam : 30|1@0+ (1,0) [0|1] "" XXX

BS_:

BU_: XXX CAMERA FRONT_RADAR ADRV APRK

BS_:

BU_: IAP ODS _4WD BCM HUD DATC MDPS AAF_Tester AEMC SMK _4WD EPB CUBIS MTS TMU EVP CGW TPMS LPI DI_BOX SPAS EMS LCA TCU IBOX FATC AFLS FPCM SCC AHLS AVM ABS SNV OPI PGS SAS AAF Dummy LDWS_LKAS LVR ESC PSB CLU ECS ACU REA

BO_ 1318 HU_GW_E_00: 8 CLU
 SG_ C_ADrLURValueReq : 0|2@1+ (1.0,0.0) [0.0|3.0] ""  BCM
 SG_ C_TwUnRValueReq : 2|2@1+ (1.0,0.0) [0.0|3.0] ""  BCM
 SG_ C_AlarmRValueReq : 4|2@1+ (1.0,0.0) [0.0|3.0] ""  BCM
 SG_ C_IMSRValueReq : 6|2@1+ (1.0,0.0) [0.0|3.0] ""  BCM
 SG_ C_HLEscortRValueReq : 8|2@1+ (1.0,0.0) [0.0|3.0] ""  BCM
 SG_ C_WELRValueReq : 10|2@1+ (1.0,0.0) [0.0|3.0] ""  BCM
 SG_ C_TriTurnLRValueReq : 12|2@1+ (1.0,0.0) [0.0|3.0] ""  BCM
 SG_ C_SNVWarnRValueReq : 14|2@1+ (1.0,0.0) [0.0|3.0] ""  BCM
 SG_ C_LkasWarnRValueReq : 16|2@1+ (1.0,0.0) [0.0|3.0] ""  BCM

BO_ 1317 GW_HU_E_01: 8 BCM
 SG_ C_ADrLRValue : 0|3@1+ (1.0,0.0) [0.0|7.0] ""  CLU
 SG_ C_ADrURValue : 4|3@1+ (1.0,0.0) [0.0|7.0] ""  CLU
 SG_ C_TwUnRValue : 8|2@1+ (1.0,0.0) [0.0|3.0] ""  CLU
 SG_ C_ABuzzerRValue : 10|2@1+ (1.0,0.0) [0.0|3.0] ""  CLU
 SG_ C_ArmWKeyRValue : 12|2@1+ (1.0,0.0) [0.0|3.0] ""  CLU
 SG_ C_PSMRValue : 14|2@1+ (1.0,0.0) [0.0|3.0] ""  CLU
 SG_ C_SCMRValue : 16|2@1+ (1.0,0.0) [0.0|3.0] ""  CLU
 SG_ C_HLEscortRValue : 18|2@1+ (1.0,0.0) [0.0|3.0] ""  CLU
 SG_ C_WELRValue : 20|2@1+ (1.0,0.0) [0.0|3.0] ""  CLU
 SG_ C_TriTurnLRValue : 22|2@1+ (1.0,0.0) [0.0|3.0] ""  CLU

BO_ 1316 GW_HU_E_00: 8 BCM
 SG_ C_ADrLUNValueConf : 0|2@1+ (1.0,0.0) [0.0|3.0] ""  CLU
 SG_ C_TwUnNValueConf : 2|2@1+ (1.0,0.0) [0.0|3.0] ""  CLU
 SG_ C_AlarmNValueConf : 4|2@1+ (1.0,0.0) [0.0|3.0] ""  CLU
 SG_ C_PSMNValueConf : 6|2@1+ (1.0,0.0) [0.0|3.0] ""  CLU
 SG_ C_SCMNValueConf : 8|2@1+ (1.0,0.0) [0.0|3.0] ""  CLU
 SG_ C_HLEscortNValueConf : 10|2@1+ (1.0,0.0) [0.0|3.0] ""  CLU
 SG_ C_WELNValueConf : 12|2@1+ (1.0,0.0) [0.0|3.0] ""  CLU
 SG_ C_TriTurnLNValueConf : 14|2@1+ (1.0,0.0) [0.0|3.0] ""  CLU

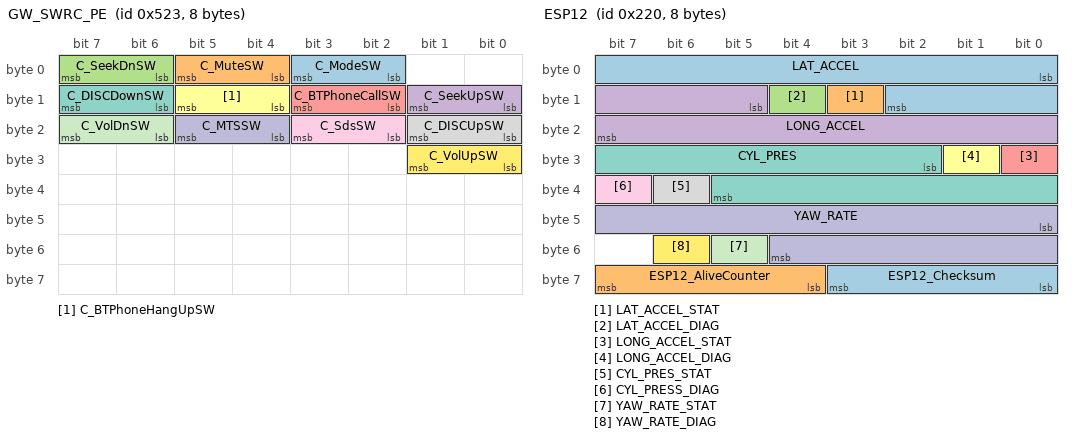
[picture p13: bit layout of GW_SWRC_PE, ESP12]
BO_ 1315 GW_SWRC_PE: 8 BCM
 SG_ C_ModeSW : 2|2@1+ (1.0,0.0) [0.0|3.0] ""  CLU
 SG_ C_MuteSW : 4|2@1+ (1.0,0.0) [0.0|3.0] ""  CLU
 SG_ C_SeekDnSW : 6|2@1+ (1.0,0.0) [0.0|3.0] ""  CLU
 SG_ C_SeekUpSW : 8|2@1+ (1.0,0.0) [0.0|3.0] ""  CLU
 SG_ C_BTPhoneCallSW : 10|2@1+ (1.0,0.0) [0.0|3.0] ""  CLU
 SG_ C_BTPhoneHangUpSW : 12|2@1+ (1.0,0.0) [0.0|3.0] ""  CLU
 SG_ C_DISCDownSW : 14|2@1+ (1.0,0.0) [0.0|3.0] ""  CLU
 SG_ C_DISCUpSW : 16|2@1+ (1.0,0.0) [0.0|3.0] ""  CLU
 SG_ C_SdsSW : 18|2@1+ (1.0,0.0) [0.0|3.0] ""  CLU
 SG_ C_MTSSW : 20|2@1+ (1.0,0.0) [0.0|3.0] ""  CLU
 SG_ C_VolDnSW : 22|2@1+ (1.0,0.0) [0.0|3.0] ""  CLU
 SG_ C_VolUpSW : 24|2@1+ (1.0,0.0) [0.0|3.0] ""  CLU

BO_ 1314 GW_IPM_PE_1: 8 BCM
 SG_ C_AV_Tail : 0|2@1+ (1.0,0.0) [0.0|3.0] ""  CLU
 SG_ C_ParkingBrakeSW : 2|2@1+ (1.0,0.0) [0.0|3.0] ""  CLU
 SG_ C_RKECMD : 4|4@1+ (1.0,0.0) [0.0|15.0] ""  CLU
 SG_ C_BAState : 8|2@1+ (1.0,0.0) [0.0|3.0] ""  CLU
 SG_ C_IGNSW : 12|3@1+ (1.0,0.0) [0.0|7.0] ""  CLU
 SG_ C_CountryCfg : 16|3@1+ (1.0,0.0) [0.0|7.0] ""  CLU
 SG_ C_TailLampActivity : 26|2@1+ (1.0,0.0) [0.0|3.0] ""  CLU
 SG_ RearSW_RSELockOnOff : 28|2@1+ (1.0,0.0) [0.0|3.0] ""  CLU
 SG_ C_SMKTeleCrankingState : 32|2@1+ (1.0,0.0) [0.0|3.0] ""  CLU
 SG_ C_SMKTeleCrankingFailRes : 34|2@1+ (1.0,0.0) [0.0|3.0] ""  CLU

BO_ 1057 SCC12: 8 SCC
 SG_ CF_VSM_Prefill : 0|1@1+ (1,0) [0|1] "" ESC
 SG_ CF_VSM_DecCmdAct : 1|1@1+ (1,0) [0|1] "" ESC
 SG_ CF_VSM_HBACmd : 2|2@1+ (1,0) [0|3] "" ESC
 SG_ CF_VSM_Warn : 4|2@1+ (1,0) [0|3] "" CLU,ESC,IAP
 SG_ CF_VSM_Stat : 6|2@1+ (1,0) [0|3] "" CLU,ESC,PSB
 SG_ CF_VSM_BeltCmd : 8|3@1+ (1,0) [0|7] "" ESC,PSB
 SG_ ACCFailInfo : 11|2@1+ (1,0) [0|3] "" CLU,CUBIS,ESC,IBOX
 SG_ ACCMode : 13|2@1+ (1,0) [0|3] "" CLU,ESC,IBOX,TCU
 SG_ StopReq : 15|1@1+ (1,0) [0|1] "" EPB,ESC
 SG_ CR_VSM_DecCmd : 16|8@1+ (0.01,0) [0|2.55] "g" ESC
 SG_ TakeOverReq : 35|1@1+ (1,0) [0|1] "" CLU,ESC,TCU
 SG_ PreFill : 36|1@1+ (1,0) [0|1] "" ESC,TCU
 SG_ CF_VSM_ConfMode : 48|2@1+ (1,0) [0|3] "" CLU,ESC
 SG_ AEB_Failinfo : 50|2@1+ (1,0) [0|3] "" CLU,ESC
 SG_ AEB_Status : 52|2@1+ (1,0) [0|3] "" CLU,ESC
 SG_ AEB_CmdAct : 54|1@1+ (1,0) [0|1] "" ESC
 SG_ AEB_StopReq : 55|1@1+ (1,0) [0|1] "" CLU,ESC
 SG_ CR_VSM_Alive : 56|4@1+ (1,0) [0|15] "" ESC,PSB
 SG_ CR_VSM_ChkSum : 60|4@1+ (1,0) [0|15] "" ESC,PSB
 SG_ aReqValue : 37|11@1+ (0.01,-10.23) [-10.23|10.24] "m/s^2" Vector__XXX
 SG_ aReqRaw : 24|11@1+ (0.01,-10.23) [-10.23|10.24] "m/s^2" Vector__XXX

BO_ 1313 GW_DDM_PE: 8 BCM
 SG_ C_DRVDoorStatus : 0|2@1+ (1.0,0.0) [0.0|3.0] ""  CLU
 SG_ C_ASTDoorStatus : 2|2@1+ (1.0,0.0) [0.0|3.0] ""  CLU
 SG_ C_RLDoorStatus : 4|2@1+ (1.0,0.0) [0.0|3.0] ""  CLU
 SG_ C_RRDoorStatus : 6|2@1+ (1.0,0.0) [0.0|3.0] ""  CLU
 SG_ C_TrunkStatus : 8|2@1+ (1.0,0.0) [0.0|3.0] ""  CLU
 SG_ C_OSMirrorStatus : 10|2@1+ (1.0,0.0) [0.0|3.0] ""  CLU

BO_ 1056 SCC11: 8 SCC
 SG_ MainMode_ACC : 0|1@1+ (1,0) [0|1] "" CLU,EMS,ESC
 SG_ SCCInfoDisplay : 1|3@1+ (1,0) [0|7] "" CLU,ESC
 SG_ AliveCounterACC : 4|4@1+ (1,0) [0|15] "" CLU,EMS,ESC,TCU
 SG_ VSetDis : 8|8@1+ (1,0) [0|255] "km/h or MPH" CLU,ESC,TCU
 SG_ ObjValid : 16|1@1+ (1,0) [0|1] "" CLU,ESC,TCU
 SG_ DriverAlertDisplay : 17|2@1+ (1,0) [0|3] "" CLU,ESC
 SG_ TauGapSet : 19|3@1+ (1,0) [0|7] "" CLU,ESC,TCU
 SG_ Navi_SCC_Curve_Status : 56|2@1+ (1,0) [0|3] "" CLU
 SG_ Navi_SCC_Curve_Act : 58|2@1+ (1,0) [0|3] "" CLU
 SG_ Navi_SCC_Camera_Act : 60|2@1+ (1,0) [0|3] "" CLU
 SG_ Navi_SCC_Camera_Status : 62|2@1+ (1,0) [0|3] "" CLU
 SG_ ACC_ObjStatus : 22|2@1+ (1,0) [0|3] "" ABS,ESC
 SG_ ACC_ObjLatPos : 24|9@1+ (0.1,-20) [-20|31.1] "m" ABS,ESC
 SG_ ACC_ObjRelSpd : 44|12@1+ (0.1,-170) [-170|239.5] "m/s" ABS,ESC
 SG_ ACC_ObjDist : 33|11@1+ (0.1,0) [0|204.7] "m" ABS,ESC

BO_ 1312 CGW3: 8 BCM
 SG_ CR_Photosensor_LH : 0|8@1+ (78.125,0.0) [0.0|20000.0] ""  DATC,DATC
 SG_ CR_Photosensor_RH : 10|8@1+ (78.125,0.0) [0.0|20000.0] ""  DATC,DATC
 SG_ CF_Hoodsw_memory : 22|2@1+ (1.0,0.0) [0.0|3.0] ""  EMS,EMS
 SG_ C_MirOutTempSns : 24|8@1+ (0.5,-40.5) [-40.0|60.0] "deg"  AAF,CLU,DATC,EMS,SPAS,AAF,DATC,EMS,SPAS

BO_ 544 ESP12: 8 ESC
 SG_ LAT_ACCEL : 0|11@1+ (0.01,-10.23) [-10.23|10.24] "m/s^2"  _4WD,ECS,IBOX,LCA,LDWS_LKAS,MDPS,PSB,SCC,TCU
 SG_ LAT_ACCEL_STAT : 11|1@1+ (1.0,0.0) [0.0|1.0] ""  _4WD,IBOX,LDWS_LKAS,MDPS,PSB,SCC,TCU
 SG_ LAT_ACCEL_DIAG : 12|1@1+ (1.0,0.0) [0.0|1.0] ""  _4WD,IBOX,LDWS_LKAS,MDPS,PSB,SCC,TCU
 SG_ LONG_ACCEL : 13|11@1+ (0.01,-10.23) [-10.23|10.24] "m/s^2"  _4WD,ECS,EMS,EPB,IBOX,LCA,LDWS_LKAS,PSB,SCC,SPAS,TCU
 SG_ LONG_ACCEL_STAT : 24|1@1+ (1.0,0.0) [0.0|1.0] ""  _4WD,EMS,EPB,IBOX,LDWS_LKAS,PSB,SCC,SPAS,TCU
 SG_ LONG_ACCEL_DIAG : 25|1@1+ (1.0,0.0) [0.0|1.0] ""  _4WD,EMS,EPB,IBOX,LDWS_LKAS,PSB,SCC,SPAS,TCU
 SG_ CYL_PRES : 26|12@1+ (0.1,0.0) [0.0|409.5] "Bar"  _4WD,ECS,EMS,EPB,IBOX,LDWS_LKAS,PSB,SCC,TCU
 SG_ CYL_PRES_STAT : 38|1@1+ (1.0,0.0) [0.0|1.0] ""  _4WD,ECS,EMS,EPB,IBOX,LDWS_LKAS,PSB,SCC,TCU
 SG_ CYL_PRESS_DIAG : 39|1@1+ (1.0,0.0) [0.0|1.0] ""  _4WD,ECS,EMS,EPB,IBOX,PSB,SCC,TCU
 SG_ YAW_RATE : 40|13@1+ (0.01,-40.95) [-40.95|40.96] ""  _4WD,AFLS,IBOX,LCA,LDWS_LKAS,MDPS,PSB,SCC,SPAS,TCU
 SG_ YAW_RATE_STAT : 53|1@1+ (1.0,0.0) [0.0|1.0] ""  _4WD,AFLS,IBOX,LCA,LDWS_LKAS,MDPS,PSB,SCC,SPAS,TCU
 SG_ YAW_RATE_DIAG : 54|1@1+ (1.0,0.0) [0.0|1.0] ""  _4WD,AFLS,IBOX,LCA,LDWS_LKAS,MDPS,PSB,SCC,SPAS,TCU
 SG_ ESP12_Checksum : 56|4@1+ (1.0,0.0) [0.0|15.0] ""  _4WD,EMS,LPI,TCU,TMU
 SG_ ESP12_AliveCounter : 60|4@1+ (1.0,0.0) [0.0|15.0] ""  _4WD,EMS,LPI,TCU,TMU

BO_ 1307 CLU16: 8 CLU
 SG_ CF_Clu_TirePressUnitNValueSet : 0|3@1+ (1.0,0.0) [0.0|7.0] ""  TPMS
 SG_ CF_Clu_SlifNValueSet : 3|2@1+ (1.0,0.0) [0.0|3.0] ""  LDWS_LKAS
 SG_ CF_Clu_RearWiperNValueSet : 12|2@1+ (1.0,0.0) [0.0|3.0] ""  BCM

BO_ 790 EMS11: 8 EMS
 SG_ SWI_IGK : 0|1@1+ (1.0,0.0) [0.0|1.0] ""  _4WD,ABS,ACU,AHLS,CUBIS,DI_BOX,ECS,EPB,ESC,IBOX,LDWS_LKAS,MDPS,REA,SAS,SCC,TCU
 SG_ F_N_ENG : 1|1@1+ (1.0,0.0) [0.0|1.0] ""  _4WD,ACU,AFLS,CLU,CUBIS,DATC,ECS,EPB,ESC,IBOX,MDPS,SCC,TCU
 SG_ ACK_TCS : 2|1@1+ (1.0,0.0) [0.0|1.0] ""  ESC,IBOX
 SG_ PUC_STAT : 3|1@1+ (1.0,0.0) [0.0|1.0] ""  _4WD,CLU,DATC,IBOX,TCU
 SG_ TQ_COR_STAT : 4|2@1+ (1.0,0.0) [0.0|3.0] ""  _4WD,ESC,IBOX,TCU
 SG_ RLY_AC : 6|1@1+ (1.0,0.0) [0.0|1.0] ""  DATC,IBOX,TCU
 SG_ F_SUB_TQI : 7|1@1+ (1.0,0.0) [0.0|1.0] ""  _4WD,ECS,EPB,ESC,IBOX,TCU
 SG_ TQI_ACOR : 8|8@1+ (0.390625,0.0) [0.0|99.6094] "%"  _4WD,EPB,ESC,IBOX,TCU
 SG_ N : 16|16@1+ (0.25,0.0) [0.0|16383.75] "rpm"  _4WD,ACU,AFLS,CLU,CUBIS,DATC,ECS,EPB,ESC,FPCM,IBOX,MDPS,SCC,TCU
 SG_ TQI : 32|8@1+ (0.390625,0.0) [0.0|99.6094] "%"  _4WD,ECS,EPB,ESC,IBOX,TCU
 SG_ TQFR : 40|8@1+ (0.390625,0.0) [0.0|99.6094] "%"  _4WD,EPB,ESC,IBOX,TCU
 SG_ VS : 48|8@1+ (1.0,0.0) [0.0|254.0] "km/h"  _4WD,AAF,ACU,AHLS,BCM,CLU,DATC,ECS,EPB,IBOX,LCA,LDWS_LKAS,LVR,MDPS,ODS,SCC,SMK,SPAS,TCU,TPMS
 SG_ RATIO_TQI_BAS_MAX_STND : 56|8@1+ (0.0078,0.0) [0.0|2.0] ""  _4WD,IBOX,TCU

BO_ 1301 CLU14: 8 CLU
 SG_ CF_Clu_ADrUNValueSet : 0|3@1+ (1.0,0.0) [0.0|7.0] ""  BCM
 SG_ CF_Clu_ADrLNValueSet : 3|3@1+ (1.0,0.0) [0.0|7.0] ""  BCM
 SG_ CF_Clu_EscortHLNValueSet : 6|2@1+ (1.0,0.0) [0.0|3.0] ""  BCM
 SG_ CF_Clu_DoorLSNValueSet : 8|3@1+ (1.0,0.0) [0.0|7.0] ""  BCM
 SG_ CF_Clu_PSMNValueSet : 11|3@1+ (1.0,0.0) [0.0|7.0] ""  BCM
 SG_ CF_Clu_TTUnlockNValueSet : 14|2@1+ (1.0,0.0) [0.0|3.0] ""  BCM
 SG_ CF_Clu_PTGMNValueSet : 16|2@1+ (1.0,0.0) [0.0|3.0] ""  BCM
 SG_ CF_Clu_SCMNValueSet : 18|2@1+ (1.0,0.0) [0.0|3.0] ""  BCM
 SG_ CF_Clu_WlightNValueSet : 20|2@1+ (1.0,0.0) [0.0|3.0] ""  BCM
 SG_ CF_Clu_TempUnitNValueSet : 22|2@1+ (1.0,0.0) [0.0|3.0] ""  BCM,DATC
 SG_ CF_Clu_MoodLpNValueSet : 24|3@1+ (1.0,0.0) [0.0|7.0] ""  BCM
 SG_ CF_Clu_TrfChgSet : 27|2@1+ (1.0,0.0) [0.0|3.0] ""  AFLS
 SG_ CF_Clu_OTTurnNValueSet : 29|3@1+ (1.0,0.0) [0.0|7.0] ""  BCM
 SG_ CF_Clu_LcaNValueSet : 32|2@1+ (1.0,0.0) [0.0|3.0] ""  LCA
 SG_ CF_Clu_RctaNValueSet : 34|2@1+ (1.0,0.0) [0.0|3.0] ""  LCA
 SG_ CF_Clu_RcwNValueSet : 36|2@1+ (1.0,0.0) [0.0|3.0] ""  LCA
 SG_ CF_Clu_EscOffNValueSet : 38|3@1+ (1.0,0.0) [0.0|7.0] ""  ESC
 SG_ CF_Clu_SccNaviCrvNValueSet : 41|2@1+ (1.0,0.0) [0.0|3.0] ""  SCC
 SG_ CF_Clu_SccNaviCamNValueSet : 43|2@1+ (1.0,0.0) [0.0|3.0] ""  SCC
 SG_ CF_Clu_SccAebNValueSet : 45|2@1+ (1.0,0.0) [0.0|3.0] ""  SCC
 SG_ CF_Clu_LkasModeNValueSet : 47|2@1+ (1.0,0.0) [0.0|3.0] ""  LDWS_LKAS
 SG_ CF_Clu_FcwNValueSet : 51|2@1+ (1.0,0.0) [0.0|3.0] ""  LDWS_LKAS
 SG_ CF_Clu_PasSpkrLvNValueSet : 53|3@1+ (1.0,0.0) [0.0|7.0] ""  BCM
 SG_ CF_Clu_SccDrvModeNValueSet : 56|3@1+ (1.0,0.0) [0.0|7.0] ""  SCC
 SG_ CF_Clu_HAnBNValueSet : 59|2@1+ (1.0,0.0) [0.0|3.0] ""  BCM
 SG_ CF_Clu_HfreeTrunkTgNValueSet : 61|3@1+ (1.0,0.0) [0.0|7.0] ""  BCM

BO_ 275 TCU13: 8 TCU
 SG_ N_TGT_LUP : 0|8@1+ (10.0,500.0) [500.0|3040.0] "rpm"  EMS,IBOX
 SG_ SLOPE_TCU : 8|6@1+ (0.5,-16.0) [-16.0|15.5] "%"  CLU,CUBIS,EMS,IBOX
 SG_ CF_Tcu_InhCda : 14|1@1+ (1.0,0.0) [0.0|1.0] ""  EMS,IBOX
 SG_ CF_Tcu_IsgInhib : 15|1@1+ (1.0,0.0) [0.0|1.0] ""  EMS,IBOX
 SG_ CF_Tcu_BkeOnReq : 16|2@1+ (1.0,0.0) [0.0|3.0] ""  EMS,IBOX
 SG_ CF_Tcu_NCStat : 18|2@1+ (1.0,0.0) [0.0|3.0] ""  EMS,IBOX
 SG_ CF_Tcu_TarGr : 20|4@1+ (1.0,0.0) [0.0|15.0] ""  _4WD,CLU,DATC,EMS,EPB,ESC,IBOX,SCC
 SG_ CF_Tcu_ShfPatt : 24|4@1+ (1.0,0.0) [0.0|15.0] ""  CLU,CUBIS,EMS,IBOX
 SG_ CF_Tcu_InhVis : 28|1@1+ (1.0,0.0) [0.0|1.0] ""  EMS,IBOX
 SG_ CF_Tcu_PRelReq : 29|1@1+ (1.0,0.0) [0.0|1.0] ""  IBOX,LVR
 SG_ CF_Tcu_ITPhase : 30|1@1+ (1.0,0.0) [0.0|1.0] ""  EMS,IBOX
 SG_ CF_Tcu_ActEcoRdy : 31|1@1+ (1.0,0.0) [0.0|1.0] ""  EMS,IBOX
 SG_ CF_Tcu_TqGrdLim : 32|8@1+ (10.0,0.0) [0.0|2540.0] "Nm/s"  EMS,IBOX
 SG_ CR_Tcu_IsgTgtRPM : 40|8@1+ (20.0,0.0) [0.0|3500.0] "rpm"  EMS,IBOX
 SG_ CF_Tcu_SptRdy : 48|1@1+ (1.0,0.0) [0.0|1.0] ""  CLU,IBOX
 SG_ CF_Tcu_SbwPInfo : 56|1@1+ (1.0,0.0) [0.0|1.0] ""  EMS,IBOX
 SG_ CF_Tcu_Alive3 : 58|2@1+ (1.0,0.0) [0.0|3.0] ""  EMS,IBOX
 SG_ CF_Tcu_ChkSum3 : 60|4@1+ (1.0,0.0) [0.0|15.0] ""  EMS,IBOX

BO_ 274 TCU12: 8 TCU
 SG_ ETL_TCU : 0|8@1+ (2.0,0.0) [0.0|508.0] "Nm"  EMS,IBOX
 SG_ CUR_GR : 8|4@1+ (1.0,0.0) [0.0|15.0] ""  _4WD,EMS,ESC,IBOX,SCC,TPMS
 SG_ CF_Tcu_Alive : 12|2@1+ (1.0,0.0) [0.0|3.0] ""  EMS,ESC,IBOX,SCC
 SG_ CF_Tcu_ChkSum : 14|2@1+ (1.0,0.0) [0.0|3.0] ""  EMS,ESC,IBOX,SCC
 SG_ VS_TCU : 16|8@1+ (1.0,0.0) [0.0|254.0] "km/h"  BCM,CLU,DATC,EMS,IBOX,LCA,LVR,PGS,SMK,SNV
 SG_ FUEL_CUT_TCU : 28|1@1+ (1.0,0.0) [0.0|1.0] ""  EMS,IBOX
 SG_ INH_FUEL_CUT : 29|1@1+ (1.0,0.0) [0.0|1.0] ""  EMS,IBOX
 SG_ IDLE_UP_TCU : 30|1@1+ (1.0,0.0) [0.0|1.0] ""  EMS,IBOX
 SG_ N_INC_TCU : 31|1@1+ (1.0,0.0) [0.0|1.0] ""  EMS,IBOX
 SG_ SPK_RTD_TCU : 32|8@1+ (0.375,-23.625) [-15.0|15.0] ""  EMS,IBOX
 SG_ N_TC_RAW : 40|16@1+ (0.25,0.0) [0.0|16383.5] "rpm"  EMS,IBOX
 SG_ VS_TCU_DECIMAL : 56|8@1+ (0.0078125,0.0) [0.0|0.9921875] "km/h"  CLU,EMS,IBOX,LCA

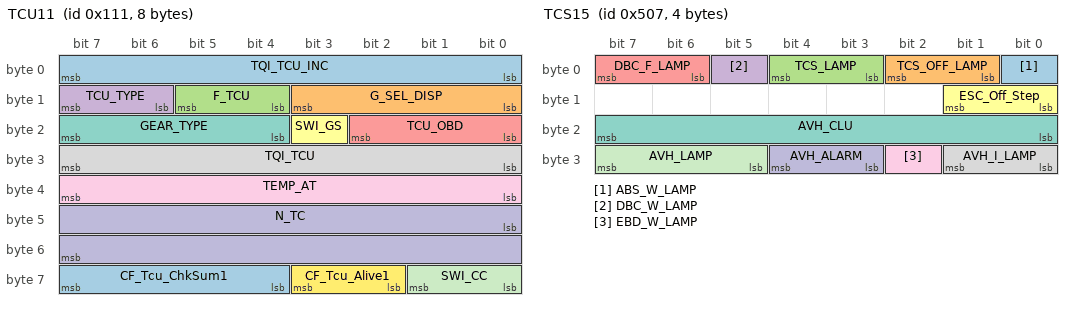
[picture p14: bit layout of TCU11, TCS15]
BO_ 273 TCU11: 8 TCU
 SG_ TQI_TCU_INC : 0|8@1+ (0.390625,0.0) [0.0|99.609375] "%"  EMS,ESC,IBOX
 SG_ G_SEL_DISP : 8|4@1+ (1.0,0.0) [0.0|15.0] ""  _4WD,AFLS,AVM,BCM,CGW,CLU,CUBIS,ECS,EMS,EPB,ESC,IAP,IBOX,LCA,LDWS_LKAS,LVR,MDPS,PGS,SCC,SMK,SNV,SPAS,TPMS
 SG_ F_TCU : 12|2@1+ (1.0,0.0) [0.0|3.0] ""  EMS,ESC,IBOX
 SG_ TCU_TYPE : 14|2@1+ (1.0,0.0) [0.0|3.0] ""  _4WD,EMS,ESC,IBOX
 SG_ TCU_OBD : 16|3@1+ (1.0,0.0) [0.0|7.0] ""  EMS,ESC,IBOX
 SG_ SWI_GS : 19|1@1+ (1.0,0.0) [0.0|1.0] ""  _4WD,EMS,EPB,ESC,IBOX,SCC
 SG_ GEAR_TYPE : 20|4@1+ (1.0,0.0) [0.0|15.0] ""  _4WD,CLU,EMS,ESC,IBOX,SCC
 SG_ TQI_TCU : 24|8@1+ (0.390625,0.0) [0.0|99.609375] "%"  EMS,ESC,IBOX
 SG_ TEMP_AT : 32|8@1+ (1.0,-40.0) [-40.0|214.0] "deg"  AAF,CLU,CUBIS,EMS,ESC,IBOX
 SG_ N_TC : 40|16@1+ (0.25,0.0) [0.0|16383.5] "rpm"  _4WD,EMS,EPB,ESC,IBOX
 SG_ SWI_CC : 56|2@1+ (1.0,0.0) [0.0|3.0] ""  _4WD,CLU,EMS,ESC,IBOX
 SG_ CF_Tcu_Alive1 : 58|2@1+ (1.0,0.0) [0.0|3.0] ""  EMS,IBOX
 SG_ CF_Tcu_ChkSum1 : 60|4@1+ (1.0,0.0) [0.0|15.0] ""  EMS,IBOX

BO_ 16 ACU13: 8 ACU
 SG_ CF_Acu_CshAct : 0|1@1+ (1.0,0.0) [0.0|1.0] ""  CUBIS,IBOX,ODS

BO_ 1040 CGW_USM1: 8 BCM
 SG_ CF_Gway_ATTurnRValue : 0|2@1+ (1.0,0.0) [0.0|3.0] ""  CLU
 SG_ CF_Gway_PTGMRValue : 2|2@1+ (1.0,0.0) [0.0|3.0] ""  CLU
 SG_ CF_Gway_EscortHLRValue : 4|2@1+ (1.0,0.0) [0.0|3.0] ""  CLU
 SG_ CF_Gway_TTUnlockRValue : 6|2@1+ (1.0,0.0) [0.0|3.0] ""  CLU
 SG_ CF_Gway_ADrLRValue : 8|3@1+ (1.0,0.0) [0.0|7.0] ""  CLU
 SG_ CF_Gway_ADrURValue : 11|3@1+ (1.0,0.0) [0.0|7.0] ""  CLU
 SG_ CF_Gway_SCMRValue : 14|2@1+ (1.0,0.0) [0.0|3.0] ""  CLU
 SG_ CF_Gway_WlightRValue : 16|2@1+ (1.0,0.0) [0.0|3.0] ""  CLU
 SG_ CF_Gway_PSMRValue : 18|3@1+ (1.0,0.0) [0.0|7.0] ""  CLU
 SG_ CF_Gway_OTTurnRValue : 21|3@1+ (1.0,0.0) [0.0|7.0] ""  CLU
 SG_ CF_Gway_DrLockSoundRValue : 24|3@1+ (1.0,0.0) [0.0|7.0] ""  CLU
 SG_ CF_Gway_HAnBRValue : 27|3@1+ (1.0,0.0) [0.0|7.0] ""  CLU
 SG_ CF_Gway_MoodLpRValue : 30|2@1+ (1.0,0.0) [0.0|3.0] ""  CLU
 SG_ CF_Gway_HfreeTrunkRValue : 32|3@1+ (1.0,0.0) [0.0|7.0] ""  CLU
 SG_ CF_Gway_AutoLightRValue : 35|3@1+ (1.0,0.0) [0.0|7.0] ""  CLU
 SG_ CF_Gway_RearWiperRValue : 38|2@1+ (1.0,0.0) [0.0|3.0] ""  CLU
 SG_ CF_Gway_PasSpkrLvRValue : 40|3@1+ (1.0,0.0) [0.0|7.0] ""  CLU

BO_ 1292 CLU13: 8 CLU
 SG_ CF_Clu_LowfuelWarn : 0|2@1+ (1.0,0.0) [0.0|3.0] ""  BCM,FPCM,IBOX
 SG_ CF_Clu_RefDetMod : 2|1@1+ (1.0,0.0) [0.0|1.0] ""  IBOX
 SG_ CF_Clu_AvgFCU : 3|2@1+ (1.0,0.0) [0.0|3.0] ""  IBOX
 SG_ CF_Clu_AvsmCur : 5|1@1+ (1.0,0.0) [0.0|1.0] ""  ESC,SCC
 SG_ CF_Clu_AvgFCI : 6|10@1+ (0.1,0.0) [0.0|102.2] ""  IBOX
 SG_ CF_Clu_DrivingModeSwi : 16|2@1+ (1.0,0.0) [0.0|3.0] ""  DATC,ECS,EMS,ESC,IAP,MDPS,TCU
 SG_ CF_Clu_FuelDispLvl : 18|5@1+ (1.0,0.0) [0.0|31.0] ""  CGW,IBOX
 SG_ CF_Clu_FlexSteerSW : 23|1@1+ (1.0,0.0) [0.0|1.0] ""  MDPS
 SG_ CF_Clu_DTE : 24|10@1+ (1.0,0.0) [0.0|1023.0] ""  DATC
 SG_ CF_Clu_TripUnit : 34|2@1+ (1.0,0.0) [0.0|3.0] ""  DATC
 SG_ CF_Clu_SWL_Stat : 36|3@1+ (1.0,0.0) [0.0|7.0] ""  ACU,EMS
 SG_ CF_Clu_ActiveEcoSW : 39|1@1+ (1.0,0.0) [0.0|1.0] ""  DATC,EMS,TCU
 SG_ CF_Clu_EcoDriveInf : 40|3@1+ (1.0,0.0) [0.0|7.0] ""  CUBIS,EMS,IAP,IBOX
 SG_ CF_Clu_IsaMainSW : 43|1@1+ (1.0,0.0) [0.0|1.0] ""  EMS
 SG_ CF_Clu_LdwsLkasSW : 56|1@1+ (1.0,0.0) [0.0|1.0] ""  LDWS_LKAS
 SG_ CF_Clu_AltLStatus : 59|1@1+ (1.0,0.0) [0.0|1.0] ""  BCM,DATC,EMS
 SG_ CF_Clu_AliveCnt2 : 60|4@1+ (1.0,0.0) [0.0|15.0] ""  EMS,LDWS_LKAS

BO_ 1290 SCC13: 8 SCC
 SG_ SCCDrvModeRValue : 0|3@1+ (1,0) [0|7] "" CLU
 SG_ SCC_Equip : 3|1@1+ (1,0) [0|1] "" ESC
 SG_ AebDrvSetStatus : 4|3@1+ (1,0) [0|7] "" CLU,ESC
 SG_ Lead_Veh_Dep_Alert_USM : 13|2@0+ (1,0) [0|3] "" XXX

BO_ 1287 TCS15: 4 ESC
 SG_ ABS_W_LAMP : 0|1@1+ (1.0,0.0) [0.0|1.0] ""  _4WD,CLU,CUBIS,IBOX
 SG_ TCS_OFF_LAMP : 1|2@1+ (1.0,0.0) [0.0|1.0] ""  _4WD,ACU,CLU
 SG_ TCS_LAMP : 3|2@1+ (1.0,0.0) [0.0|3.0] ""  _4WD,ACU,CLU,CUBIS,IBOX,SCC
 SG_ DBC_W_LAMP : 5|1@1+ (1.0,0.0) [0.0|1.0] ""  _4WD,CLU
 SG_ DBC_F_LAMP : 6|2@1+ (1.0,0.0) [0.0|3.0] ""  _4WD,CLU
 SG_ ESC_Off_Step : 8|2@1+ (1.0,0.0) [0.0|3.0] ""  CLU
 SG_ AVH_CLU : 16|8@1+ (1.0,0.0) [0.0|255.0] ""  CLU,EPB
 SG_ AVH_I_LAMP : 24|2@1+ (1.0,0.0) [0.0|3.0] ""  EPB
 SG_ EBD_W_LAMP : 26|1@1+ (1.0,0.0) [0.0|1.0] ""  _4WD,CLU
 SG_ AVH_ALARM : 27|2@1+ (1.0,0.0) [0.0|3.0] ""  CLU
 SG_ AVH_LAMP : 29|3@1+ (1.0,0.0) [0.0|7.0] ""  CLU,EPB,SPAS

BO_ 1282 TCU14: 4 TCU
 SG_ CF_TCU_WarnMsg : 0|3@1+ (1.0,0.0) [0.0|7.0] ""  CLU
 SG_ CF_TCU_WarnImg : 3|1@1+ (1.0,0.0) [0.0|1.0] ""  CLU
 SG_ CF_TCU_WarnSnd : 4|1@1+ (1.0,0.0) [0.0|1.0] ""  CLU
 SG_ CF_Tcu_GSel_BlinkReq : 5|1@1+ (1.0,0.0) [0.0|1.0] ""  CLU,LVR
 SG_ CF_Tcu_StRelStat : 12|1@1+ (1.0,0.0) [0.0|1.0] ""  CLU,EMS,ESC
 SG_ CF_Tcu_DriWarn1 : 13|3@1+ (1.0,0.0) [0.0|7.0] ""  CLU,EMS,ESC
 SG_ CF_Tcu_DriWarn2 : 16|2@1+ (1.0,0.0) [0.0|3.0] ""  CLU,EMS,ESC

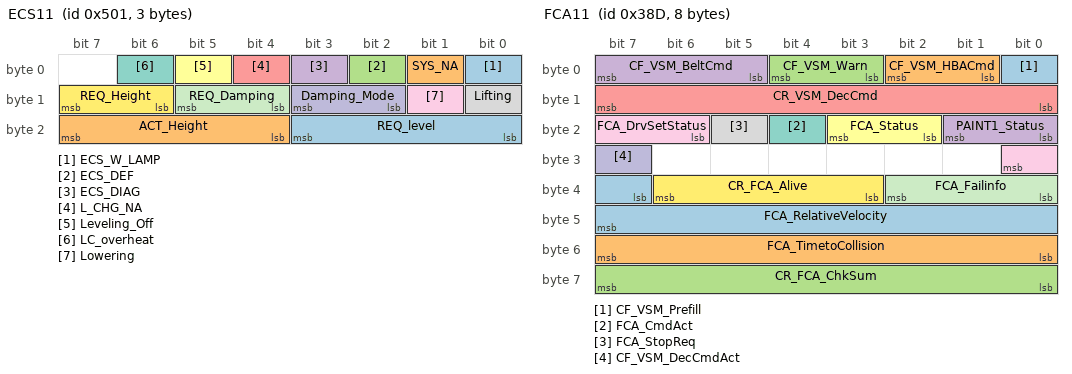
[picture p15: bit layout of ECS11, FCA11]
BO_ 1281 ECS11: 3 ECS
 SG_ ECS_W_LAMP : 0|1@1+ (1.0,0.0) [0.0|1.0] ""  CLU,CUBIS,IBOX
 SG_ SYS_NA : 1|1@1+ (1.0,0.0) [0.0|1.0] ""  CLU
 SG_ ECS_DEF : 2|1@1+ (1.0,0.0) [0.0|1.0] ""  CLU
 SG_ ECS_DIAG : 3|1@1+ (1.0,0.0) [0.0|1.0] ""  CLU
 SG_ L_CHG_NA : 4|1@1+ (1.0,0.0) [0.0|1.0] ""  CLU
 SG_ Leveling_Off : 5|1@1+ (1.0,0.0) [0.0|1.0] ""  CLU
 SG_ LC_overheat : 6|1@1+ (1.0,0.0) [0.0|1.0] ""  CLU
 SG_ Lifting : 8|1@1+ (1.0,0.0) [0.0|1.0] ""  CLU
 SG_ Lowering : 9|1@1+ (1.0,0.0) [0.0|1.0] ""  CLU
 SG_ Damping_Mode : 10|2@1+ (1.0,0.0) [0.0|3.0] ""  CLU
 SG_ REQ_Damping : 12|2@1+ (1.0,0.0) [0.0|3.0] ""  CLU
 SG_ REQ_Height : 14|2@1+ (1.0,0.0) [0.0|3.0] ""  CLU
 SG_ REQ_level : 16|4@1+ (1.0,0.0) [0.0|15.0] ""  CLU
 SG_ ACT_Height : 20|4@1+ (1.0,0.0) [0.0|15.0] ""  CLU

BO_ 1024 CLU_CFG11: 2 CLU
 SG_ Vehicle_Type : 0|16@1+ (1.0,0.0) [0.0|65536.0] ""  _4WD

BO_ 1280 ACU14: 1 ACU
 SG_ CF_SWL_Ind : 0|2@1+ (1.0,0.0) [0.0|3.0] ""  CLU
 SG_ CF_TTL_Ind : 2|2@1+ (1.0,0.0) [0.0|3.0] ""  CLU
 SG_ CF_SBR_Ind : 4|2@1+ (1.0,0.0) [0.0|3.0] ""  BCM,CLU

BO_ 909 FCA11: 8 FCA
 SG_ CF_VSM_Prefill : 0|1@1+ (1,0) [0|1] "" ESC
 SG_ CF_VSM_HBACmd : 1|2@1+ (1,0) [0|3] "" ESC
 SG_ CF_VSM_Warn : 3|2@1+ (1,0) [0|3] "" ACU,CLU,ESC
 SG_ CF_VSM_BeltCmd : 5|3@1+ (1,0) [0|7] "" ESC
 SG_ CR_VSM_DecCmd : 8|8@1+ (0.01,0) [0|2.55] "g" ESC
 SG_ FCA_Status : 18|2@1+ (1,0) [0|3] "" ACU,CLU,ESC
 SG_ FCA_CmdAct : 20|1@1+ (1,0) [0|1] "" ESC
 SG_ FCA_StopReq : 21|1@1+ (1,0) [0|1] "" CLU,ESC
 SG_ FCA_DrvSetStatus : 22|3@1+ (1,0) [0|7] "" CLU,ESC
 SG_ CF_VSM_DecCmdAct : 31|1@1+ (1,0) [0|1] "" ESC
 SG_ FCA_Failinfo : 32|3@1+ (1,0) [0|7] "" ACU,CLU,ESC
 SG_ CR_FCA_Alive : 35|4@1+ (1,0) [0|15] "" ESC
 SG_ FCA_RelativeVelocity : 39|9@1+ (0.1,-25.5) [-25.5|25.5] "m/s" iBAU
 SG_ FCA_TimetoCollision : 48|8@1+ (10,0) [0|2540] "ms" iBAU
 SG_ CR_FCA_ChkSum : 56|8@1+ (1,0) [0|255] "" ESC
 SG_ PAINT1_Status : 16|2@1+ (1,0) [0|1] "" XXX

BO_ 1156 HDA11_MFC: 8 XXX
 SG_ Counter : 5|4@0+ (1,0) [0|15] "" XXX
 SG_ NEW_SIGNAL_1 : 1|2@0+ (1,0) [0|255] "" XXX
 SG_ NEW_SIGNAL_2 : 7|2@0+ (1,0) [0|3] "" XXX
 SG_ NEW_SIGNAL_3 : 15|8@0+ (1,0) [0|255] "" XXX
 SG_ NEW_SIGNAL_4 : 16|2@1+ (1,0) [0|3] "" XXX
 SG_ NEW_SIGNAL_5 : 18|14@1+ (1,0) [0|63] "" XXX
 SG_ NEW_SIGNAL_6 : 33|2@0+ (1,0) [0|1] "" XXX
 SG_ NEW_SIGNAL_7 : 34|14@1+ (1,0) [0|16383] "" XXX
 SG_ NEW_SIGNAL_8 : 49|2@0+ (1,0) [0|1] "" XXX
 SG_ NEW_SIGNAL_9 : 50|14@1- (1,-4095) [0|16383] "" XXX

BO_ 1155 FCA12: 8 FCA
 SG_ FCA_USM : 0|3@1+ (1,0) [0|7] "" CGW,CLU,ESC
 SG_ FCA_DrvSetState : 3|3@1+ (1,0) [0|7] "" CGW

BO_ 1186 FRT_RADAR11: 2 FCA
 SG_ CF_FCA_Equip_Front_Radar : 0|3@1+ (1,0) [0|7] "" LDWS_LKAS,LDW_LKA,ESC

BO_ 905 SCC14: 8 SCC
 SG_ ComfortBandUpper : 0|6@1+ (0.02,0) [0|1.26] "m/s^2" ESC
 SG_ ComfortBandLower : 6|6@1+ (0.02,0) [0|1.26] "m/s^2" ESC
 SG_ JerkUpperLimit : 12|7@1+ (0.1,0) [0|12.7] "m/s^3" ESC
 SG_ JerkLowerLimit : 19|7@1+ (0.1,0) [0|12.7] "m/s^3" ESC
 SG_ ACCMode : 32|3@1+ (1,0) [0|7] "" CLU,HUD,LDWS_LKAS,ESC
 SG_ ObjDistStat : 42|2@1+ (1,0) [0|3] "" XXX
 SG_ ObjGap : 56|8@1+ (1,0) [0|255] "" CLU,HUD,ESC

BO_ 1157 LFAHDA_MFC: 4 XXX
 SG_ HDA_USM : 0|2@1+ (1,0) [0|3] "" XXX
 SG_ HDA_Active : 2|1@1+ (1,0) [0|1] "" XXX
 SG_ HDA_Icon_State : 3|2@1+ (1,0) [0|3] "" XXX
 SG_ HDA_Chime : 7|1@1+ (1,0) [0|1] "" XXX
 SG_ HDA_VSetReq : 8|8@1+ (1,0) [0|255] "km/h" XXX
 SG_ LFA_SysWarning : 16|3@1+ (1,0) [0|7] "" XXX
 SG_ NEW_SIGNAL_1 : 20|3@1+ (1,0) [0|7] "" XXX
 SG_ LFA_Icon_State : 24|2@1+ (1,0) [0|3] "" XXX
 SG_ LFA_USM : 27|2@1+ (1,0) [0|3] "" XXX
 SG_ HDA_SysWarning : 29|2@1+ (1,0) [0|3] "" XXX

BO_ 913 BCM_PO_11: 8 Vector__XXX
 SG_ BCM_Door_Dri_Status : 5|1@0+ (1,0) [0|1] "" PT_ESC_ABS
 SG_ BCM_Shift_R_MT_SW_Status : 39|2@0+ (1,0) [0|3] "" PT_ESC_ABS
 SG_ LFA_Pressed : 4|1@0+ (1,0) [0|1] "" XXX

BO_ 1426 LABEL11: 8 XXX
 SG_ CC_React : 34|1@1+ (1,0) [0|1] "" XXX

BO_ 910 WHL_SPD12_FS: 5 iBAU
 SG_ CRC : 0|8@1+ (1,0) [0|0] "" Vector__XXX
 SG_ WHL_SPD12_AliveCounter : 8|4@1+ (1,0) [0|15] "" Vector__XXX
 SG_ WHL_SPD_FL : 12|14@1+ (0.03125,0) [0|511.96875] "km/h" Vector__XXX
 SG_ WHL_SPD_FR : 26|14@1+ (0.03125,0) [0|511.96875] "km/h" Vector__XXX

BO_ 911 WHL_SPD13_FS: 5 iBAU
 SG_ CRC : 0|8@1+ (1,0) [0|0] "" Vector__XXX
 SG_ WHL_SPD13_AliveCounter : 8|4@1+ (1,0) [0|15] "" Vector__XXX
 SG_ WHL_SPD_RL : 12|14@1+ (0.03125,0) [0|511.96875] "km/h" Vector__XXX
 SG_ WHL_SPD_RR : 26|14@1+ (0.03125,0) [0|511.96875] "km/h" Vector__XXX

BO_ 865 ADAS_PRK_11: 8 ADAS_PRK
 SG_ CF_PCA_BrkReq : 24|1@1+ (1,0) [0|0] "" Vector__XXX
 SG_ CF_PCA_DclTrgtVal : 28|4@1+ (0.04,0) [0|0] "g" Vector__XXX
 SG_ PCA_ALIVE_CNT : 40|4@1+ (1,0) [0|0] "" Vector__XXX
 SG_ PCA_CHECK_SUM : 48|8@1+ (1,0) [0|0] "" Vector__XXX

BO_ 882 ELECT_GEAR: 8 XXX
 SG_ Elect_Gear_Shifter : 16|4@1+ (1,0) [0|7] ""  CLU

BO_ 881 E_EMS11: 8 XXX
 SG_ Brake_Pedal_Pos : 0|8@1+ (1,0) [0|127] "" XXX
 SG_ IG_Reactive_Stat : 8|3@1+ (1,0) [0|3] "" XXX
 SG_ Gear_Change : 12|1@0+ (1,0) [0|31] "" XXX
 SG_ Cruise_Limit_Status : 13|1@1+ (1,0) [0|1] "" XXX
 SG_ Cruise_Limit_Target : 23|8@1+ (1,0) [0|15] "" XXX
 SG_ Accel_Pedal_Pos : 31|8@1+ (1,0) [0|254] "" XXX
 SG_ CR_Vcu_AccPedDep_Pos : 56|8@1+ (1,0) [0|254] "" XXX

BO_ 1355 EV_PC6: 8 CGW
 SG_ CF_Vcu_SbwWarnMsg : 16|3@1+ (1,0) [0|7] "" Vector__XXX

BO_ 1430 EV_PC2: 8 CGW
 SG_ CR_Ldc_ActVol_LS_V : 32|8@1+ (0.1,0) [0|0] "V" Vector__XXX

BO_ 1535 EV_PC10: 8 CGW
 SG_ CF_Vcu_EpbRequest : 37|1@1+ (1,0) [0|0] "" Vector__XXX

BO_ 908 RSPA11: 8 RSPA
 SG_ CF_RSPA_State : 0|4@1+ (1,0) [0|15] "" XXX
 SG_ CF_RSPA_Act : 4|2@1+ (1,0) [0|3] "" XXX
 SG_ CF_RSPA_DecCmd : 6|2@1+ (1,0) [0|3] "" XXX
 SG_ CF_RSPA_Trgt_Spd : 8|10@1+ (0.01,0) [0|10.23] "km/h" XXX
 SG_ CF_RSPA_StopReq : 18|1@1+ (1,0) [0|2] "" XXX
 SG_ CR_RSPA_EPB_Req : 22|2@1+ (1,0) [0|3] "" XXX
 SG_ CF_RSPA_ACC_ACT : 50|1@1+ (1,0) [0|2] "" XXX
 SG_ CF_RSPA_AliveCounter : 52|4@1+ (1,0) [0|15] "" XXX
 SG_ CF_RSPA_CRC : 56|8@1+ (1,0) [0|255] "" XXX

BO_ 914 S_MDPS11: 8 XXX
 SG_ CF_Mdps_Stat : 0|4@1+ (1,0) [0|15] "" XXX
 SG_ CR_Mdps_DrvTq : 8|12@1+ (1,0) [0|15] "" XXX
 SG_ CR_Mdps_StrAng : 24|16@1- (1,0) [0|65535] "" XXX
 SG_ CF_Mdps_AliveCnt : 47|8@0+ (1,0) [0|255] "" XXX
 SG_ CF_Mdps_Chksum : 63|8@0+ (1,0) [0|255] "" XXX

BO_ 1191 MFC_4a7: 8 XXX
 SG_ PAINT1 : 0|1@0+ (1,0) [0|1] "" XXX

BO_ 1162 BCA11: 8 BCW
 SG_ CF_BCA_State : 16|3@1+ (1,0) [0|7] "" CLU,iBAU
 SG_ CF_BCA_Warning : 19|2@1+ (1,0) [0|3] "" CLU,iBAU
 SG_ AliveCounter : 21|4@1+ (1,0) [0|15] "" CLU,iBAU
 SG_ RCCA_Brake_Command : 29|1@1+ (1,0) [0|1] "" iBAU
 SG_ Check_Sum : 56|8@1+ (1,0) [0|16] "" iBAU

BO_ 1136 P_STS: 8 CGW
 SG_ HCU1_STS : 6|2@1+ (1,0) [0|3] "" BCW,EPB,FCA,MDPS,SCC,iBAU
 SG_ HCU5_STS : 8|2@1+ (1,0) [0|3] "" EPB,FCA,MDPS,iBAU
 SG_ Counter : 58|4@1+ (1,0) [0|15] "" MDPS
 SG_ Checksum : 62|2@1+ (1,0) [0|3] "" MDPS

BO_ 320 YRS12: 8 ACU
 SG_ CF_Yrs_LongAcStat : 16|4@1+ (1,0) [0|15] "" iBAU
 SG_ CF_IMU_ResetStat : 20|4@1+ (1,0) [0|15] "" iBAU
 SG_ YRS_Temp : 24|8@1+ (1,-68) [-68|187] "" iBAU
 SG_ YRS_TempStat : 32|4@1+ (1,0) [0|15] "" iBAU
 SG_ CF_Yrs_Type : 36|4@1+ (1,0) [0|15] "" iBAU
 SG_ CR_Yrs_MsgCnt2 : 48|4@1+ (1,0) [0|15] "" iBAU
 SG_ CR_Yrs_Crc2 : 56|8@1+ (1,0) [0|255] "" iBAU
 SG_ CR_Yrs_LongAc : 0|16@1+ (0.000127465,-4.17677312) [-4.17677312|4.17651819] "g" CGW,iBAU

BO_ 1173 YRS13: 8 ACU
 SG_ YRS_SeralNo : 16|48@1+ (1,0) [0|281474976710655] "" iBAU

BO_ 870 EMS_366: 8 EMS
 SG_ TQI_1 : 0|8@1+ (0.390625,0) [0|99.6094] "%" MDPS
 SG_ N : 8|16@1+ (0.25,0.0) [0.0|16383.75] "rpm" MDPS
 SG_ TQI_2 : 24|8@1+ (0.390625,0) [0|99.6094] "%" MDPS
 SG_ VS : 40|8@1+ (1,0) [0|255] "km/h" MDPS
 SG_ SWI_IGK : 48|1@0+ (1,0) [0|1] "" XXX

BO_ 854 M_356: 8 XXX
 SG_ PAINT1 : 32|1@0+ (1,0) [0|1] "" XXX
 SG_ PAINT2 : 34|2@0+ (1,0) [0|1] "" XXX
 SG_ PAINT3 : 36|2@0+ (1,0) [0|3] "" XXX
 SG_ PAINT4 : 38|1@0+ (1,0) [0|1] "" XXX

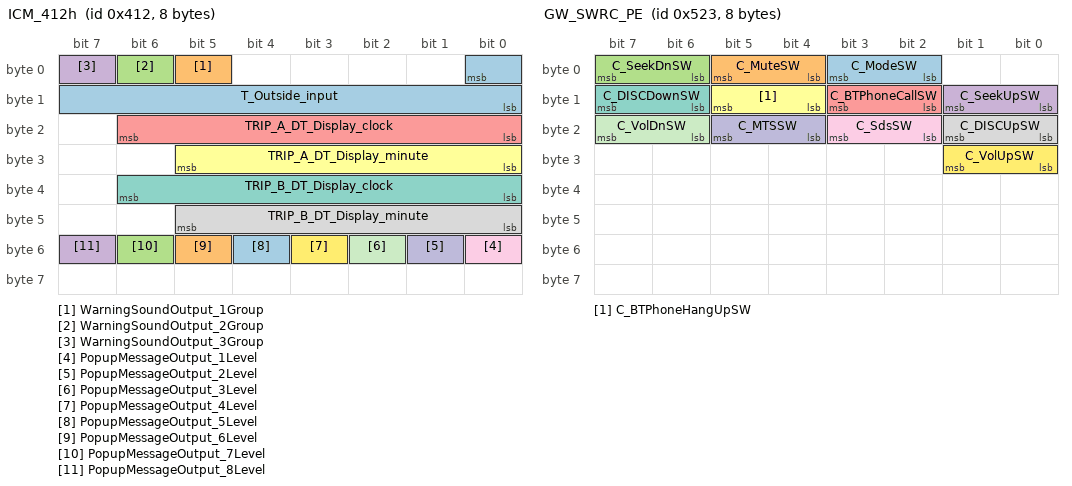
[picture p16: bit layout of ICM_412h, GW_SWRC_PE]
BO_ 1042 ICM_412h: 8 ICM
 SG_ T_Outside_input : 0|9@0+ (0.01,0) [0|5] "V" Vector__XXX
 SG_ WarningSoundOutput_1Group : 5|1@0+ (1,0) [0|1] "" Vector__XXX
 SG_ WarningSoundOutput_2Group : 6|1@0+ (1,0) [0|1] "" Vector__XXX
 SG_ WarningSoundOutput_3Group : 7|1@0+ (1,0) [0|1] "" Vector__XXX
 SG_ TRIP_A_DT_Display_clock : 22|7@0+ (1,0) [0|99] "clock" Vector__XXX
 SG_ TRIP_A_DT_Display_minute : 29|6@0+ (1,0) [0|59] "minute" Vector__XXX
 SG_ TRIP_B_DT_Display_clock : 38|7@0+ (1,0) [0|99] "clock" Vector__XXX
 SG_ TRIP_B_DT_Display_minute : 45|6@0+ (1,0) [0|59] "minute" Vector__XXX
 SG_ PopupMessageOutput_1Level : 48|1@0+ (1,0) [0|1] "" Vector__XXX
 SG_ PopupMessageOutput_2Level : 49|1@0+ (1,0) [0|1] "" Vector__XXX
 SG_ PopupMessageOutput_3Level : 50|1@0+ (1,0) [0|1] "" Vector__XXX
 SG_ PopupMessageOutput_4Level : 51|1@0+ (1,0) [0|1] "" Vector__XXX
 SG_ PopupMessageOutput_5Level : 52|1@0+ (1,0) [0|1] "" Vector__XXX
 SG_ PopupMessageOutput_6Level : 53|1@0+ (1,0) [0|1] "" Vector__XXX
 SG_ PopupMessageOutput_7Level : 54|1@0+ (1,0) [0|1] "" Vector__XXX
 SG_ PopupMessageOutput_8Level : 55|1@0+ (1,0) [0|1] "" Vector__XXX

BO_ 1348 Navi_HU: 8 XXX
 SG_ SpeedLim_Nav_Clu : 7|8@0+ (1,0) [0|255] "" XXX
 SG_ SpeedLim_Nav_General : 29|1@0+ (1,0) [0|1] "" XXX
 SG_ SpeedLim_Nav_Cam : 30|1@0+ (1,0) [0|1] "" XXX

BS_:

BU_: XXX CAMERA FRONT_RADAR ADRV APRK

BS_:

BU_: IAP ODS _4WD BCM HUD DATC MDPS AAF_Tester AEMC SMK _4WD EPB CUBIS MTS TMU EVP CGW TPMS LPI DI_BOX SPAS EMS LCA TCU IBOX FATC AFLS FPCM SCC AHLS AVM ABS SNV OPI PGS SAS AAF Dummy LDWS_LKAS LVR ESC PSB CLU ECS ACU REA

BO_ 1318 HU_GW_E_00: 8 CLU
 SG_ C_ADrLURValueReq : 0|2@1+ (1.0,0.0) [0.0|3.0] ""  BCM
 SG_ C_TwUnRValueReq : 2|2@1+ (1.0,0.0) [0.0|3.0] ""  BCM
 SG_ C_AlarmRValueReq : 4|2@1+ (1.0,0.0) [0.0|3.0] ""  BCM
 SG_ C_IMSRValueReq : 6|2@1+ (1.0,0.0) [0.0|3.0] ""  BCM
 SG_ C_HLEscortRValueReq : 8|2@1+ (1.0,0.0) [0.0|3.0] ""  BCM
 SG_ C_WELRValueReq : 10|2@1+ (1.0,0.0) [0.0|3.0] ""  BCM
 SG_ C_TriTurnLRValueReq : 12|2@1+ (1.0,0.0) [0.0|3.0] ""  BCM
 SG_ C_SNVWarnRValueReq : 14|2@1+ (1.0,0.0) [0.0|3.0] ""  BCM
 SG_ C_LkasWarnRValueReq : 16|2@1+ (1.0,0.0) [0.0|3.0] ""  BCM

BO_ 1317 GW_HU_E_01: 8 BCM
 SG_ C_ADrLRValue : 0|3@1+ (1.0,0.0) [0.0|7.0] ""  CLU
 SG_ C_ADrURValue : 4|3@1+ (1.0,0.0) [0.0|7.0] ""  CLU
 SG_ C_TwUnRValue : 8|2@1+ (1.0,0.0) [0.0|3.0] ""  CLU
 SG_ C_ABuzzerRValue : 10|2@1+ (1.0,0.0) [0.0|3.0] ""  CLU
 SG_ C_ArmWKeyRValue : 12|2@1+ (1.0,0.0) [0.0|3.0] ""  CLU
 SG_ C_PSMRValue : 14|2@1+ (1.0,0.0) [0.0|3.0] ""  CLU
 SG_ C_SCMRValue : 16|2@1+ (1.0,0.0) [0.0|3.0] ""  CLU
 SG_ C_HLEscortRValue : 18|2@1+ (1.0,0.0) [0.0|3.0] ""  CLU
 SG_ C_WELRValue : 20|2@1+ (1.0,0.0) [0.0|3.0] ""  CLU
 SG_ C_TriTurnLRValue : 22|2@1+ (1.0,0.0) [0.0|3.0] ""  CLU

BO_ 1316 GW_HU_E_00: 8 BCM
 SG_ C_ADrLUNValueConf : 0|2@1+ (1.0,0.0) [0.0|3.0] ""  CLU
 SG_ C_TwUnNValueConf : 2|2@1+ (1.0,0.0) [0.0|3.0] ""  CLU
 SG_ C_AlarmNValueConf : 4|2@1+ (1.0,0.0) [0.0|3.0] ""  CLU
 SG_ C_PSMNValueConf : 6|2@1+ (1.0,0.0) [0.0|3.0] ""  CLU
 SG_ C_SCMNValueConf : 8|2@1+ (1.0,0.0) [0.0|3.0] ""  CLU
 SG_ C_HLEscortNValueConf : 10|2@1+ (1.0,0.0) [0.0|3.0] ""  CLU
 SG_ C_WELNValueConf : 12|2@1+ (1.0,0.0) [0.0|3.0] ""  CLU
 SG_ C_TriTurnLNValueConf : 14|2@1+ (1.0,0.0) [0.0|3.0] ""  CLU

BO_ 1315 GW_SWRC_PE: 8 BCM
 SG_ C_ModeSW : 2|2@1+ (1.0,0.0) [0.0|3.0] ""  CLU
 SG_ C_MuteSW : 4|2@1+ (1.0,0.0) [0.0|3.0] ""  CLU
 SG_ C_SeekDnSW : 6|2@1+ (1.0,0.0) [0.0|3.0] ""  CLU
 SG_ C_SeekUpSW : 8|2@1+ (1.0,0.0) [0.0|3.0] ""  CLU
 SG_ C_BTPhoneCallSW : 10|2@1+ (1.0,0.0) [0.0|3.0] ""  CLU
 SG_ C_BTPhoneHangUpSW : 12|2@1+ (1.0,0.0) [0.0|3.0] ""  CLU
 SG_ C_DISCDownSW : 14|2@1+ (1.0,0.0) [0.0|3.0] ""  CLU
 SG_ C_DISCUpSW : 16|2@1+ (1.0,0.0) [0.0|3.0] ""  CLU
 SG_ C_SdsSW : 18|2@1+ (1.0,0.0) [0.0|3.0] ""  CLU
 SG_ C_MTSSW : 20|2@1+ (1.0,0.0) [0.0|3.0] ""  CLU
 SG_ C_VolDnSW : 22|2@1+ (1.0,0.0) [0.0|3.0] ""  CLU
 SG_ C_VolUpSW : 24|2@1+ (1.0,0.0) [0.0|3.0] ""  CLU

BO_ 1314 GW_IPM_PE_1: 8 BCM
 SG_ C_AV_Tail : 0|2@1+ (1.0,0.0) [0.0|3.0] ""  CLU
 SG_ C_ParkingBrakeSW : 2|2@1+ (1.0,0.0) [0.0|3.0] ""  CLU
 SG_ C_RKECMD : 4|4@1+ (1.0,0.0) [0.0|15.0] ""  CLU
 SG_ C_BAState : 8|2@1+ (1.0,0.0) [0.0|3.0] ""  CLU
 SG_ C_IGNSW : 12|3@1+ (1.0,0.0) [0.0|7.0] ""  CLU
 SG_ C_CountryCfg : 16|3@1+ (1.0,0.0) [0.0|7.0] ""  CLU
 SG_ C_TailLampActivity : 26|2@1+ (1.0,0.0) [0.0|3.0] ""  CLU
 SG_ RearSW_RSELockOnOff : 28|2@1+ (1.0,0.0) [0.0|3.0] ""  CLU
 SG_ C_SMKTeleCrankingState : 32|2@1+ (1.0,0.0) [0.0|3.0] ""  CLU
 SG_ C_SMKTeleCrankingFailRes : 34|2@1+ (1.0,0.0) [0.0|3.0] ""  CLU

BO_ 1057 SCC12: 8 SCC
 SG_ CF_VSM_Prefill : 0|1@1+ (1,0) [0|1] "" ESC
 SG_ CF_VSM_DecCmdAct : 1|1@1+ (1,0) [0|1] "" ESC
 SG_ CF_VSM_HBACmd : 2|2@1+ (1,0) [0|3] "" ESC
 SG_ CF_VSM_Warn : 4|2@1+ (1,0) [0|3] "" CLU,ESC,IAP
 SG_ CF_VSM_Stat : 6|2@1+ (1,0) [0|3] "" CLU,ESC,PSB
 SG_ CF_VSM_BeltCmd : 8|3@1+ (1,0) [0|7] "" ESC,PSB
 SG_ ACCFailInfo : 11|2@1+ (1,0) [0|3] "" CLU,CUBIS,ESC,IBOX
 SG_ ACCMode : 13|2@1+ (1,0) [0|3] "" CLU,ESC,IBOX,TCU
 SG_ StopReq : 15|1@1+ (1,0) [0|1] "" EPB,ESC
 SG_ CR_VSM_DecCmd : 16|8@1+ (0.01,0) [0|2.55] "g" ESC
 SG_ TakeOverReq : 35|1@1+ (1,0) [0|1] "" CLU,ESC,TCU
 SG_ PreFill : 36|1@1+ (1,0) [0|1] "" ESC,TCU
 SG_ CF_VSM_ConfMode : 48|2@1+ (1,0) [0|3] "" CLU,ESC
 SG_ AEB_Failinfo : 50|2@1+ (1,0) [0|3] "" CLU,ESC
 SG_ AEB_Status : 52|2@1+ (1,0) [0|3] "" CLU,ESC
 SG_ AEB_CmdAct : 54|1@1+ (1,0) [0|1] "" ESC
 SG_ AEB_StopReq : 55|1@1+ (1,0) [0|1] "" CLU,ESC
 SG_ CR_VSM_Alive : 56|4@1+ (1,0) [0|15] "" ESC,PSB
 SG_ CR_VSM_ChkSum : 60|4@1+ (1,0) [0|15] "" ESC,PSB
 SG_ aReqValue : 37|11@1+ (0.01,-10.23) [-10.23|10.24] "m/s^2" Vector__XXX
 SG_ aReqRaw : 24|11@1+ (0.01,-10.23) [-10.23|10.24] "m/s^2" Vector__XXX

BO_ 1313 GW_DDM_PE: 8 BCM
 SG_ C_DRVDoorStatus : 0|2@1+ (1.0,0.0) [0.0|3.0] ""  CLU
 SG_ C_ASTDoorStatus : 2|2@1+ (1.0,0.0) [0.0|3.0] ""  CLU
 SG_ C_RLDoorStatus : 4|2@1+ (1.0,0.0) [0.0|3.0] ""  CLU
 SG_ C_RRDoorStatus : 6|2@1+ (1.0,0.0) [0.0|3.0] ""  CLU
 SG_ C_TrunkStatus : 8|2@1+ (1.0,0.0) [0.0|3.0] ""  CLU
 SG_ C_OSMirrorStatus : 10|2@1+ (1.0,0.0) [0.0|3.0] ""  CLU

BO_ 1056 SCC11: 8 SCC
 SG_ MainMode_ACC : 0|1@1+ (1,0) [0|1] "" CLU,EMS,ESC
 SG_ SCCInfoDisplay : 1|3@1+ (1,0) [0|7] "" CLU,ESC
 SG_ AliveCounterACC : 4|4@1+ (1,0) [0|15] "" CLU,EMS,ESC,TCU
 SG_ VSetDis : 8|8@1+ (1,0) [0|255] "km/h or MPH" CLU,ESC,TCU
 SG_ ObjValid : 16|1@1+ (1,0) [0|1] "" CLU,ESC,TCU
 SG_ DriverAlertDisplay : 17|2@1+ (1,0) [0|3] "" CLU,ESC
 SG_ TauGapSet : 19|3@1+ (1,0) [0|7] "" CLU,ESC,TCU
 SG_ Navi_SCC_Curve_Status : 56|2@1+ (1,0) [0|3] "" CLU
 SG_ Navi_SCC_Curve_Act : 58|2@1+ (1,0) [0|3] "" CLU
 SG_ Navi_SCC_Camera_Act : 60|2@1+ (1,0) [0|3] "" CLU
 SG_ Navi_SCC_Camera_Status : 62|2@1+ (1,0) [0|3] "" CLU
 SG_ ACC_ObjStatus : 22|2@1+ (1,0) [0|3] "" ABS,ESC
 SG_ ACC_ObjLatPos : 24|9@1+ (0.1,-20) [-20|31.1] "m" ABS,ESC
 SG_ ACC_ObjRelSpd : 44|12@1+ (0.1,-170) [-170|239.5] "m/s" ABS,ESC
 SG_ ACC_ObjDist : 33|11@1+ (0.1,0) [0|204.7] "m" ABS,ESC

BO_ 1312 CGW3: 8 BCM
 SG_ CR_Photosensor_LH : 0|8@1+ (78.125,0.0) [0.0|20000.0] ""  DATC,DATC
 SG_ CR_Photosensor_RH : 10|8@1+ (78.125,0.0) [0.0|20000.0] ""  DATC,DATC
 SG_ CF_Hoodsw_memory : 22|2@1+ (1.0,0.0) [0.0|3.0] ""  EMS,EMS
 SG_ C_MirOutTempSns : 24|8@1+ (0.5,-40.5) [-40.0|60.0] "deg"  AAF,CLU,DATC,EMS,SPAS,AAF,DATC,EMS,SPAS

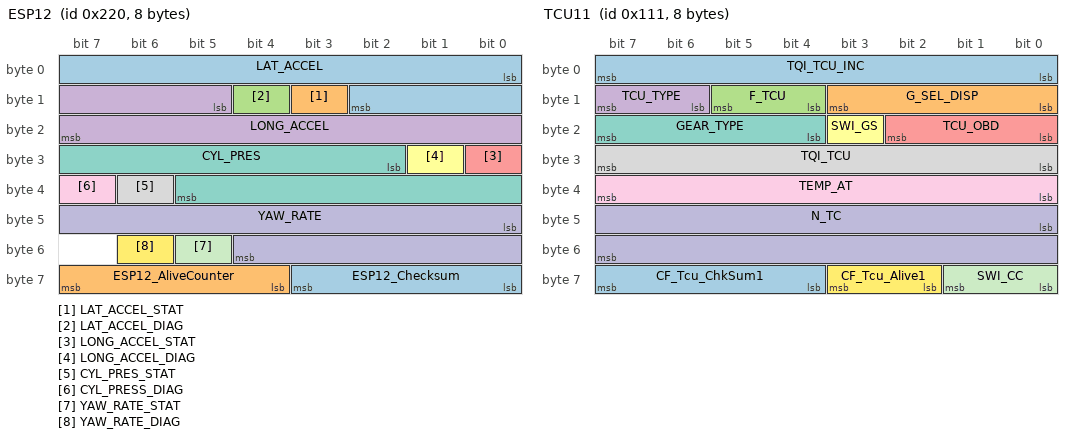
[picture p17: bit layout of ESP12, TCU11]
BO_ 544 ESP12: 8 ESC
 SG_ LAT_ACCEL : 0|11@1+ (0.01,-10.23) [-10.23|10.24] "m/s^2"  _4WD,ECS,IBOX,LCA,LDWS_LKAS,MDPS,PSB,SCC,TCU
 SG_ LAT_ACCEL_STAT : 11|1@1+ (1.0,0.0) [0.0|1.0] ""  _4WD,IBOX,LDWS_LKAS,MDPS,PSB,SCC,TCU
 SG_ LAT_ACCEL_DIAG : 12|1@1+ (1.0,0.0) [0.0|1.0] ""  _4WD,IBOX,LDWS_LKAS,MDPS,PSB,SCC,TCU
 SG_ LONG_ACCEL : 13|11@1+ (0.01,-10.23) [-10.23|10.24] "m/s^2"  _4WD,ECS,EMS,EPB,IBOX,LCA,LDWS_LKAS,PSB,SCC,SPAS,TCU
 SG_ LONG_ACCEL_STAT : 24|1@1+ (1.0,0.0) [0.0|1.0] ""  _4WD,EMS,EPB,IBOX,LDWS_LKAS,PSB,SCC,SPAS,TCU
 SG_ LONG_ACCEL_DIAG : 25|1@1+ (1.0,0.0) [0.0|1.0] ""  _4WD,EMS,EPB,IBOX,LDWS_LKAS,PSB,SCC,SPAS,TCU
 SG_ CYL_PRES : 26|12@1+ (0.1,0.0) [0.0|409.5] "Bar"  _4WD,ECS,EMS,EPB,IBOX,LDWS_LKAS,PSB,SCC,TCU
 SG_ CYL_PRES_STAT : 38|1@1+ (1.0,0.0) [0.0|1.0] ""  _4WD,ECS,EMS,EPB,IBOX,LDWS_LKAS,PSB,SCC,TCU
 SG_ CYL_PRESS_DIAG : 39|1@1+ (1.0,0.0) [0.0|1.0] ""  _4WD,ECS,EMS,EPB,IBOX,PSB,SCC,TCU
 SG_ YAW_RATE : 40|13@1+ (0.01,-40.95) [-40.95|40.96] ""  _4WD,AFLS,IBOX,LCA,LDWS_LKAS,MDPS,PSB,SCC,SPAS,TCU
 SG_ YAW_RATE_STAT : 53|1@1+ (1.0,0.0) [0.0|1.0] ""  _4WD,AFLS,IBOX,LCA,LDWS_LKAS,MDPS,PSB,SCC,SPAS,TCU
 SG_ YAW_RATE_DIAG : 54|1@1+ (1.0,0.0) [0.0|1.0] ""  _4WD,AFLS,IBOX,LCA,LDWS_LKAS,MDPS,PSB,SCC,SPAS,TCU
 SG_ ESP12_Checksum : 56|4@1+ (1.0,0.0) [0.0|15.0] ""  _4WD,EMS,LPI,TCU,TMU
 SG_ ESP12_AliveCounter : 60|4@1+ (1.0,0.0) [0.0|15.0] ""  _4WD,EMS,LPI,TCU,TMU

BO_ 1307 CLU16: 8 CLU
 SG_ CF_Clu_TirePressUnitNValueSet : 0|3@1+ (1.0,0.0) [0.0|7.0] ""  TPMS
 SG_ CF_Clu_SlifNValueSet : 3|2@1+ (1.0,0.0) [0.0|3.0] ""  LDWS_LKAS
 SG_ CF_Clu_RearWiperNValueSet : 12|2@1+ (1.0,0.0) [0.0|3.0] ""  BCM

BO_ 790 EMS11: 8 EMS
 SG_ SWI_IGK : 0|1@1+ (1.0,0.0) [0.0|1.0] ""  _4WD,ABS,ACU,AHLS,CUBIS,DI_BOX,ECS,EPB,ESC,IBOX,LDWS_LKAS,MDPS,REA,SAS,SCC,TCU
 SG_ F_N_ENG : 1|1@1+ (1.0,0.0) [0.0|1.0] ""  _4WD,ACU,AFLS,CLU,CUBIS,DATC,ECS,EPB,ESC,IBOX,MDPS,SCC,TCU
 SG_ ACK_TCS : 2|1@1+ (1.0,0.0) [0.0|1.0] ""  ESC,IBOX
 SG_ PUC_STAT : 3|1@1+ (1.0,0.0) [0.0|1.0] ""  _4WD,CLU,DATC,IBOX,TCU
 SG_ TQ_COR_STAT : 4|2@1+ (1.0,0.0) [0.0|3.0] ""  _4WD,ESC,IBOX,TCU
 SG_ RLY_AC : 6|1@1+ (1.0,0.0) [0.0|1.0] ""  DATC,IBOX,TCU
 SG_ F_SUB_TQI : 7|1@1+ (1.0,0.0) [0.0|1.0] ""  _4WD,ECS,EPB,ESC,IBOX,TCU
 SG_ TQI_ACOR : 8|8@1+ (0.390625,0.0) [0.0|99.6094] "%"  _4WD,EPB,ESC,IBOX,TCU
 SG_ N : 16|16@1+ (0.25,0.0) [0.0|16383.75] "rpm"  _4WD,ACU,AFLS,CLU,CUBIS,DATC,ECS,EPB,ESC,FPCM,IBOX,MDPS,SCC,TCU
 SG_ TQI : 32|8@1+ (0.390625,0.0) [0.0|99.6094] "%"  _4WD,ECS,EPB,ESC,IBOX,TCU
 SG_ TQFR : 40|8@1+ (0.390625,0.0) [0.0|99.6094] "%"  _4WD,EPB,ESC,IBOX,TCU
 SG_ VS : 48|8@1+ (1.0,0.0) [0.0|254.0] "km/h"  _4WD,AAF,ACU,AHLS,BCM,CLU,DATC,ECS,EPB,IBOX,LCA,LDWS_LKAS,LVR,MDPS,ODS,SCC,SMK,SPAS,TCU,TPMS
 SG_ RATIO_TQI_BAS_MAX_STND : 56|8@1+ (0.0078,0.0) [0.0|2.0] ""  _4WD,IBOX,TCU

BO_ 1301 CLU14: 8 CLU
 SG_ CF_Clu_ADrUNValueSet : 0|3@1+ (1.0,0.0) [0.0|7.0] ""  BCM
 SG_ CF_Clu_ADrLNValueSet : 3|3@1+ (1.0,0.0) [0.0|7.0] ""  BCM
 SG_ CF_Clu_EscortHLNValueSet : 6|2@1+ (1.0,0.0) [0.0|3.0] ""  BCM
 SG_ CF_Clu_DoorLSNValueSet : 8|3@1+ (1.0,0.0) [0.0|7.0] ""  BCM
 SG_ CF_Clu_PSMNValueSet : 11|3@1+ (1.0,0.0) [0.0|7.0] ""  BCM
 SG_ CF_Clu_TTUnlockNValueSet : 14|2@1+ (1.0,0.0) [0.0|3.0] ""  BCM
 SG_ CF_Clu_PTGMNValueSet : 16|2@1+ (1.0,0.0) [0.0|3.0] ""  BCM
 SG_ CF_Clu_SCMNValueSet : 18|2@1+ (1.0,0.0) [0.0|3.0] ""  BCM
 SG_ CF_Clu_WlightNValueSet : 20|2@1+ (1.0,0.0) [0.0|3.0] ""  BCM
 SG_ CF_Clu_TempUnitNValueSet : 22|2@1+ (1.0,0.0) [0.0|3.0] ""  BCM,DATC
 SG_ CF_Clu_MoodLpNValueSet : 24|3@1+ (1.0,0.0) [0.0|7.0] ""  BCM
 SG_ CF_Clu_TrfChgSet : 27|2@1+ (1.0,0.0) [0.0|3.0] ""  AFLS
 SG_ CF_Clu_OTTurnNValueSet : 29|3@1+ (1.0,0.0) [0.0|7.0] ""  BCM
 SG_ CF_Clu_LcaNValueSet : 32|2@1+ (1.0,0.0) [0.0|3.0] ""  LCA
 SG_ CF_Clu_RctaNValueSet : 34|2@1+ (1.0,0.0) [0.0|3.0] ""  LCA
 SG_ CF_Clu_RcwNValueSet : 36|2@1+ (1.0,0.0) [0.0|3.0] ""  LCA
 SG_ CF_Clu_EscOffNValueSet : 38|3@1+ (1.0,0.0) [0.0|7.0] ""  ESC
 SG_ CF_Clu_SccNaviCrvNValueSet : 41|2@1+ (1.0,0.0) [0.0|3.0] ""  SCC
 SG_ CF_Clu_SccNaviCamNValueSet : 43|2@1+ (1.0,0.0) [0.0|3.0] ""  SCC
 SG_ CF_Clu_SccAebNValueSet : 45|2@1+ (1.0,0.0) [0.0|3.0] ""  SCC
 SG_ CF_Clu_LkasModeNValueSet : 47|2@1+ (1.0,0.0) [0.0|3.0] ""  LDWS_LKAS
 SG_ CF_Clu_FcwNValueSet : 51|2@1+ (1.0,0.0) [0.0|3.0] ""  LDWS_LKAS
 SG_ CF_Clu_PasSpkrLvNValueSet : 53|3@1+ (1.0,0.0) [0.0|7.0] ""  BCM
 SG_ CF_Clu_SccDrvModeNValueSet : 56|3@1+ (1.0,0.0) [0.0|7.0] ""  SCC
 SG_ CF_Clu_HAnBNValueSet : 59|2@1+ (1.0,0.0) [0.0|3.0] ""  BCM
 SG_ CF_Clu_HfreeTrunkTgNValueSet : 61|3@1+ (1.0,0.0) [0.0|7.0] ""  BCM

BO_ 275 TCU13: 8 TCU
 SG_ N_TGT_LUP : 0|8@1+ (10.0,500.0) [500.0|3040.0] "rpm"  EMS,IBOX
 SG_ SLOPE_TCU : 8|6@1+ (0.5,-16.0) [-16.0|15.5] "%"  CLU,CUBIS,EMS,IBOX
 SG_ CF_Tcu_InhCda : 14|1@1+ (1.0,0.0) [0.0|1.0] ""  EMS,IBOX
 SG_ CF_Tcu_IsgInhib : 15|1@1+ (1.0,0.0) [0.0|1.0] ""  EMS,IBOX
 SG_ CF_Tcu_BkeOnReq : 16|2@1+ (1.0,0.0) [0.0|3.0] ""  EMS,IBOX
 SG_ CF_Tcu_NCStat : 18|2@1+ (1.0,0.0) [0.0|3.0] ""  EMS,IBOX
 SG_ CF_Tcu_TarGr : 20|4@1+ (1.0,0.0) [0.0|15.0] ""  _4WD,CLU,DATC,EMS,EPB,ESC,IBOX,SCC
 SG_ CF_Tcu_ShfPatt : 24|4@1+ (1.0,0.0) [0.0|15.0] ""  CLU,CUBIS,EMS,IBOX
 SG_ CF_Tcu_InhVis : 28|1@1+ (1.0,0.0) [0.0|1.0] ""  EMS,IBOX
 SG_ CF_Tcu_PRelReq : 29|1@1+ (1.0,0.0) [0.0|1.0] ""  IBOX,LVR
 SG_ CF_Tcu_ITPhase : 30|1@1+ (1.0,0.0) [0.0|1.0] ""  EMS,IBOX
 SG_ CF_Tcu_ActEcoRdy : 31|1@1+ (1.0,0.0) [0.0|1.0] ""  EMS,IBOX
 SG_ CF_Tcu_TqGrdLim : 32|8@1+ (10.0,0.0) [0.0|2540.0] "Nm/s"  EMS,IBOX
 SG_ CR_Tcu_IsgTgtRPM : 40|8@1+ (20.0,0.0) [0.0|3500.0] "rpm"  EMS,IBOX
 SG_ CF_Tcu_SptRdy : 48|1@1+ (1.0,0.0) [0.0|1.0] ""  CLU,IBOX
 SG_ CF_Tcu_SbwPInfo : 56|1@1+ (1.0,0.0) [0.0|1.0] ""  EMS,IBOX
 SG_ CF_Tcu_Alive3 : 58|2@1+ (1.0,0.0) [0.0|3.0] ""  EMS,IBOX
 SG_ CF_Tcu_ChkSum3 : 60|4@1+ (1.0,0.0) [0.0|15.0] ""  EMS,IBOX

BO_ 274 TCU12: 8 TCU
 SG_ ETL_TCU : 0|8@1+ (2.0,0.0) [0.0|508.0] "Nm"  EMS,IBOX
 SG_ CUR_GR : 8|4@1+ (1.0,0.0) [0.0|15.0] ""  _4WD,EMS,ESC,IBOX,SCC,TPMS
 SG_ CF_Tcu_Alive : 12|2@1+ (1.0,0.0) [0.0|3.0] ""  EMS,ESC,IBOX,SCC
 SG_ CF_Tcu_ChkSum : 14|2@1+ (1.0,0.0) [0.0|3.0] ""  EMS,ESC,IBOX,SCC
 SG_ VS_TCU : 16|8@1+ (1.0,0.0) [0.0|254.0] "km/h"  BCM,CLU,DATC,EMS,IBOX,LCA,LVR,PGS,SMK,SNV
 SG_ FUEL_CUT_TCU : 28|1@1+ (1.0,0.0) [0.0|1.0] ""  EMS,IBOX
 SG_ INH_FUEL_CUT : 29|1@1+ (1.0,0.0) [0.0|1.0] ""  EMS,IBOX
 SG_ IDLE_UP_TCU : 30|1@1+ (1.0,0.0) [0.0|1.0] ""  EMS,IBOX
 SG_ N_INC_TCU : 31|1@1+ (1.0,0.0) [0.0|1.0] ""  EMS,IBOX
 SG_ SPK_RTD_TCU : 32|8@1+ (0.375,-23.625) [-15.0|15.0] ""  EMS,IBOX
 SG_ N_TC_RAW : 40|16@1+ (0.25,0.0) [0.0|16383.5] "rpm"  EMS,IBOX
 SG_ VS_TCU_DECIMAL : 56|8@1+ (0.0078125,0.0) [0.0|0.9921875] "km/h"  CLU,EMS,IBOX,LCA

BO_ 273 TCU11: 8 TCU
 SG_ TQI_TCU_INC : 0|8@1+ (0.390625,0.0) [0.0|99.609375] "%"  EMS,ESC,IBOX
 SG_ G_SEL_DISP : 8|4@1+ (1.0,0.0) [0.0|15.0] ""  _4WD,AFLS,AVM,BCM,CGW,CLU,CUBIS,ECS,EMS,EPB,ESC,IAP,IBOX,LCA,LDWS_LKAS,LVR,MDPS,PGS,SCC,SMK,SNV,SPAS,TPMS
 SG_ F_TCU : 12|2@1+ (1.0,0.0) [0.0|3.0] ""  EMS,ESC,IBOX
 SG_ TCU_TYPE : 14|2@1+ (1.0,0.0) [0.0|3.0] ""  _4WD,EMS,ESC,IBOX
 SG_ TCU_OBD : 16|3@1+ (1.0,0.0) [0.0|7.0] ""  EMS,ESC,IBOX
 SG_ SWI_GS : 19|1@1+ (1.0,0.0) [0.0|1.0] ""  _4WD,EMS,EPB,ESC,IBOX,SCC
 SG_ GEAR_TYPE : 20|4@1+ (1.0,0.0) [0.0|15.0] ""  _4WD,CLU,EMS,ESC,IBOX,SCC
 SG_ TQI_TCU : 24|8@1+ (0.390625,0.0) [0.0|99.609375] "%"  EMS,ESC,IBOX
 SG_ TEMP_AT : 32|8@1+ (1.0,-40.0) [-40.0|214.0] "deg"  AAF,CLU,CUBIS,EMS,ESC,IBOX
 SG_ N_TC : 40|16@1+ (0.25,0.0) [0.0|16383.5] "rpm"  _4WD,EMS,EPB,ESC,IBOX
 SG_ SWI_CC : 56|2@1+ (1.0,0.0) [0.0|3.0] ""  _4WD,CLU,EMS,ESC,IBOX
 SG_ CF_Tcu_Alive1 : 58|2@1+ (1.0,0.0) [0.0|3.0] ""  EMS,IBOX
 SG_ CF_Tcu_ChkSum1 : 60|4@1+ (1.0,0.0) [0.0|15.0] ""  EMS,IBOX

BO_ 16 ACU13: 8 ACU
 SG_ CF_Acu_CshAct : 0|1@1+ (1.0,0.0) [0.0|1.0] ""  CUBIS,IBOX,ODS

BO_ 1040 CGW_USM1: 8 BCM
 SG_ CF_Gway_ATTurnRValue : 0|2@1+ (1.0,0.0) [0.0|3.0] ""  CLU
 SG_ CF_Gway_PTGMRValue : 2|2@1+ (1.0,0.0) [0.0|3.0] ""  CLU
 SG_ CF_Gway_EscortHLRValue : 4|2@1+ (1.0,0.0) [0.0|3.0] ""  CLU
 SG_ CF_Gway_TTUnlockRValue : 6|2@1+ (1.0,0.0) [0.0|3.0] ""  CLU
 SG_ CF_Gway_ADrLRValue : 8|3@1+ (1.0,0.0) [0.0|7.0] ""  CLU
 SG_ CF_Gway_ADrURValue : 11|3@1+ (1.0,0.0) [0.0|7.0] ""  CLU
 SG_ CF_Gway_SCMRValue : 14|2@1+ (1.0,0.0) [0.0|3.0] ""  CLU
 SG_ CF_Gway_WlightRValue : 16|2@1+ (1.0,0.0) [0.0|3.0] ""  CLU
 SG_ CF_Gway_PSMRValue : 18|3@1+ (1.0,0.0) [0.0|7.0] ""  CLU
 SG_ CF_Gway_OTTurnRValue : 21|3@1+ (1.0,0.0) [0.0|7.0] ""  CLU
 SG_ CF_Gway_DrLockSoundRValue : 24|3@1+ (1.0,0.0) [0.0|7.0] ""  CLU
 SG_ CF_Gway_HAnBRValue : 27|3@1+ (1.0,0.0) [0.0|7.0] ""  CLU
 SG_ CF_Gway_MoodLpRValue : 30|2@1+ (1.0,0.0) [0.0|3.0] ""  CLU
 SG_ CF_Gway_HfreeTrunkRValue : 32|3@1+ (1.0,0.0) [0.0|7.0] ""  CLU
 SG_ CF_Gway_AutoLightRValue : 35|3@1+ (1.0,0.0) [0.0|7.0] ""  CLU
 SG_ CF_Gway_RearWiperRValue : 38|2@1+ (1.0,0.0) [0.0|3.0] ""  CLU
 SG_ CF_Gway_PasSpkrLvRValue : 40|3@1+ (1.0,0.0) [0.0|7.0] ""  CLU

BO_ 1292 CLU13: 8 CLU
 SG_ CF_Clu_LowfuelWarn : 0|2@1+ (1.0,0.0) [0.0|3.0] ""  BCM,FPCM,IBOX
 SG_ CF_Clu_RefDetMod : 2|1@1+ (1.0,0.0) [0.0|1.0] ""  IBOX
 SG_ CF_Clu_AvgFCU : 3|2@1+ (1.0,0.0) [0.0|3.0] ""  IBOX
 SG_ CF_Clu_AvsmCur : 5|1@1+ (1.0,0.0) [0.0|1.0] ""  ESC,SCC
 SG_ CF_Clu_AvgFCI : 6|10@1+ (0.1,0.0) [0.0|102.2] ""  IBOX
 SG_ CF_Clu_DrivingModeSwi : 16|2@1+ (1.0,0.0) [0.0|3.0] ""  DATC,ECS,EMS,ESC,IAP,MDPS,TCU
 SG_ CF_Clu_FuelDispLvl : 18|5@1+ (1.0,0.0) [0.0|31.0] ""  CGW,IBOX
 SG_ CF_Clu_FlexSteerSW : 23|1@1+ (1.0,0.0) [0.0|1.0] ""  MDPS
 SG_ CF_Clu_DTE : 24|10@1+ (1.0,0.0) [0.0|1023.0] ""  DATC
 SG_ CF_Clu_TripUnit : 34|2@1+ (1.0,0.0) [0.0|3.0] ""  DATC
 SG_ CF_Clu_SWL_Stat : 36|3@1+ (1.0,0.0) [0.0|7.0] ""  ACU,EMS
 SG_ CF_Clu_ActiveEcoSW : 39|1@1+ (1.0,0.0) [0.0|1.0] ""  DATC,EMS,TCU
 SG_ CF_Clu_EcoDriveInf : 40|3@1+ (1.0,0.0) [0.0|7.0] ""  CUBIS,EMS,IAP,IBOX
 SG_ CF_Clu_IsaMainSW : 43|1@1+ (1.0,0.0) [0.0|1.0] ""  EMS
 SG_ CF_Clu_LdwsLkasSW : 56|1@1+ (1.0,0.0) [0.0|1.0] ""  LDWS_LKAS
 SG_ CF_Clu_AltLStatus : 59|1@1+ (1.0,0.0) [0.0|1.0] ""  BCM,DATC,EMS
 SG_ CF_Clu_AliveCnt2 : 60|4@1+ (1.0,0.0) [0.0|15.0] ""  EMS,LDWS_LKAS

BO_ 1290 SCC13: 8 SCC
 SG_ SCCDrvModeRValue : 0|3@1+ (1,0) [0|7] "" CLU
 SG_ SCC_Equip : 3|1@1+ (1,0) [0|1] "" ESC
 SG_ AebDrvSetStatus : 4|3@1+ (1,0) [0|7] "" CLU,ESC
 SG_ Lead_Veh_Dep_Alert_USM : 13|2@0+ (1,0) [0|3] "" XXX

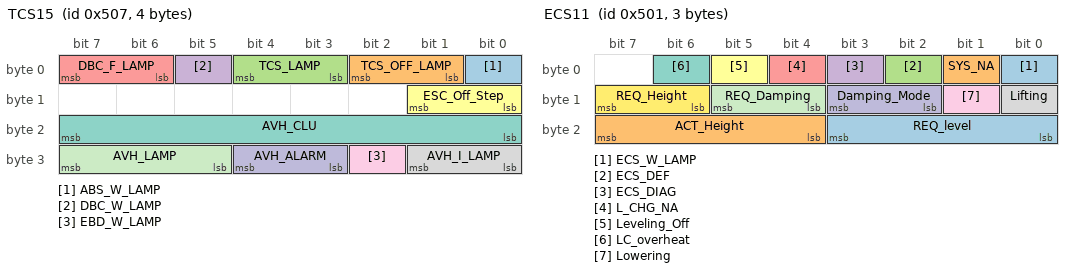
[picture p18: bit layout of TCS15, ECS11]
BO_ 1287 TCS15: 4 ESC
 SG_ ABS_W_LAMP : 0|1@1+ (1.0,0.0) [0.0|1.0] ""  _4WD,CLU,CUBIS,IBOX
 SG_ TCS_OFF_LAMP : 1|2@1+ (1.0,0.0) [0.0|1.0] ""  _4WD,ACU,CLU
 SG_ TCS_LAMP : 3|2@1+ (1.0,0.0) [0.0|3.0] ""  _4WD,ACU,CLU,CUBIS,IBOX,SCC
 SG_ DBC_W_LAMP : 5|1@1+ (1.0,0.0) [0.0|1.0] ""  _4WD,CLU
 SG_ DBC_F_LAMP : 6|2@1+ (1.0,0.0) [0.0|3.0] ""  _4WD,CLU
 SG_ ESC_Off_Step : 8|2@1+ (1.0,0.0) [0.0|3.0] ""  CLU
 SG_ AVH_CLU : 16|8@1+ (1.0,0.0) [0.0|255.0] ""  CLU,EPB
 SG_ AVH_I_LAMP : 24|2@1+ (1.0,0.0) [0.0|3.0] ""  EPB
 SG_ EBD_W_LAMP : 26|1@1+ (1.0,0.0) [0.0|1.0] ""  _4WD,CLU
 SG_ AVH_ALARM : 27|2@1+ (1.0,0.0) [0.0|3.0] ""  CLU
 SG_ AVH_LAMP : 29|3@1+ (1.0,0.0) [0.0|7.0] ""  CLU,EPB,SPAS

BO_ 1282 TCU14: 4 TCU
 SG_ CF_TCU_WarnMsg : 0|3@1+ (1.0,0.0) [0.0|7.0] ""  CLU
 SG_ CF_TCU_WarnImg : 3|1@1+ (1.0,0.0) [0.0|1.0] ""  CLU
 SG_ CF_TCU_WarnSnd : 4|1@1+ (1.0,0.0) [0.0|1.0] ""  CLU
 SG_ CF_Tcu_GSel_BlinkReq : 5|1@1+ (1.0,0.0) [0.0|1.0] ""  CLU,LVR
 SG_ CF_Tcu_StRelStat : 12|1@1+ (1.0,0.0) [0.0|1.0] ""  CLU,EMS,ESC
 SG_ CF_Tcu_DriWarn1 : 13|3@1+ (1.0,0.0) [0.0|7.0] ""  CLU,EMS,ESC
 SG_ CF_Tcu_DriWarn2 : 16|2@1+ (1.0,0.0) [0.0|3.0] ""  CLU,EMS,ESC

BO_ 1281 ECS11: 3 ECS
 SG_ ECS_W_LAMP : 0|1@1+ (1.0,0.0) [0.0|1.0] ""  CLU,CUBIS,IBOX
 SG_ SYS_NA : 1|1@1+ (1.0,0.0) [0.0|1.0] ""  CLU
 SG_ ECS_DEF : 2|1@1+ (1.0,0.0) [0.0|1.0] ""  CLU
 SG_ ECS_DIAG : 3|1@1+ (1.0,0.0) [0.0|1.0] ""  CLU
 SG_ L_CHG_NA : 4|1@1+ (1.0,0.0) [0.0|1.0] ""  CLU
 SG_ Leveling_Off : 5|1@1+ (1.0,0.0) [0.0|1.0] ""  CLU
 SG_ LC_overheat : 6|1@1+ (1.0,0.0) [0.0|1.0] ""  CLU
 SG_ Lifting : 8|1@1+ (1.0,0.0) [0.0|1.0] ""  CLU
 SG_ Lowering : 9|1@1+ (1.0,0.0) [0.0|1.0] ""  CLU
 SG_ Damping_Mode : 10|2@1+ (1.0,0.0) [0.0|3.0] ""  CLU
 SG_ REQ_Damping : 12|2@1+ (1.0,0.0) [0.0|3.0] ""  CLU
 SG_ REQ_Height : 14|2@1+ (1.0,0.0) [0.0|3.0] ""  CLU
 SG_ REQ_level : 16|4@1+ (1.0,0.0) [0.0|15.0] ""  CLU
 SG_ ACT_Height : 20|4@1+ (1.0,0.0) [0.0|15.0] ""  CLU

BO_ 1024 CLU_CFG11: 2 CLU
 SG_ Vehicle_Type : 0|16@1+ (1.0,0.0) [0.0|65536.0] ""  _4WD

BO_ 1280 ACU14: 1 ACU
 SG_ CF_SWL_Ind : 0|2@1+ (1.0,0.0) [0.0|3.0] ""  CLU
 SG_ CF_TTL_Ind : 2|2@1+ (1.0,0.0) [0.0|3.0] ""  CLU
 SG_ CF_SBR_Ind : 4|2@1+ (1.0,0.0) [0.0|3.0] ""  BCM,CLU

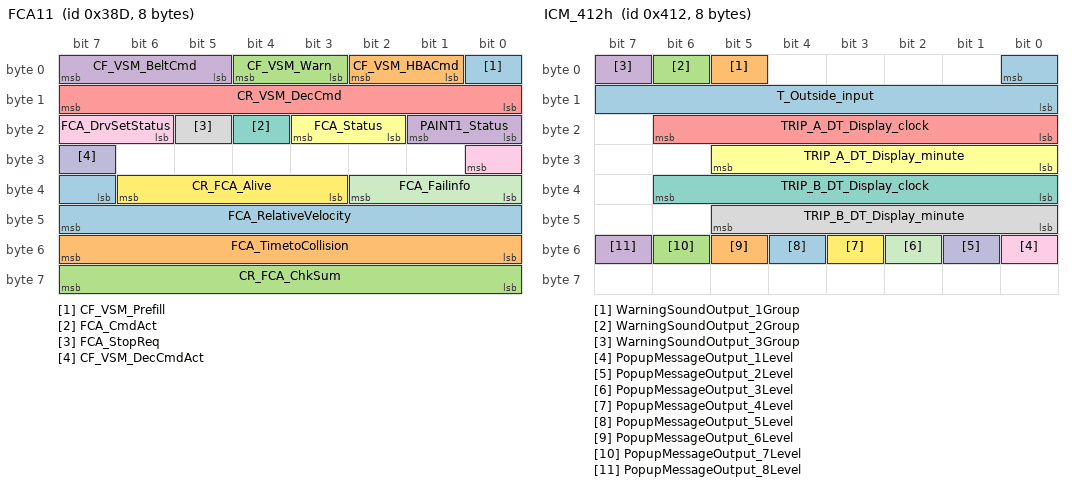
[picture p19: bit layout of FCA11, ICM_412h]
BO_ 909 FCA11: 8 FCA
 SG_ CF_VSM_Prefill : 0|1@1+ (1,0) [0|1] "" ESC
 SG_ CF_VSM_HBACmd : 1|2@1+ (1,0) [0|3] "" ESC
 SG_ CF_VSM_Warn : 3|2@1+ (1,0) [0|3] "" ACU,CLU,ESC
 SG_ CF_VSM_BeltCmd : 5|3@1+ (1,0) [0|7] "" ESC
 SG_ CR_VSM_DecCmd : 8|8@1+ (0.01,0) [0|2.55] "g" ESC
 SG_ FCA_Status : 18|2@1+ (1,0) [0|3] "" ACU,CLU,ESC
 SG_ FCA_CmdAct : 20|1@1+ (1,0) [0|1] "" ESC
 SG_ FCA_StopReq : 21|1@1+ (1,0) [0|1] "" CLU,ESC
 SG_ FCA_DrvSetStatus : 22|3@1+ (1,0) [0|7] "" CLU,ESC
 SG_ CF_VSM_DecCmdAct : 31|1@1+ (1,0) [0|1] "" ESC
 SG_ FCA_Failinfo : 32|3@1+ (1,0) [0|7] "" ACU,CLU,ESC
 SG_ CR_FCA_Alive : 35|4@1+ (1,0) [0|15] "" ESC
 SG_ FCA_RelativeVelocity : 39|9@1+ (0.1,-25.5) [-25.5|25.5] "m/s" iBAU
 SG_ FCA_TimetoCollision : 48|8@1+ (10,0) [0|2540] "ms" iBAU
 SG_ CR_FCA_ChkSum : 56|8@1+ (1,0) [0|255] "" ESC
 SG_ PAINT1_Status : 16|2@1+ (1,0) [0|1] "" XXX

BO_ 1156 HDA11_MFC: 8 XXX
 SG_ Counter : 5|4@0+ (1,0) [0|15] "" XXX
 SG_ NEW_SIGNAL_1 : 1|2@0+ (1,0) [0|255] "" XXX
 SG_ NEW_SIGNAL_2 : 7|2@0+ (1,0) [0|3] "" XXX
 SG_ NEW_SIGNAL_3 : 15|8@0+ (1,0) [0|255] "" XXX
 SG_ NEW_SIGNAL_4 : 16|2@1+ (1,0) [0|3] "" XXX
 SG_ NEW_SIGNAL_5 : 18|14@1+ (1,0) [0|63] "" XXX
 SG_ NEW_SIGNAL_6 : 33|2@0+ (1,0) [0|1] "" XXX
 SG_ NEW_SIGNAL_7 : 34|14@1+ (1,0) [0|16383] "" XXX
 SG_ NEW_SIGNAL_8 : 49|2@0+ (1,0) [0|1] "" XXX
 SG_ NEW_SIGNAL_9 : 50|14@1- (1,-4095) [0|16383] "" XXX

BO_ 1155 FCA12: 8 FCA
 SG_ FCA_USM : 0|3@1+ (1,0) [0|7] "" CGW,CLU,ESC
 SG_ FCA_DrvSetState : 3|3@1+ (1,0) [0|7] "" CGW

BO_ 1186 FRT_RADAR11: 2 FCA
 SG_ CF_FCA_Equip_Front_Radar : 0|3@1+ (1,0) [0|7] "" LDWS_LKAS,LDW_LKA,ESC

BO_ 905 SCC14: 8 SCC
 SG_ ComfortBandUpper : 0|6@1+ (0.02,0) [0|1.26] "m/s^2" ESC
 SG_ ComfortBandLower : 6|6@1+ (0.02,0) [0|1.26] "m/s^2" ESC
 SG_ JerkUpperLimit : 12|7@1+ (0.1,0) [0|12.7] "m/s^3" ESC
 SG_ JerkLowerLimit : 19|7@1+ (0.1,0) [0|12.7] "m/s^3" ESC
 SG_ ACCMode : 32|3@1+ (1,0) [0|7] "" CLU,HUD,LDWS_LKAS,ESC
 SG_ ObjDistStat : 42|2@1+ (1,0) [0|3] "" XXX
 SG_ ObjGap : 56|8@1+ (1,0) [0|255] "" CLU,HUD,ESC

BO_ 1157 LFAHDA_MFC: 4 XXX
 SG_ HDA_USM : 0|2@1+ (1,0) [0|3] "" XXX
 SG_ HDA_Active : 2|1@1+ (1,0) [0|1] "" XXX
 SG_ HDA_Icon_State : 3|2@1+ (1,0) [0|3] "" XXX
 SG_ HDA_Chime : 7|1@1+ (1,0) [0|1] "" XXX
 SG_ HDA_VSetReq : 8|8@1+ (1,0) [0|255] "km/h" XXX
 SG_ LFA_SysWarning : 16|3@1+ (1,0) [0|7] "" XXX
 SG_ NEW_SIGNAL_1 : 20|3@1+ (1,0) [0|7] "" XXX
 SG_ LFA_Icon_State : 24|2@1+ (1,0) [0|3] "" XXX
 SG_ LFA_USM : 27|2@1+ (1,0) [0|3] "" XXX
 SG_ HDA_SysWarning : 29|2@1+ (1,0) [0|3] "" XXX

BO_ 913 BCM_PO_11: 8 Vector__XXX
 SG_ BCM_Door_Dri_Status : 5|1@0+ (1,0) [0|1] "" PT_ESC_ABS
 SG_ BCM_Shift_R_MT_SW_Status : 39|2@0+ (1,0) [0|3] "" PT_ESC_ABS
 SG_ LFA_Pressed : 4|1@0+ (1,0) [0|1] "" XXX

BO_ 1426 LABEL11: 8 XXX
 SG_ CC_React : 34|1@1+ (1,0) [0|1] "" XXX

BO_ 910 WHL_SPD12_FS: 5 iBAU
 SG_ CRC : 0|8@1+ (1,0) [0|0] "" Vector__XXX
 SG_ WHL_SPD12_AliveCounter : 8|4@1+ (1,0) [0|15] "" Vector__XXX
 SG_ WHL_SPD_FL : 12|14@1+ (0.03125,0) [0|511.96875] "km/h" Vector__XXX
 SG_ WHL_SPD_FR : 26|14@1+ (0.03125,0) [0|511.96875] "km/h" Vector__XXX

BO_ 911 WHL_SPD13_FS: 5 iBAU
 SG_ CRC : 0|8@1+ (1,0) [0|0] "" Vector__XXX
 SG_ WHL_SPD13_AliveCounter : 8|4@1+ (1,0) [0|15] "" Vector__XXX
 SG_ WHL_SPD_RL : 12|14@1+ (0.03125,0) [0|511.96875] "km/h" Vector__XXX
 SG_ WHL_SPD_RR : 26|14@1+ (0.03125,0) [0|511.96875] "km/h" Vector__XXX

BO_ 865 ADAS_PRK_11: 8 ADAS_PRK
 SG_ CF_PCA_BrkReq : 24|1@1+ (1,0) [0|0] "" Vector__XXX
 SG_ CF_PCA_DclTrgtVal : 28|4@1+ (0.04,0) [0|0] "g" Vector__XXX
 SG_ PCA_ALIVE_CNT : 40|4@1+ (1,0) [0|0] "" Vector__XXX
 SG_ PCA_CHECK_SUM : 48|8@1+ (1,0) [0|0] "" Vector__XXX

BO_ 882 ELECT_GEAR: 8 XXX
 SG_ Elect_Gear_Shifter : 16|4@1+ (1,0) [0|7] ""  CLU

BO_ 881 E_EMS11: 8 XXX
 SG_ Brake_Pedal_Pos : 0|8@1+ (1,0) [0|127] "" XXX
 SG_ IG_Reactive_Stat : 8|3@1+ (1,0) [0|3] "" XXX
 SG_ Gear_Change : 12|1@0+ (1,0) [0|31] "" XXX
 SG_ Cruise_Limit_Status : 13|1@1+ (1,0) [0|1] "" XXX
 SG_ Cruise_Limit_Target : 23|8@1+ (1,0) [0|15] "" XXX
 SG_ Accel_Pedal_Pos : 31|8@1+ (1,0) [0|254] "" XXX
 SG_ CR_Vcu_AccPedDep_Pos : 56|8@1+ (1,0) [0|254] "" XXX

BO_ 1355 EV_PC6: 8 CGW
 SG_ CF_Vcu_SbwWarnMsg : 16|3@1+ (1,0) [0|7] "" Vector__XXX

BO_ 1430 EV_PC2: 8 CGW
 SG_ CR_Ldc_ActVol_LS_V : 32|8@1+ (0.1,0) [0|0] "V" Vector__XXX

BO_ 1535 EV_PC10: 8 CGW
 SG_ CF_Vcu_EpbRequest : 37|1@1+ (1,0) [0|0] "" Vector__XXX

BO_ 908 RSPA11: 8 RSPA
 SG_ CF_RSPA_State : 0|4@1+ (1,0) [0|15] "" XXX
 SG_ CF_RSPA_Act : 4|2@1+ (1,0) [0|3] "" XXX
 SG_ CF_RSPA_DecCmd : 6|2@1+ (1,0) [0|3] "" XXX
 SG_ CF_RSPA_Trgt_Spd : 8|10@1+ (0.01,0) [0|10.23] "km/h" XXX
 SG_ CF_RSPA_StopReq : 18|1@1+ (1,0) [0|2] "" XXX
 SG_ CR_RSPA_EPB_Req : 22|2@1+ (1,0) [0|3] "" XXX
 SG_ CF_RSPA_ACC_ACT : 50|1@1+ (1,0) [0|2] "" XXX
 SG_ CF_RSPA_AliveCounter : 52|4@1+ (1,0) [0|15] "" XXX
 SG_ CF_RSPA_CRC : 56|8@1+ (1,0) [0|255] "" XXX

BO_ 914 S_MDPS11: 8 XXX
 SG_ CF_Mdps_Stat : 0|4@1+ (1,0) [0|15] "" XXX
 SG_ CR_Mdps_DrvTq : 8|12@1+ (1,0) [0|15] "" XXX
 SG_ CR_Mdps_StrAng : 24|16@1- (1,0) [0|65535] "" XXX
 SG_ CF_Mdps_AliveCnt : 47|8@0+ (1,0) [0|255] "" XXX
 SG_ CF_Mdps_Chksum : 63|8@0+ (1,0) [0|255] "" XXX

BO_ 1191 MFC_4a7: 8 XXX
 SG_ PAINT1 : 0|1@0+ (1,0) [0|1] "" XXX

BO_ 1162 BCA11: 8 BCW
 SG_ CF_BCA_State : 16|3@1+ (1,0) [0|7] "" CLU,iBAU
 SG_ CF_BCA_Warning : 19|2@1+ (1,0) [0|3] "" CLU,iBAU
 SG_ AliveCounter : 21|4@1+ (1,0) [0|15] "" CLU,iBAU
 SG_ RCCA_Brake_Command : 29|1@1+ (1,0) [0|1] "" iBAU
 SG_ Check_Sum : 56|8@1+ (1,0) [0|16] "" iBAU

BO_ 1136 P_STS: 8 CGW
 SG_ HCU1_STS : 6|2@1+ (1,0) [0|3] "" BCW,EPB,FCA,MDPS,SCC,iBAU
 SG_ HCU5_STS : 8|2@1+ (1,0) [0|3] "" EPB,FCA,MDPS,iBAU
 SG_ Counter : 58|4@1+ (1,0) [0|15] "" MDPS
 SG_ Checksum : 62|2@1+ (1,0) [0|3] "" MDPS

BO_ 320 YRS12: 8 ACU
 SG_ CF_Yrs_LongAcStat : 16|4@1+ (1,0) [0|15] "" iBAU
 SG_ CF_IMU_ResetStat : 20|4@1+ (1,0) [0|15] "" iBAU
 SG_ YRS_Temp : 24|8@1+ (1,-68) [-68|187] "" iBAU
 SG_ YRS_TempStat : 32|4@1+ (1,0) [0|15] "" iBAU
 SG_ CF_Yrs_Type : 36|4@1+ (1,0) [0|15] "" iBAU
 SG_ CR_Yrs_MsgCnt2 : 48|4@1+ (1,0) [0|15] "" iBAU
 SG_ CR_Yrs_Crc2 : 56|8@1+ (1,0) [0|255] "" iBAU
 SG_ CR_Yrs_LongAc : 0|16@1+ (0.000127465,-4.17677312) [-4.17677312|4.17651819] "g" CGW,iBAU

BO_ 1173 YRS13: 8 ACU
 SG_ YRS_SeralNo : 16|48@1+ (1,0) [0|281474976710655] "" iBAU

BO_ 870 EMS_366: 8 EMS
 SG_ TQI_1 : 0|8@1+ (0.390625,0) [0|99.6094] "%" MDPS
 SG_ N : 8|16@1+ (0.25,0.0) [0.0|16383.75] "rpm" MDPS
 SG_ TQI_2 : 24|8@1+ (0.390625,0) [0|99.6094] "%" MDPS
 SG_ VS : 40|8@1+ (1,0) [0|255] "km/h" MDPS
 SG_ SWI_IGK : 48|1@0+ (1,0) [0|1] "" XXX

BO_ 854 M_356: 8 XXX
 SG_ PAINT1 : 32|1@0+ (1,0) [0|1] "" XXX
 SG_ PAINT2 : 34|2@0+ (1,0) [0|1] "" XXX
 SG_ PAINT3 : 36|2@0+ (1,0) [0|3] "" XXX
 SG_ PAINT4 : 38|1@0+ (1,0) [0|1] "" XXX

BO_ 1042 ICM_412h: 8 ICM
 SG_ T_Outside_input : 0|9@0+ (0.01,0) [0|5] "V" Vector__XXX
 SG_ WarningSoundOutput_1Group : 5|1@0+ (1,0) [0|1] "" Vector__XXX
 SG_ WarningSoundOutput_2Group : 6|1@0+ (1,0) [0|1] "" Vector__XXX
 SG_ WarningSoundOutput_3Group : 7|1@0+ (1,0) [0|1] "" Vector__XXX
 SG_ TRIP_A_DT_Display_clock : 22|7@0+ (1,0) [0|99] "clock" Vector__XXX
 SG_ TRIP_A_DT_Display_minute : 29|6@0+ (1,0) [0|59] "minute" Vector__XXX
 SG_ TRIP_B_DT_Display_clock : 38|7@0+ (1,0) [0|99] "clock" Vector__XXX
 SG_ TRIP_B_DT_Display_minute : 45|6@0+ (1,0) [0|59] "minute" Vector__XXX
 SG_ PopupMessageOutput_1Level : 48|1@0+ (1,0) [0|1] "" Vector__XXX
 SG_ PopupMessageOutput_2Level : 49|1@0+ (1,0) [0|1] "" Vector__XXX
 SG_ PopupMessageOutput_3Level : 50|1@0+ (1,0) [0|1] "" Vector__XXX
 SG_ PopupMessageOutput_4Level : 51|1@0+ (1,0) [0|1] "" Vector__XXX
 SG_ PopupMessageOutput_5Level : 52|1@0+ (1,0) [0|1] "" Vector__XXX
 SG_ PopupMessageOutput_6Level : 53|1@0+ (1,0) [0|1] "" Vector__XXX
 SG_ PopupMessageOutput_7Level : 54|1@0+ (1,0) [0|1] "" Vector__XXX
 SG_ PopupMessageOutput_8Level : 55|1@0+ (1,0) [0|1] "" Vector__XXX

BO_ 1348 Navi_HU: 8 XXX
 SG_ SpeedLim_Nav_Clu : 7|8@0+ (1,0) [0|255] "" XXX
 SG_ SpeedLim_Nav_General : 29|1@0+ (1,0) [0|1] "" XXX
 SG_ SpeedLim_Nav_Cam : 30|1@0+ (1,0) [0|1] "" XXX

CM_ SG_ 1056 SCCInfoDisplay "Goes to 1 for a second while transitioning from Cruise Control to No Message";
CM_ SG_ 1348 SpeedLim_Nav_Clu "Speed limit displayed on Nav, Cluster and HUD";
